VERSION ""

NS_ :

BS_:

BU_: RLPSU DPSU APSU PSB SHVU_RR vHS_B2 FCS EMCU SLB RCM CGW_CCU vDummy_HS_B ATS RLHV PFSU SGU ALBCU DSAU SWRC SHVU_FR RCS RRPSU BLTN_CAM SCM DLBCU OHCL RWPC RRHV WPC HOD ASAU

BO_ 934 PTGM_01_200ms: 8 CGW_CCU
 SG_ PTGM_Crc1Val : 0|8@1+ (1,0) [0|0] ""  Vector__XXX
 SG_ PTGM_AlvCnt1Val : 12|4@1+ (1,0) [0|0] ""  Vector__XXX
 SG_ PTGM_HazardSta : 16|2@1+ (1,0) [0|0] ""  Vector__XXX
 SG_ PTGM_ModSta : 18|2@1+ (1,0) [0|0] ""  Vector__XXX
 SG_ PTGM_MovSta : 20|2@1+ (1,0) [0|0] ""  Vector__XXX
 SG_ PTGM_OptTyp : 22|2@1+ (1,0) [0|0] ""  Vector__XXX
 SG_ PTGM_ReleaseRlySta : 24|2@1+ (1,0) [0|0] ""  APSU,PFSU
 SG_ PTGM_TrnkLkSwSta : 26|2@1+ (1,0) [0|0] ""  Vector__XXX
 SG_ PTGM_UsmSetSta : 28|2@1+ (1,0) [0|0] ""  Vector__XXX
 SG_ PTGM_HeightRValue : 32|3@1+ (1,0) [0|0] ""  Vector__XXX
 SG_ PTGM_OpnClsState : 35|4@1+ (1,0) [0|0] ""  Vector__XXX
 SG_ PTGM_CmdWarn : 40|3@1+ (1,0) [0|0] ""  Vector__XXX
 SG_ PTGM_AntiPinchSnsr : 43|2@1+ (1,0) [0|0] ""  Vector__XXX
 SG_ PTGM_FobSrch_Req : 52|2@1+ (1,0) [0|0] ""  Vector__XXX
 SG_ PTGM_TlgtAwayCloseRValue : 54|2@1+ (1,0) [0|0] ""  Vector__XXX
 SG_ PTGM_TrnkTlgtOption : 56|2@1+ (1,0) [0|0] ""  Vector__XXX
 SG_ PTGM_LatchType : 58|2@1+ (1,0) [0|0] ""  Vector__XXX
 SG_ PTGM_SpeedRValue : 8|4@1+ (1,0) [0|0] ""  Vector__XXX

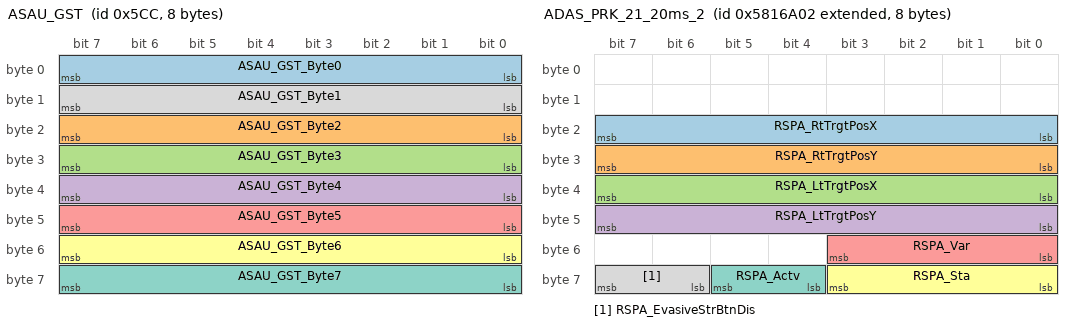
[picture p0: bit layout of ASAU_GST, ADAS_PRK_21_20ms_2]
BO_ 1484 ASAU_GST: 8 ASAU
 SG_ ASAU_GST_Byte0 : 0|8@1+ (1,0) [0|0] ""  CGW_CCU
 SG_ ASAU_GST_Byte2 : 16|8@1+ (1,0) [0|0] ""  CGW_CCU
 SG_ ASAU_GST_Byte3 : 24|8@1+ (1,0) [0|0] ""  CGW_CCU
 SG_ ASAU_GST_Byte4 : 32|8@1+ (1,0) [0|0] ""  CGW_CCU
 SG_ ASAU_GST_Byte5 : 40|8@1+ (1,0) [0|0] ""  CGW_CCU
 SG_ ASAU_GST_Byte6 : 48|8@1+ (1,0) [0|0] ""  CGW_CCU
 SG_ ASAU_GST_Byte7 : 56|8@1+ (1,0) [0|0] ""  CGW_CCU
 SG_ ASAU_GST_Byte1 : 8|8@1+ (1,0) [0|0] ""  CGW_CCU

BO_ 929 SCM_03_200ms: 8 SCM
 SG_ SCM_Opt : 0|2@1+ (1,0) [0|0] ""  DPSU,CGW_CCU
 SG_ Tilt_VirtualLimExist : 10|2@1+ (1,0) [0|0] ""  CGW_CCU
 SG_ Tele_Snsr_Err : 12|2@1+ (1,0) [0|0] ""  CGW_CCU
 SG_ Tele_VirtualLim : 14|2@1+ (1,0) [0|0] ""  CGW_CCU
 SG_ Tele_VirtualLimExist : 16|2@1+ (1,0) [0|0] ""  CGW_CCU
 SG_ TiltTele_Profile1MemoryExist : 18|2@1+ (1,0) [0|0] ""  CGW_CCU
 SG_ Tilt_MnlSwSta : 2|2@1+ (1,0) [0|0] ""  CGW_CCU
 SG_ TiltTele_Profile2MemoryExist : 20|2@1+ (1,0) [0|0] ""  CGW_CCU
 SG_ TiltTele_GuestMemoryExist : 22|2@1+ (1,0) [0|0] ""  CGW_CCU
 SG_ TiltTele_IMS1MemoryExist : 24|2@1+ (1,0) [0|0] ""  CGW_CCU
 SG_ TiltTele_IMS2MemoryExist : 26|2@1+ (1,0) [0|0] ""  CGW_CCU
 SG_ TiltTele_IMS3MemoryExist : 28|2@1+ (1,0) [0|0] ""  CGW_CCU
 SG_ TiltTele_ReturnMemoryExist : 30|2@1+ (1,0) [0|0] ""  CGW_CCU
 SG_ Tilt_OpSta : 32|2@1+ (1,0) [0|0] ""  CGW_CCU
 SG_ Tele_OpSta : 34|2@1+ (1,0) [0|0] ""  CGW_CCU
 SG_ Tele_MnlSwSta : 4|2@1+ (1,0) [0|0] ""  CGW_CCU
 SG_ Tilt_SnsrErr : 6|2@1+ (1,0) [0|0] ""  CGW_CCU
 SG_ Tilt_VirtualLim : 8|2@1+ (1,0) [0|0] ""  CGW_CCU

BO_ 2239851010 ADAS_PRK_21_20ms_2: 8 CGW_CCU
 SG_ RSPA_RtTrgtPosX : 16|8@1- (0.05,0) [0|0] "m"  Vector__XXX
 SG_ RSPA_RtTrgtPosY : 24|8@1- (0.05,0) [0|0] "m"  Vector__XXX
 SG_ RSPA_LtTrgtPosX : 32|8@1- (0.05,0) [0|0] "m"  Vector__XXX
 SG_ RSPA_LtTrgtPosY : 40|8@1- (0.05,0) [0|0] "m"  Vector__XXX
 SG_ RSPA_Var : 48|4@1+ (1,0) [0|0] ""  Vector__XXX
 SG_ RSPA_Sta : 56|4@1+ (1,0) [0|0] ""  Vector__XXX
 SG_ RSPA_Actv : 60|2@1+ (1,0) [0|0] ""  Vector__XXX
 SG_ RSPA_EvasiveStrBtnDis : 62|2@1+ (1,0) [0|0] ""  Vector__XXX

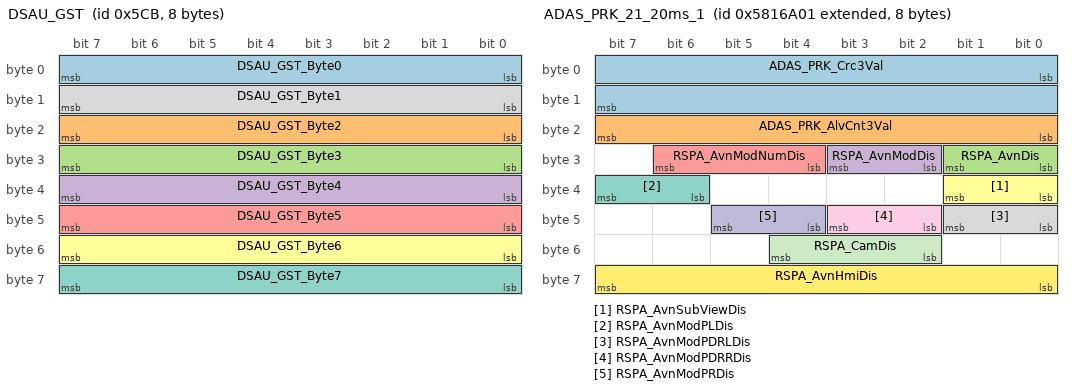
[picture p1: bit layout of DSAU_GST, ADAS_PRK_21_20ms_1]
BO_ 1483 DSAU_GST: 8 DSAU
 SG_ DSAU_GST_Byte0 : 0|8@1+ (1,0) [0|0] ""  CGW_CCU
 SG_ DSAU_GST_Byte2 : 16|8@1+ (1,0) [0|0] ""  CGW_CCU
 SG_ DSAU_GST_Byte3 : 24|8@1+ (1,0) [0|0] ""  CGW_CCU
 SG_ DSAU_GST_Byte4 : 32|8@1+ (1,0) [0|0] ""  CGW_CCU
 SG_ DSAU_GST_Byte5 : 40|8@1+ (1,0) [0|0] ""  CGW_CCU
 SG_ DSAU_GST_Byte6 : 48|8@1+ (1,0) [0|0] ""  CGW_CCU
 SG_ DSAU_GST_Byte7 : 56|8@1+ (1,0) [0|0] ""  CGW_CCU
 SG_ DSAU_GST_Byte1 : 8|8@1+ (1,0) [0|0] ""  CGW_CCU

BO_ 2239851011 ADAS_PRK_21_20ms_3: 8 CGW_CCU
 SG_ RSPA_TrgtGearSta : 0|3@1+ (1,0) [0|0] ""  Vector__XXX
 SG_ RSPA_IdOutWarnReq : 10|2@1+ (1,0) [0|0] ""  DPSU
 SG_ RSPA_IndBlnkReq : 12|3@1+ (1,0) [0|0] ""  Vector__XXX
 SG_ RSPA_SysOff : 15|1@1+ (1,0) [0|0] ""  Vector__XXX
 SG_ RSPA_DccCmd : 16|2@1+ (1,0) [0|0] ""  Vector__XXX
 SG_ RSPA_StopReq : 18|2@1+ (1,0) [0|0] ""  Vector__XXX
 SG_ RSPA_SelDevInfo : 20|2@1+ (1,0) [0|0] ""  Vector__XXX
 SG_ RSPA_SelFuncInfo : 22|2@1+ (1,0) [0|0] ""  Vector__XXX
 SG_ RSPA_TrgtVehSpdVal : 24|10@1+ (0.01,0) [0|0] "km/h"  Vector__XXX
 SG_ RSPA_EpbReq : 3|2@1+ (1,0) [0|0] ""  Vector__XXX
 SG_ RSPA_AddtnlAccelActv : 34|2@1+ (1,0) [0|0] ""  Vector__XXX
 SG_ RSPA_Opt : 36|2@1+ (1,0) [0|0] ""  Vector__XXX
 SG_ RSPA_RmtPrlExitDis : 38|2@1+ (1,0) [0|0] ""  Vector__XXX
 SG_ RSPA_TrgtTqVal : 40|12@1- (1,0) [0|0] "Nm"  Vector__XXX
 SG_ RSPA_ExtLampReq : 5|3@1+ (1,0) [0|0] ""  Vector__XXX
 SG_ RSPA_UppLtTypDis : 52|3@1+ (1,0) [0|0] ""  Vector__XXX
 SG_ RSPA_LwrLtTypDis : 55|3@1+ (1,0) [0|0] ""  Vector__XXX
 SG_ RSPA_UppRtTypDis : 58|3@1+ (1,0) [0|0] ""  Vector__XXX
 SG_ RSPA_LwrRtTypDis : 61|3@1+ (1,0) [0|0] ""  Vector__XXX
 SG_ RSPA_CrankingReq : 8|2@1+ (1,0) [0|0] ""  Vector__XXX

BO_ 2239851009 ADAS_PRK_21_20ms_1: 8 CGW_CCU
 SG_ ADAS_PRK_Crc3Val : 0|16@1+ (1,0) [0|0] ""  Vector__XXX
 SG_ ADAS_PRK_AlvCnt3Val : 16|8@1+ (1,0) [0|0] ""  Vector__XXX
 SG_ RSPA_AvnDis : 24|2@1+ (1,0) [0|0] ""  Vector__XXX
 SG_ RSPA_AvnModDis : 26|2@1+ (1,0) [0|0] ""  Vector__XXX
 SG_ RSPA_AvnModNumDis : 28|3@1+ (1,0) [0|0] ""  Vector__XXX
 SG_ RSPA_AvnSubViewDis : 32|2@1+ (1,0) [0|0] ""  Vector__XXX
 SG_ RSPA_AvnModPLDis : 38|2@1+ (1,0) [0|0] ""  Vector__XXX
 SG_ RSPA_AvnModPDRLDis : 40|2@1+ (1,0) [0|0] ""  Vector__XXX
 SG_ RSPA_AvnModPDRRDis : 42|2@1+ (1,0) [0|0] ""  Vector__XXX
 SG_ RSPA_AvnModPRDis : 44|2@1+ (1,0) [0|0] ""  Vector__XXX
 SG_ RSPA_CamDis : 50|3@1+ (1,0) [0|0] ""  Vector__XXX
 SG_ RSPA_AvnHmiDis : 56|8@1+ (1,0) [0|0] ""  Vector__XXX

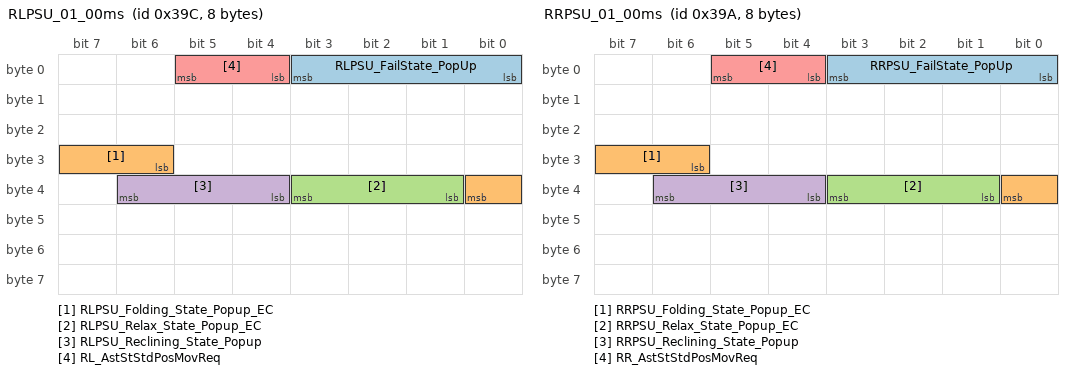
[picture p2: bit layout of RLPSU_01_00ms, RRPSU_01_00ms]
BO_ 924 RLPSU_01_00ms: 8 RLPSU
 SG_ RLPSU_FailState_PopUp : 0|4@1+ (1,0) [0|0] ""  CGW_CCU
 SG_ RLPSU_Folding_State_Popup_EC : 30|3@1+ (1,0) [0|0] ""  CGW_CCU
 SG_ RLPSU_Relax_State_Popup_EC : 33|3@1+ (1,0) [0|0] ""  CGW_CCU
 SG_ RLPSU_Reclining_State_Popup : 36|3@1+ (1,0) [0|0] ""  Vector__XXX
 SG_ RL_AstStStdPosMovReq : 4|2@1+ (1,0) [0|0] ""  APSU

BO_ 922 RRPSU_01_00ms: 8 RRPSU
 SG_ RRPSU_FailState_PopUp : 0|4@1+ (1,0) [0|0] ""  CGW_CCU
 SG_ RRPSU_Folding_State_Popup_EC : 30|3@1+ (1,0) [0|0] ""  CGW_CCU
 SG_ RRPSU_Relax_State_Popup_EC : 33|3@1+ (1,0) [0|0] ""  CGW_CCU
 SG_ RRPSU_Reclining_State_Popup : 36|3@1+ (1,1) [0|0] ""  Vector__XXX
 SG_ RR_AstStStdPosMovReq : 4|2@1+ (1,0) [0|0] ""  APSU

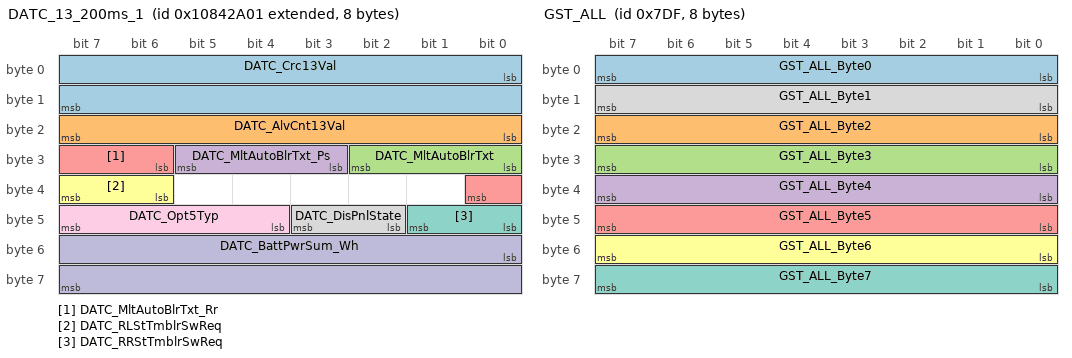
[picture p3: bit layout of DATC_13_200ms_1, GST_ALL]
BO_ 2424580609 DATC_13_200ms_1: 8 CGW_CCU
 SG_ DATC_Crc13Val : 0|16@1+ (1,0) [0|0] ""  Vector__XXX
 SG_ DATC_AlvCnt13Val : 16|8@1+ (1,0) [0|0] ""  Vector__XXX
 SG_ DATC_MltAutoBlrTxt : 24|3@1+ (1,0) [0|0] ""  ATS
 SG_ DATC_MltAutoBlrTxt_Ps : 27|3@1+ (1,0) [0|0] ""  ATS
 SG_ DATC_MltAutoBlrTxt_Rr : 30|3@1+ (1,0) [0|0] ""  ATS
 SG_ DATC_RLStTmblrSwReq : 38|2@1+ (1,0) [0|0] ""  RLHV,RRHV,SHVU_FR,SHVU_RR,RRPSU,RLPSU
 SG_ DATC_RRStTmblrSwReq : 40|2@1+ (1,0) [0|0] ""  RRHV,SHVU_FR,SHVU_RR,RRPSU,RLPSU
 SG_ DATC_DisPnlState : 42|2@1+ (1,0) [0|0] ""  Vector__XXX
 SG_ DATC_Opt5Typ : 44|4@1+ (1,0) [0|0] ""  ATS
 SG_ DATC_BattPwrSum_Wh : 48|16@1+ (1,0) [0|0] "Wh"  Vector__XXX

BO_ 915 BCM_18_200ms: 8 CGW_CCU
 SG_ BCM_Crc18Val : 0|8@1+ (1,0) [0|0] ""  Vector__XXX
 SG_ BCM_AlvCnt18Val : 12|4@1+ (1,0) [0|0] ""  Vector__XXX
 SG_ Trunk_IBU_OpnDiagSetSta : 16|2@1+ (1,0) [0|0] ""  Vector__XXX
 SG_ Trunk_TrnkTlgtReleaseRly : 18|2@1+ (1,0) [0|0] ""  Vector__XXX
 SG_ Trunk_TrnkTlgtOpenOutput_PTGM : 20|2@1+ (1,0) [0|0] ""  Vector__XXX
 SG_ Trunk_TrnkTlgtOpenOutput_ICU : 22|2@1+ (1,0) [0|0] ""  Vector__XXX
 SG_ Trunk_TrnkPassiveOpenOutput : 24|2@1+ (1,0) [0|0] ""  Vector__XXX
 SG_ TiltTele_CurProfileState : 26|3@1+ (1,0) [0|0] ""  SCM
 SG_ TiltTele_USMEsyAcsSetState : 29|2@1+ (1,0) [0|0] ""  DPSU
 SG_ TiltTele_PreEsyAcsProfile : 31|3@1+ (1,0) [0|0] ""  SCM
 SG_ Tilt_MnlInitCmd : 34|2@1+ (1,0) [0|0] ""  SCM
 SG_ Tilt_MnlOpCmd : 36|2@1+ (1,0) [0|0] ""  SCM
 SG_ Tele_MnlInitCmd : 38|2@1+ (1,0) [0|0] ""  SCM
 SG_ Tilt_AutoOpCmd : 40|4@1+ (1,0) [0|0] ""  SCM
 SG_ TiltTele_PlyBckState : 44|4@1+ (1,0) [0|0] ""  DPSU
 SG_ Tele_MnlOpCmd : 48|2@1+ (1,0) [0|0] ""  SCM
 SG_ Tele_AutoOpCmd : 52|4@1+ (1,0) [0|0] ""  SCM

BO_ 2015 GST_ALL: 8 CGW_CCU
 SG_ GST_ALL_Byte0 : 0|8@1+ (1,0) [0|0] ""  FCS,SCM,WPC,RWPC,PSB,SLB,SWRC,APSU,RLHV,RRHV,SHVU_FR,SHVU_RR,DPSU,DLBCU,PFSU,RCS,RRPSU,RLPSU,HOD,ATS,DSAU,ASAU,RCM,EMCU,SGU,ALBCU
 SG_ GST_ALL_Byte2 : 16|8@1+ (1,0) [0|0] ""  FCS,SCM,WPC,RWPC,PSB,SLB,SWRC,APSU,RLHV,RRHV,SHVU_FR,SHVU_RR,DPSU,DLBCU,PFSU,RCS,RRPSU,RLPSU,HOD,ATS,DSAU,ASAU,RCM,EMCU,SGU,ALBCU
 SG_ GST_ALL_Byte3 : 24|8@1+ (1,0) [0|0] ""  FCS,SCM,WPC,RWPC,PSB,SLB,SWRC,APSU,RLHV,RRHV,SHVU_FR,SHVU_RR,DPSU,DLBCU,PFSU,RCS,RRPSU,RLPSU,HOD,ATS,DSAU,ASAU,RCM,EMCU,SGU,ALBCU
 SG_ GST_ALL_Byte4 : 32|8@1+ (1,0) [0|0] ""  FCS,SCM,WPC,RWPC,PSB,SLB,SWRC,APSU,RLHV,RRHV,SHVU_FR,SHVU_RR,DPSU,DLBCU,PFSU,RCS,RRPSU,RLPSU,HOD,ATS,DSAU,ASAU,RCM,EMCU,SGU,ALBCU
 SG_ GST_ALL_Byte5 : 40|8@1+ (1,0) [0|0] ""  FCS,SCM,WPC,RWPC,PSB,SLB,SWRC,APSU,RLHV,RRHV,SHVU_FR,SHVU_RR,DPSU,DLBCU,PFSU,RCS,RRPSU,RLPSU,HOD,ATS,DSAU,ASAU,RCM,EMCU,SGU,ALBCU
 SG_ GST_ALL_Byte6 : 48|8@1+ (1,0) [0|0] ""  FCS,SCM,WPC,RWPC,PSB,SLB,SWRC,APSU,RLHV,RRHV,SHVU_FR,SHVU_RR,DPSU,DLBCU,PFSU,RCS,RRPSU,RLPSU,HOD,ATS,DSAU,ASAU,RCM,EMCU,SGU,ALBCU
 SG_ GST_ALL_Byte7 : 56|8@1+ (1,0) [0|0] ""  FCS,SCM,WPC,RWPC,PSB,SLB,SWRC,APSU,RLHV,RRHV,SHVU_FR,SHVU_RR,DPSU,DLBCU,PFSU,RCS,RRPSU,RLPSU,HOD,ATS,DSAU,ASAU,RCM,EMCU,SGU,ALBCU
 SG_ GST_ALL_Byte1 : 8|8@1+ (1,0) [0|0] ""  FCS,SCM,WPC,RWPC,PSB,SLB,SWRC,APSU,RLHV,RRHV,SHVU_FR,SHVU_RR,DPSU,DLBCU,PFSU,RCS,RRPSU,RLPSU,HOD,ATS,DSAU,ASAU,RCM,EMCU,SGU,ALBCU

BO_ 912 HU_BLTN_CAM_PE_00_200ms: 8 CGW_CCU
 SG_ HU_BLTN_CAM_UI_Mode : 0|4@1+ (1,0) [0|0] ""  BLTN_CAM
 SG_ HU_BLTN_CAM_Display : 4|3@1+ (1,0) [0|0] ""  BLTN_CAM

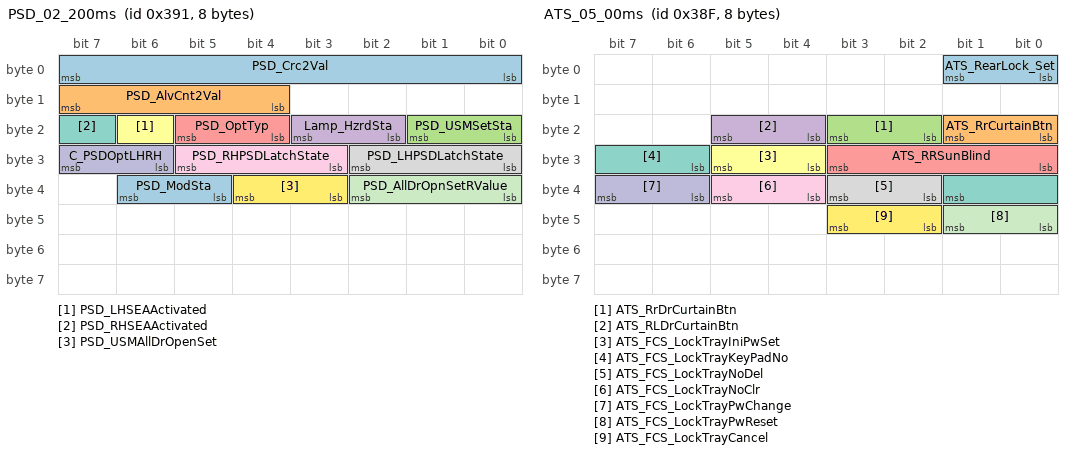
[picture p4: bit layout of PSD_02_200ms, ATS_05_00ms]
BO_ 913 PSD_02_200ms: 8 CGW_CCU
 SG_ PSD_Crc2Val : 0|8@1+ (1,0) [0|0] ""  Vector__XXX
 SG_ PSD_AlvCnt2Val : 12|4@1+ (1,0) [0|0] ""  Vector__XXX
 SG_ PSD_USMSetSta : 16|2@1+ (1,0) [0|0] ""  Vector__XXX
 SG_ Lamp_HzrdSta : 18|2@1+ (1,0) [0|0] ""  Vector__XXX
 SG_ PSD_OptTyp : 20|2@1+ (1,0) [0|0] ""  Vector__XXX
 SG_ PSD_LHSEAActivated : 22|1@1+ (1,0) [0|0] ""  Vector__XXX
 SG_ PSD_RHSEAActivated : 23|1@1+ (1,0) [0|0] ""  Vector__XXX
 SG_ PSD_LHPSDLatchState : 24|3@1+ (1,0) [0|0] ""  PFSU
 SG_ PSD_RHPSDLatchState : 27|3@1+ (1,0) [0|0] ""  PFSU
 SG_ C_PSDOptLHRH : 30|2@1+ (1,0) [0|0] ""  Vector__XXX
 SG_ PSD_AllDrOpnSetRValue : 32|3@1+ (1,0) [0|0] ""  Vector__XXX
 SG_ PSD_USMAllDrOpenSet : 35|2@1+ (1,0) [0|0] ""  Vector__XXX
 SG_ PSD_ModSta : 37|2@1+ (1,0) [0|0] ""  Vector__XXX

BO_ 911 ATS_05_00ms: 8 ATS
 SG_ ATS_RearLock_Set : 0|2@1+ (1,0) [0|0] ""  CGW_CCU
 SG_ ATS_RrCurtainBtn : 16|2@1+ (1,0) [0|0] ""  CGW_CCU
 SG_ ATS_RrDrCurtainBtn : 18|2@1+ (1,0) [0|0] ""  Vector__XXX
 SG_ ATS_RLDrCurtainBtn : 20|2@1+ (1,0) [0|0] ""  Vector__XXX
 SG_ ATS_RRSunBlind : 24|4@1+ (1,0) [0|0] ""  RCM,CGW_CCU
 SG_ ATS_FCS_LockTrayIniPwSet : 28|2@1+ (1,0) [0|0] ""  FCS
 SG_ ATS_FCS_LockTrayKeyPadNo : 30|4@1+ (1,0) [0|0] ""  FCS
 SG_ ATS_FCS_LockTrayNoDel : 34|2@1+ (1,0) [0|0] ""  FCS
 SG_ ATS_FCS_LockTrayNoClr : 36|2@1+ (1,0) [0|0] ""  FCS
 SG_ ATS_FCS_LockTrayPwChange : 38|2@1+ (1,0) [0|0] ""  FCS
 SG_ ATS_FCS_LockTrayPwReset : 40|2@1+ (1,0) [0|0] ""  FCS
 SG_ ATS_FCS_LockTrayCancel : 42|2@1+ (1,0) [0|0] ""  FCS

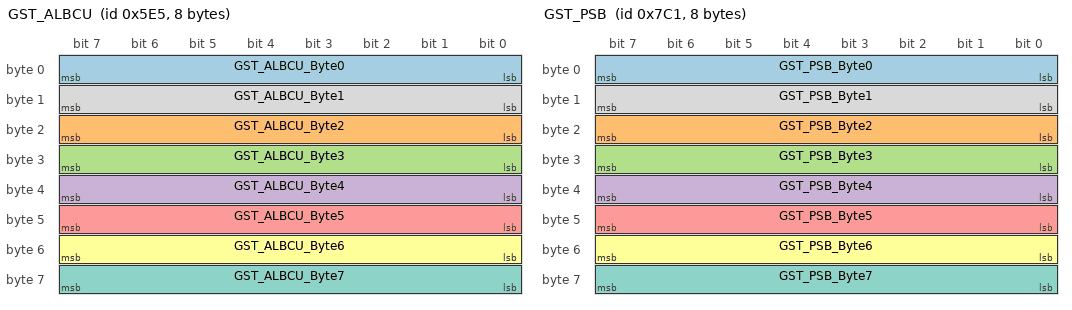
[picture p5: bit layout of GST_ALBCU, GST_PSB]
BO_ 1509 GST_ALBCU: 8 CGW_CCU
 SG_ GST_ALBCU_Byte0 : 0|8@1+ (1,0) [0|0] ""  ALBCU
 SG_ GST_ALBCU_Byte2 : 16|8@1+ (1,0) [0|0] ""  ALBCU
 SG_ GST_ALBCU_Byte3 : 24|8@1+ (1,0) [0|0] ""  ALBCU
 SG_ GST_ALBCU_Byte4 : 32|8@1+ (1,0) [0|0] ""  ALBCU
 SG_ GST_ALBCU_Byte5 : 40|8@1+ (1,0) [0|0] ""  ALBCU
 SG_ GST_ALBCU_Byte6 : 48|8@1+ (1,0) [0|0] ""  ALBCU
 SG_ GST_ALBCU_Byte7 : 56|8@1+ (1,0) [0|0] ""  ALBCU
 SG_ GST_ALBCU_Byte1 : 8|8@1+ (1,0) [0|0] ""  ALBCU

BO_ 1985 GST_PSB: 8 CGW_CCU
 SG_ GST_PSB_Byte0 : 0|8@1+ (1,0) [0|0] ""  PSB
 SG_ GST_PSB_Byte2 : 16|8@1+ (1,0) [0|0] ""  PSB
 SG_ GST_PSB_Byte3 : 24|8@1+ (1,0) [0|0] ""  PSB
 SG_ GST_PSB_Byte4 : 32|8@1+ (1,0) [0|0] ""  PSB
 SG_ GST_PSB_Byte5 : 40|8@1+ (1,0) [0|0] ""  PSB
 SG_ GST_PSB_Byte6 : 48|8@1+ (1,0) [0|0] ""  PSB
 SG_ GST_PSB_Byte7 : 56|8@1+ (1,0) [0|0] ""  PSB
 SG_ GST_PSB_Byte1 : 8|8@1+ (1,0) [0|0] ""  PSB

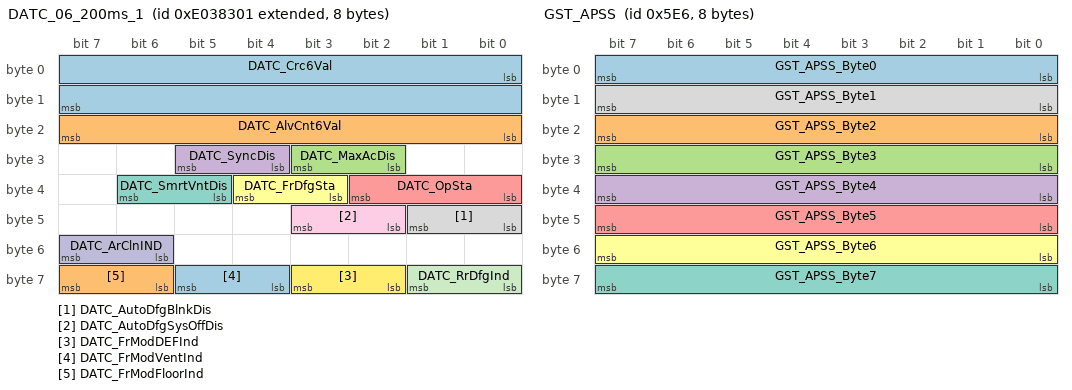
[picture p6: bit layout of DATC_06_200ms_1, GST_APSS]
BO_ 2382594817 DATC_06_200ms_1: 8 CGW_CCU
 SG_ DATC_Crc6Val : 0|16@1+ (1,0) [0|0] ""  Vector__XXX
 SG_ DATC_AlvCnt6Val : 16|8@1+ (1,0) [0|0] ""  Vector__XXX
 SG_ DATC_MaxAcDis : 26|2@1+ (1,0) [0|0] ""  Vector__XXX
 SG_ DATC_SyncDis : 28|2@1+ (1,0) [0|0] ""  ATS
 SG_ DATC_OpSta : 32|3@1+ (1,0) [0|0] ""  ATS
 SG_ DATC_FrDfgSta : 35|2@1+ (1,0) [0|0] ""  Vector__XXX
 SG_ DATC_SmrtVntDis : 37|2@1+ (1,0) [0|0] ""  Vector__XXX
 SG_ DATC_AutoDfgBlnkDis : 40|2@1+ (1,0) [0|0] ""  Vector__XXX
 SG_ DATC_AutoDfgSysOffDis : 42|2@1+ (1,0) [0|0] ""  Vector__XXX
 SG_ DATC_ArClnIND : 54|2@1+ (1,0) [0|0] ""  ATS
 SG_ DATC_RrDfgInd : 56|2@1+ (1,0) [0|0] ""  Vector__XXX
 SG_ DATC_FrModDEFInd : 58|2@1+ (1,0) [0|0] ""  Vector__XXX
 SG_ DATC_FrModVentInd : 60|2@1+ (1,0) [0|0] ""  Vector__XXX
 SG_ DATC_FrModFloorInd : 62|2@1+ (1,0) [0|0] ""  Vector__XXX

BO_ 1510 GST_APSS: 8 CGW_CCU
 SG_ GST_APSS_Byte0 : 0|8@1+ (1,0) [0|0] ""  APSU
 SG_ GST_APSS_Byte2 : 16|8@1+ (1,0) [0|0] ""  APSU
 SG_ GST_APSS_Byte3 : 24|8@1+ (1,0) [0|0] ""  APSU
 SG_ GST_APSS_Byte4 : 32|8@1+ (1,0) [0|0] ""  APSU
 SG_ GST_APSS_Byte5 : 40|8@1+ (1,0) [0|0] ""  APSU
 SG_ GST_APSS_Byte6 : 48|8@1+ (1,0) [0|0] ""  APSU
 SG_ GST_APSS_Byte7 : 56|8@1+ (1,0) [0|0] ""  APSU
 SG_ GST_APSS_Byte1 : 8|8@1+ (1,0) [0|0] ""  APSU

BO_ 905 SBCM_RR_01_200ms: 8 CGW_CCU
 SG_ SBCM_RR_Crc1Val : 0|8@1+ (1,0) [0|0] ""  Vector__XXX
 SG_ RR_CrashUnlockCmd : 10|1@1+ (1,0) [0|0] ""  BLTN_CAM
 SG_ SBCM_RR_AlvCnt1Val : 12|4@1+ (1,0) [0|0] ""  Vector__XXX
 SG_ Warn_RrRtDrSwSta_SBCM : 16|2@1+ (1,0) [0|0] ""  WPC,RWPC,APSU,RRPSU,ATS,BLTN_CAM
 SG_ DoorLock_RrRtDrUnLkSta_SBCM : 18|2@1+ (1,0) [0|0] ""  ATS
 SG_ RR_SEAActivated : 20|2@1+ (1,0) [0|0] ""  Vector__XXX
 SG_ RR_SEAWarn : 22|2@1+ (1,0) [0|0] ""  Vector__XXX
 SG_ RR_SEWWarn : 24|2@1+ (1,0) [0|0] ""  Vector__XXX
 SG_ RR_ReleaseWarn : 26|2@1+ (1,0) [0|0] ""  Vector__XXX
 SG_ RR_SWFailAlarm : 28|2@1+ (1,0) [0|0] ""  Vector__XXX
 SG_ RR_ChildLock_ActnFlSta : 30|2@1+ (1,0) [0|0] ""  Vector__XXX
 SG_ RR_MRActivationAlarm : 32|2@1+ (1,0) [0|0] ""  Vector__XXX
 SG_ RR_ChildLock_Status : 34|2@1+ (1,0) [0|0] ""  Vector__XXX
 SG_ USM_RRGhostDoorSta : 36|2@1+ (1,0) [0|0] ""  Vector__XXX
 SG_ DoorLock_PDSLkSwSta_RR : 40|2@1+ (1,0) [0|0] ""  Vector__XXX
 SG_ PDS_TypeOption_RR : 42|2@1+ (1,0) [0|0] ""  Vector__XXX
 SG_ RRDoorPushAlarm : 8|2@1+ (1,0) [0|0] ""  Vector__XXX

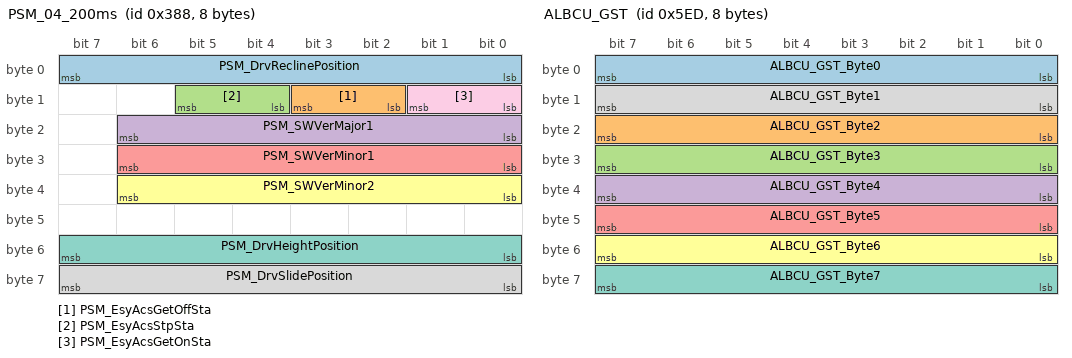
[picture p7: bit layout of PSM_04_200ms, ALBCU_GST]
BO_ 904 PSM_04_200ms: 8 DPSU
 SG_ PSM_DrvReclinePosition : 0|8@1+ (1,0) [0|0] ""  CGW_CCU
 SG_ PSM_EsyAcsGetOffSta : 10|2@1+ (1,0) [0|0] ""  DLBCU,DSAU
 SG_ PSM_EsyAcsStpSta : 12|2@1+ (1,0) [0|0] ""  DLBCU,DSAU
 SG_ PSM_SWVerMajor1 : 16|7@1+ (1,0) [0|0] ""  CGW_CCU
 SG_ PSM_SWVerMinor1 : 24|7@1+ (1,0) [0|0] ""  CGW_CCU
 SG_ PSM_SWVerMinor2 : 32|7@1+ (1,0) [0|0] ""  CGW_CCU
 SG_ PSM_DrvHeightPosition : 48|8@1+ (1,0) [0|0] ""  CGW_CCU
 SG_ PSM_DrvSlidePosition : 56|8@1+ (1,0) [0|0] ""  CGW_CCU
 SG_ PSM_EsyAcsGetOnSta : 8|2@1+ (1,0) [0|0] ""  DLBCU,DSAU

BO_ 903 PSM_03_200ms: 8 DPSU
 SG_ PSM_DrvStSldFwdDis : 0|2@1+ (1,0) [0|0] ""  CGW_CCU
 SG_ PSM_DrvStTiltDnDis : 10|2@1+ (1,0) [0|0] ""  CGW_CCU
 SG_ PSM_DrvStHghtUpDis : 12|2@1+ (1,0) [0|0] ""  CGW_CCU
 SG_ PSM_DrvStHghtDnDis : 14|2@1+ (1,0) [0|0] ""  CGW_CCU
 SG_ PSM_DrvStCushExtBckwdDis : 16|2@1+ (1,0) [0|0] ""  CGW_CCU
 SG_ PSM_DrvStCushExtFwdDis : 18|2@1+ (1,0) [0|0] ""  CGW_CCU
 SG_ PSM_DrvStSldBckwdDis : 2|2@1+ (1,0) [0|0] ""  CGW_CCU
 SG_ PSM_DrvStHdRstUpDis : 20|2@1+ (1,0) [0|0] ""  CGW_CCU
 SG_ PSM_DrvStHdRstDnDis : 22|2@1+ (1,0) [0|0] ""  CGW_CCU
 SG_ PSM_DrvStHdRstFwdDis : 24|2@1+ (1,0) [0|0] ""  CGW_CCU
 SG_ PSM_DrvStHdRstBckwdDis : 26|2@1+ (1,0) [0|0] ""  CGW_CCU
 SG_ PSM_DrvStLmbrDefDis : 32|2@1+ (1,0) [0|0] ""  CGW_CCU
 SG_ PSM_DrvStLmbrLoDis : 34|2@1+ (1,0) [0|0] ""  CGW_CCU
 SG_ PSM_DrvStLmbrMdlDis : 36|2@1+ (1,0) [0|0] ""  CGW_CCU
 SG_ PSM_DrvStLmbrUpDis : 38|2@1+ (1,0) [0|0] ""  CGW_CCU
 SG_ PSM_DrvStReclneFwdDis : 4|2@1+ (1,0) [0|0] ""  CGW_CCU
 SG_ PSM_DrvStBlstrDefDis : 40|2@1+ (1,0) [0|0] ""  CGW_CCU
 SG_ PSM_DrvStBlstrInfDis : 42|2@1+ (1,0) [0|0] ""  CGW_CCU
 SG_ PSM_DrvStReclneBckwdDis : 6|2@1+ (1,0) [0|0] ""  CGW_CCU
 SG_ PSM_DrvStTiltUpDis : 8|2@1+ (1,0) [0|0] ""  CGW_CCU

BO_ 1517 ALBCU_GST: 8 ALBCU
 SG_ ALBCU_GST_Byte0 : 0|8@1+ (1,0) [0|0] ""  CGW_CCU
 SG_ ALBCU_GST_Byte2 : 16|8@1+ (1,0) [0|0] ""  CGW_CCU
 SG_ ALBCU_GST_Byte3 : 24|8@1+ (1,0) [0|0] ""  CGW_CCU
 SG_ ALBCU_GST_Byte4 : 32|8@1+ (1,0) [0|0] ""  CGW_CCU
 SG_ ALBCU_GST_Byte5 : 40|8@1+ (1,0) [0|0] ""  CGW_CCU
 SG_ ALBCU_GST_Byte6 : 48|8@1+ (1,0) [0|0] ""  CGW_CCU
 SG_ ALBCU_GST_Byte7 : 56|8@1+ (1,0) [0|0] ""  CGW_CCU
 SG_ ALBCU_GST_Byte1 : 8|8@1+ (1,0) [0|0] ""  CGW_CCU

BO_ 902 PSM_02_200ms: 8 DPSU
 SG_ PSM_DrvStEsyAcsUSMSta : 0|3@1+ (1,0) [0|0] ""  DLBCU,DSAU,CGW_CCU
 SG_ PSM_SeatPosPlyBck_Sta : 10|3@1+ (1,0) [0|0] ""  Vector__XXX
 SG_ PSM_SeatPos_Sta : 13|3@1+ (1,0) [0|0] ""  Vector__XXX
 SG_ PSM_SeatPosSldLmt_Sta : 16|2@1+ (1,0) [0|0] ""  CGW_CCU
 SG_ PSM_SeatPosRclnLmt_Sta : 18|2@1+ (1,0) [0|0] ""  CGW_CCU
 SG_ SmrtIMS_StatureRspVal : 24|4@1+ (1,0) [0|0] ""  CGW_CCU
 SG_ SmrtIMS_SeatedHghtRspVal : 28|4@1+ (1,0) [0|0] ""  CGW_CCU
 SG_ SmrtIMS_WghtRspVal : 32|4@1+ (1,0) [0|0] ""  CGW_CCU
 SG_ SmartIMS_DisReq : 36|3@1+ (1,0) [0|0] ""  CGW_CCU
 SG_ SmrtIMS_ExitSta : 40|3@1+ (1,0) [0|0] ""  CGW_CCU
 SG_ PSM_DrvStRlxTiltUpDis : 43|2@1+ (1,0) [0|0] ""  CGW_CCU
 SG_ PSM_DrvStRlxTiltDnDis : 45|2@1+ (1,0) [0|0] ""  CGW_CCU
 SG_ PSM_DrvStLegUpDis : 47|2@1+ (1,0) [0|0] ""  CGW_CCU
 SG_ PSM_DrvStLegDnDis : 49|2@1+ (1,0) [0|0] ""  CGW_CCU
 SG_ Drv_2ndStAutoRlxEnable : 57|2@1+ (1,0) [0|0] ""  RLPSU,RRPSU
 SG_ Drv_AutoRlxSta : 59|2@1+ (1,0) [0|0] ""  RLPSU,RRPSU,CGW_CCU
 SG_ Drv_AutoReturnSta : 61|2@1+ (1,0) [0|0] ""  CGW_CCU
 SG_ PSM_IMSOptTyp : 8|2@1+ (1,0) [0|0] ""  CGW_CCU

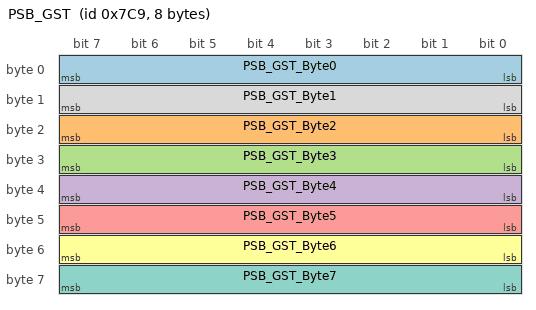
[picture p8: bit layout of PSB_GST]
BO_ 1993 PSB_GST: 8 PSB
 SG_ PSB_GST_Byte0 : 0|8@1+ (1,0) [0|0] ""  CGW_CCU
 SG_ PSB_GST_Byte2 : 16|8@1+ (1,0) [0|0] ""  CGW_CCU
 SG_ PSB_GST_Byte3 : 24|8@1+ (1,0) [0|0] ""  CGW_CCU
 SG_ PSB_GST_Byte4 : 32|8@1+ (1,0) [0|0] ""  CGW_CCU
 SG_ PSB_GST_Byte5 : 40|8@1+ (1,0) [0|0] ""  CGW_CCU
 SG_ PSB_GST_Byte6 : 48|8@1+ (1,0) [0|0] ""  CGW_CCU
 SG_ PSB_GST_Byte7 : 56|8@1+ (1,0) [0|0] ""  CGW_CCU
 SG_ PSB_GST_Byte1 : 8|8@1+ (1,0) [0|0] ""  CGW_CCU

BO_TX_BU_ 924 : RLPSU,RRPSU;
CM_ BO_ 2239851009 "[P] Periodic";
CM_ SG_ 2239851009 ADAS_PRK_Crc3Val "ADAS_PRK_CyclicRedundancyCheck3Value";
CM_ SG_ 2239851009 ADAS_PRK_AlvCnt3Val "ADAS_PRK_AliveCounter3Value";
CM_ SG_ 2239851009 RSPA_AvnDis "RSPA_AvnDisplay";
CM_ SG_ 2239851009 RSPA_AvnModDis "RSPA_AvnModeDisplay";
CM_ SG_ 2239851009 RSPA_AvnModNumDis "RSPA_AvnModeNumberDisplay";
CM_ SG_ 2239851009 RSPA_AvnSubViewDis "RSPA_AvnSubViewDisplay";
CM_ SG_ 2239851009 RSPA_AvnModPLDis "RSPA_AvnModeParallelLeftDisplay";
CM_ SG_ 2239851009 RSPA_AvnModPDRLDis "RSPA_AvnModPerpenDicularRearLeftDisplay";
CM_ SG_ 2239851009 RSPA_AvnModPDRRDis "RSPA_AvnModePerpenDicularRearRightDisplay";
CM_ SG_ 2239851009 RSPA_AvnModPRDis "RSPA_AvnModeParallelRightDisplay";
CM_ SG_ 2239851009 RSPA_CamDis "RSPA_CameraDisplay";
CM_ SG_ 2239851009 RSPA_AvnHmiDis "RSPA_AvnHmiDisplay";
CM_ BO_ 2239851010 "[P] Periodic";
CM_ SG_ 2239851010 RSPA_RtTrgtPosX "RSPA_RightTargetPosX";
CM_ SG_ 2239851010 RSPA_RtTrgtPosY "RSPA_RightTargetPosY";
CM_ SG_ 2239851010 RSPA_LtTrgtPosX "RSPA_LeftTargetPosX";
CM_ SG_ 2239851010 RSPA_LtTrgtPosY "RSPA_LeftTargetPosY";
CM_ SG_ 2239851010 RSPA_Var "RSPA_Variation";
CM_ SG_ 2239851010 RSPA_Sta "RSPA_Status";
CM_ SG_ 2239851010 RSPA_Actv "RSPA_Actvation";
CM_ SG_ 2239851010 RSPA_EvasiveStrBtnDis "RSPA_EvasiveSteeringButtonDisplay";
CM_ BO_ 2239851011 "[P] Periodic";
CM_ SG_ 2239851011 RSPA_TrgtGearSta "RSPA_TargetGearStatus";
CM_ SG_ 2239851011 RSPA_IdOutWarnReq "RSPA_IdOutWarningRequest";
CM_ SG_ 2239851011 RSPA_IndBlnkReq "RSPA_IndicatorBlinkingRequest";
CM_ SG_ 2239851011 RSPA_SysOff "RSPA System status flag";
CM_ SG_ 2239851011 RSPA_DccCmd "RSPA_DccelerationCommand";
CM_ SG_ 2239851011 RSPA_StopReq "RSPA_StopRequest";
CM_ SG_ 2239851011 RSPA_SelDevInfo "Selected Remote Device Information";
CM_ SG_ 2239851011 RSPA_SelFuncInfo "Selected RSPA Function Information";
CM_ SG_ 2239851011 RSPA_TrgtVehSpdVal "RSPA_TargetVehicleSpeedValue";
CM_ SG_ 2239851011 RSPA_EpbReq "RSPA_EPBRequest";
CM_ SG_ 2239851011 RSPA_AddtnlAccelActv "RSPA_AdditionalAccelarationActivation";
CM_ SG_ 2239851011 RSPA_Opt "RSPA_Option";
CM_ SG_ 2239851011 RSPA_RmtPrlExitDis "RSPA_RemoteParallelExitDisplay";
CM_ SG_ 2239851011 RSPA_TrgtTqVal "RSPA_TargetTorqueValue";
CM_ SG_ 2239851011 RSPA_ExtLampReq "RSPA_ExternalLampRequest";
CM_ SG_ 2239851011 RSPA_UppLtTypDis "RSPA_UpperLeftTypeDisplay";
CM_ SG_ 2239851011 RSPA_LwrLtTypDis "RSPA_LowerLeftTypeDisplay";
CM_ SG_ 2239851011 RSPA_UppRtTypDis "RSPA_UpperRightTypeDisplay";
CM_ SG_ 2239851011 RSPA_LwrRtTypDis "RSPA_LowerRightTypeDisplay";
CM_ SG_ 2239851011 RSPA_CrankingReq "RSPA_CrankingRequest";
CM_ BO_ 1517 "[TP] Transport Protocol";
CM_ BO_ 1484 "[TP] Transport Protocol";
CM_ SG_ 1484 ASAU_GST_Byte0 "Diag Response from ASAU";
CM_ SG_ 1484 ASAU_GST_Byte2 "Diag Response from ASAU";
CM_ SG_ 1484 ASAU_GST_Byte3 "Diag Response from ASAU";
CM_ SG_ 1484 ASAU_GST_Byte4 "Diag Response from ASAU";
CM_ SG_ 1484 ASAU_GST_Byte5 "Diag Response from ASAU";
CM_ SG_ 1484 ASAU_GST_Byte6 "Diag Response from ASAU";
CM_ SG_ 1484 ASAU_GST_Byte7 "Diag Response from ASAU";
CM_ SG_ 1484 ASAU_GST_Byte1 "Diag Response from ASAU";
CM_ BO_ 911 "[EC] On Event and On Change";
CM_ SG_ 911 ATS_RearLock_Set "RRC and RSE Lock Touch Button";
CM_ SG_ 911 ATS_RrCurtainBtn "Rear Curtain Touch Button";
CM_ SG_ 911 ATS_RrDrCurtainBtn "Rear Door and Curtain Touch Button";
CM_ SG_ 911 ATS_RLDrCurtainBtn "Rear Door and Curtain Touch Button";
CM_ SG_ 911 ATS_RRSunBlind "SunBlind Touch Botton";
CM_ SG_ 911 ATS_FCS_LockTrayIniPwSet "Locking Tray ºñ¹Ð¹øÈ£ ¼³Á¤ ÁøÀÔ ¹öÆ°";
CM_ SG_ 911 ATS_FCS_LockTrayKeyPadNo "Locking Tray ºñ¹Ð¹øÈ£ ¼³Á¤ key Pad ¹öÆ°";
CM_ SG_ 911 ATS_FCS_LockTrayNoDel "Locking Tray ºñ¹Ð¹øÈ£ ¼³Á¤ ¼ýÀÚ »èÁ¦ ¹öÆ°";
CM_ SG_ 911 ATS_FCS_LockTrayNoClr "Locking Tray ºñ¹Ð¹øÈ£ ¼³Á¤ ¼ýÀÚ Clear ¹öÆ°";
CM_ SG_ 911 ATS_FCS_LockTrayPwChange "Locking Tray ºñ¹Ð¹øÈ£ º¯°æ ÁøÀÔ ¹öÆ°";
CM_ SG_ 911 ATS_FCS_LockTrayPwReset "Locking Tray ºñ¹Ð¹øÈ£ ÃÊ±âÈ­ ÁøÀÔ ¹öÆ° (ºñ¹Ð¹øÈ£ ¾ø´Â »óÅÂ·Î ¿øº¹)";
CM_ SG_ 911 ATS_FCS_LockTrayCancel "Locking Tray ºñ¹Ð¹øÈ£ ÀÔ·Â È­¸é Cancel ¹öÆ°";
CM_ BO_ 915 "[PE] Periodic and On Event";
CM_ SG_ 915 BCM_Crc18Val "BCM_CyclicRedundancyCheck18Value";
CM_ SG_ 915 BCM_AlvCnt18Val "BCM_AliveCounter18Value";
CM_ SG_ 915 Trunk_IBU_OpnDiagSetSta "Trunk_OpenDiagnosticSettingStatus ##2G## -  - C_TrunkOpenDiagSet";
CM_ SG_ 915 Trunk_TrnkTlgtOpenOutput_PTGM "Trunk_TrunkTailgateOpenOutput for PTGM Trunk/Tailgate Open Command";
CM_ SG_ 915 Trunk_TrnkTlgtOpenOutput_ICU "Trunk_TrunkTailgateOpenOutput for ICU Trunk/Tailgate Open Command in PTG";
CM_ SG_ 915 Trunk_TrnkPassiveOpenOutput "Passive Trunk Open Output for ICU Passive Trunk Release Relay Command";
CM_ BO_ 2382594817 "[PE] Periodic and On Event";
CM_ SG_ 2382594817 DATC_Crc6Val "DATC_CyclicRedundancyCheck6Value";
CM_ SG_ 2382594817 DATC_AlvCnt6Val "DATC_AliveCounter6Value";
CM_ SG_ 2382594817 DATC_MaxAcDis "DATC_MaxACDisplay";
CM_ SG_ 2382594817 DATC_SyncDis "DATC_SyncDisplay";
CM_ SG_ 2382594817 DATC_OpSta "DATC_OperationStatus";
CM_ SG_ 2382594817 DATC_FrDfgSta "DATC_FrontDefogStatus";
CM_ SG_ 2382594817 DATC_SmrtVntDis "DATC_SmartVentilationDisplay";
CM_ SG_ 2382594817 DATC_AutoDfgBlnkDis "DATC_AutoDefogBlinkDisplay";
CM_ SG_ 2382594817 DATC_AutoDfgSysOffDis "DATC_AutoDefogSystemOffDisplay";
CM_ SG_ 2382594817 DATC_ArClnIND "DATC_AirCleanIndicator";
CM_ SG_ 2382594817 DATC_RrDfgInd "Rear Defog Switch indicator signal";
CM_ SG_ 2382594817 DATC_FrModDEFInd "Mode DEF button indicator status signal in case All Mode Button Type";
CM_ SG_ 2382594817 DATC_FrModVentInd "Mode VENT button indicator status signal in case ALL Mode Button Type";
CM_ SG_ 2382594817 DATC_FrModFloorInd "Mode FLOOR button indicator status signal in case ALL Mode Button Type";
CM_ BO_ 2424580609 "[PE] Periodic and On Event";
CM_ SG_ 2424580609 DATC_Crc13Val "DATC_CyclicRedundancyCheck13Value";
CM_ SG_ 2424580609 DATC_AlvCnt13Val "DATC_AliveCounter13Value";
CM_ SG_ 2424580609 DATC_MltAutoBlrTxt "This signal is to display text of Multi Auto Blower step";
CM_ SG_ 2424580609 DATC_MltAutoBlrTxt_Ps "This signal is to display text of Multi Auto Blower step";
CM_ SG_ 2424580609 DATC_MltAutoBlrTxt_Rr "This signal is to display text of Multi Auto Blower step";
CM_ SG_ 2424580609 DATC_RLStTmblrSwReq "DATC_RearLeftSeatTumblerSwitchRequest";
CM_ SG_ 2424580609 DATC_RRStTmblrSwReq "DATC_RearRightSeatTumblerSwitchRequest";
CM_ SG_ 2424580609 DATC_DisPnlState "This signal indicate whether FRONT Climate Display State or REAR Climate Display State";
CM_ SG_ 2424580609 DATC_Opt5Typ "HTR CONTROL OPTION";
CM_ SG_ 2424580609 DATC_BattPwrSum_Wh "accumulated energy consumption of battery while driving(200ms)";
CM_ BO_ 1483 "[TP] Transport Protocol";
CM_ SG_ 1483 DSAU_GST_Byte0 "Diag Response from DSAU";
CM_ SG_ 1483 DSAU_GST_Byte2 "Diag Response from DSAU";
CM_ SG_ 1483 DSAU_GST_Byte3 "Diag Response from DSAU";
CM_ SG_ 1483 DSAU_GST_Byte4 "Diag Response from DSAU";
CM_ SG_ 1483 DSAU_GST_Byte5 "Diag Response from DSAU";
CM_ SG_ 1483 DSAU_GST_Byte6 "Diag Response from DSAU";
CM_ SG_ 1483 DSAU_GST_Byte7 "Diag Response from DSAU";
CM_ SG_ 1483 DSAU_GST_Byte1 "Diag Response from DSAU";
CM_ BO_ 1509 "[TP] Transport Protocol";
CM_ BO_ 2015 "[TP] Transport Protocol";
CM_ BO_ 1510 "[TP] Transport Protocol";
CM_ BO_ 1985 "[TP] Transport Protocol";
CM_ BO_ 912 "[PE] Periodic and On Event";
CM_ SG_ 912 HU_BLTN_CAM_UI_Mode "Display control of Built-in Cam UI mode. This Signal for Ethernet Type Built-in Cam.";
CM_ SG_ 912 HU_BLTN_CAM_Display "Display control of Built-in Cam UI mode. This Signal for CAN Type Built-in Cam.(with Standard 5th Wide AVNT)";
CM_ BO_ 1993 "[TP] Transport Protocol";
CM_ BO_ 913 "[PE] Periodic and On Event";
CM_ SG_ 913 PSD_Crc2Val "PSD_CyclicRedundancyCheck2Value";
CM_ SG_ 913 PSD_AlvCnt2Val "PSD_AliveCounter2Value";
CM_ SG_ 913 Lamp_HzrdSta "Lamp_HazardStatus";
CM_ SG_ 913 PSD_OptTyp "PSD_OptionType";
CM_ SG_ 913 PSD_AllDrOpnSetRValue "All Door(PSD PTG) Open Function by FOB Unlock Long Key USM Setting Signal";
CM_ SG_ 913 PSD_USMAllDrOpenSet "All Door Open Function by FOB Unlock Long Key Setting Signal for PTG by PSD";
CM_ SG_ 913 PSD_ModSta "PSD Module Status";
CM_ BO_ 902 "[PE] Periodic and On Event";
CM_ SG_ 902 PSM_DrvStEsyAcsUSMSta "USM_MovingValue";
CM_ SG_ 902 PSM_SeatPosPlyBck_Sta "PSM_SeatPositionPlayBack_State";
CM_ SG_ 902 PSM_SeatPos_Sta "PSM_SeatPosition_State";
CM_ SG_ 902 PSM_SeatPosSldLmt_Sta "PSM_SeatPositionSlideLimitState";
CM_ SG_ 902 PSM_SeatPosRclnLmt_Sta "PSM_SeatPositionReclineLimitState";
CM_ SG_ 902 SmrtIMS_StatureRspVal "HCIMS_HeightRsponseValue";
CM_ SG_ 902 SmrtIMS_SeatedHghtRspVal "HCIMS_SitHeightRsponseValue";
CM_ SG_ 902 SmrtIMS_WghtRspVal "HCIMS_WeightRsponseValue";
CM_ SG_ 902 SmartIMS_DisReq "PSM_MoveStatusDisplay";
CM_ SG_ 902 SmrtIMS_ExitSta "Smart IMS exit condition";
CM_ SG_ 902 PSM_DrvStRlxTiltUpDis "PSM_DriverSeatRelexTiltUpDisplay";
CM_ SG_ 902 PSM_DrvStRlxTiltDnDis "PSM_DriverSeatRelexTiltDownDisplay";
CM_ SG_ 902 PSM_DrvStLegUpDis "PSM_DriverSeatLegUpDisplay";
CM_ SG_ 902 PSM_DrvStLegDnDis "PSM_DriverSeatLegDownDisplay";
CM_ SG_ 902 PSM_IMSOptTyp "Option flag for IMS system";
CM_ BO_ 903 "[PE] Periodic and On Event";
CM_ SG_ 903 PSM_DrvStSldFwdDis "PSM_DriverSlideForwardDisplay";
CM_ SG_ 903 PSM_DrvStTiltDnDis "PSM_DriverTiltDownSwitchDisplay";
CM_ SG_ 903 PSM_DrvStHghtUpDis "PSM_DriverHeightUpSwitchDisplay";
CM_ SG_ 903 PSM_DrvStHghtDnDis "PSM_DriverHeightDownSwitchDisplay";
CM_ SG_ 903 PSM_DrvStCushExtBckwdDis "PSM_DriverCushionExtendedBackwardSwitchDisplay";
CM_ SG_ 903 PSM_DrvStCushExtFwdDis "PSM_DriverCushionExtendedForwardSwitchDisplay";
CM_ SG_ 903 PSM_DrvStSldBckwdDis "PSM_DriverSlideBackwardSwitchDisplay";
CM_ SG_ 903 PSM_DrvStHdRstUpDis "PSM_DriverHeadRestUpSwitchDisplay";
CM_ SG_ 903 PSM_DrvStHdRstDnDis "PSM_DriverHeadRestDownSwitchDisplay";
CM_ SG_ 903 PSM_DrvStHdRstFwdDis "PSM_DriverHeadRestForwardSwitchDisplay";
CM_ SG_ 903 PSM_DrvStHdRstBckwdDis "PSM_DriverHeadRestBackwardSwitchDisplay";
CM_ SG_ 903 PSM_DrvStLmbrDefDis "PSM_DriverLumbarDeFlateSwitchDisplay";
CM_ SG_ 903 PSM_DrvStLmbrLoDis "PSM_DriverLumbarLowSwitchDisplay";
CM_ SG_ 903 PSM_DrvStLmbrMdlDis "PSM_DriverLumbarMiddleSwitchDisplay";
CM_ SG_ 903 PSM_DrvStLmbrUpDis "PSM_DriverLumbarUpSwitchDisplay";
CM_ SG_ 903 PSM_DrvStReclneFwdDis "PSM_DriverSeatReclineForwardSwitchDisplay";
CM_ SG_ 903 PSM_DrvStBlstrDefDis "PSM_DriverBolsterDeflateSwitchDisplay";
CM_ SG_ 903 PSM_DrvStBlstrInfDis "PSM_DriverBolsterInflateSwitchDisplay";
CM_ SG_ 903 PSM_DrvStReclneBckwdDis "PSM_DriverSeatReclineBackwardSwitchDisplay";
CM_ SG_ 903 PSM_DrvStTiltUpDis "PSM_DriverTiltUpSwitchDisplay";
CM_ BO_ 904 "[PE] Periodic and On Event";
CM_ SG_ 904 PSM_EsyAcsGetOffSta "Easy Access Get Off Information";
CM_ SG_ 904 PSM_EsyAcsStpSta "Easy Access Stop Information";
CM_ SG_ 904 PSM_SWVerMajor1 "First Word(ASCII) in PSM S/W Ver";
CM_ SG_ 904 PSM_SWVerMinor1 "Second Word(ASCII) in PSM S/W Ver";
CM_ SG_ 904 PSM_SWVerMinor2 "Third Word(ASCII) in PSM S/W Ver";
CM_ SG_ 904 PSM_EsyAcsGetOnSta "Easy Access Get On Information";
CM_ BO_ 934 "[PE] Periodic and On Event";
CM_ SG_ 934 PTGM_Crc1Val "PTGM_CyclicRedundancyCheck1Value";
CM_ SG_ 934 PTGM_AlvCnt1Val "PTGM_AliveCounter1Value";
CM_ SG_ 934 PTGM_HazardSta "PTGM_HazardStatus";
CM_ SG_ 934 PTGM_ModSta "PTGM_ModuleStatus";
CM_ SG_ 934 PTGM_MovSta "PTGM_MovingStatus";
CM_ SG_ 934 PTGM_OptTyp "PTGM_OptionType";
CM_ SG_ 934 PTGM_ReleaseRlySta "PTGM_ReleaseRelayStatus";
CM_ SG_ 934 PTGM_TrnkLkSwSta "PTGM_TrunkLockSwitchStatus";
CM_ SG_ 934 PTGM_UsmSetSta "PTGM_UsmSettingStatus";
CM_ SG_ 934 PTGM_FobSrch_Req "FOB Search Request";
CM_ SG_ 934 PTGM_TlgtAwayCloseRValue "PTGM_TailgateAwayCloseRValue";
CM_ SG_ 934 PTGM_TrnkTlgtOption "PTGM_TrnkTlgtOption";
CM_ SG_ 934 PTGM_LatchType "PTGM_LatchType";
CM_ BO_ 924 "[EC] On Event and On Change";
CM_ SG_ 924 RLPSU_FailState_PopUp "Rear LH Seat Operating Finish or Operating Disable Information for AVN Display";
CM_ SG_ 924 RLPSU_Folding_State_Popup_EC "Rear LH seat Folding State information";
CM_ SG_ 924 RLPSU_Relax_State_Popup_EC "Rear LH seat Relax State information";
CM_ SG_ 924 RLPSU_Reclining_State_Popup "(2nd Left Seat Power Seat) OSD Indicator Signal for Inoperable State";
CM_ BO_ 922 "[EC] On Event and On Change";
CM_ SG_ 922 RRPSU_FailState_PopUp "2nd RH Seat Operating Finish or Operating Disable Information for AVN Display";
CM_ SG_ 922 RRPSU_Folding_State_Popup_EC "Rear RH seat Folding State information";
CM_ SG_ 922 RRPSU_Relax_State_Popup_EC "Rear RH seat Relax State information";
CM_ SG_ 922 RRPSU_Reclining_State_Popup "(2nd Right Seat Power Seat) ODS Indicator Siganl for Inoperable State";
CM_ BO_ 905 "[PE] Periodic and On Event";
CM_ SG_ 905 SBCM_RR_Crc1Val "SBCM_RR_CyclicRedundancyCheck1Value";
CM_ SG_ 905 RR_CrashUnlockCmd "Rear Right Crash Unlock Command";
CM_ SG_ 905 SBCM_RR_AlvCnt1Val "SBCM_RR_AliveCounter1Value";
CM_ SG_ 905 Warn_RrRtDrSwSta_SBCM "Warn_RearRightDoorSwitchStatus ##2G## -  - C_RRDrSw,CF_Gway_RRDrSw,Warn_RrRtDrSwSta";
CM_ SG_ 905 DoorLock_RrRtDrUnLkSta_SBCM "DoorLock_RearRightDoorUnLockStatus ##2G## -  - C_RRUnlockState,DoorLock_RrRtDrUnLkSta";
CM_ SG_ 905 RR_SEAActivated "Rear Right SEA Activated";
CM_ SG_ 905 RR_SEAWarn "Rear Righr SEA Warning";
CM_ BO_ 929 "[PE] Periodic and On Event";
BA_DEF_ BO_ "DiagState" ENUM "No","Yes" ;
BA_DEF_ BO_ "DiagResponse" ENUM "No","Yes" ;
BA_DEF_ BO_ "DiagRequest" ENUM "No","Yes" ;
BA_DEF_ BO_ "TpMessage" ENUM "No","Yes" ;
BA_DEF_ BO_ "UsrMsgIDSforwardDeviation" INT 0 100 ;
BA_DEF_ BO_ "UsrMsgIDSbackwardDeviation" INT 50 1000 ;
BA_DEF_ BO_ "GenMsgCycleTime" INT 0 2000 ;
BA_DEF_ BO_ "GenMsgStartDelayTime" INT 0 2000 ;
BA_DEF_ BO_ "GenMsgSendType" ENUM "Cyclic","NoMsgSendType" ;
BA_DEF_ BO_ "GenMsgCycleTimeFast" INT 0 500 ;
BA_DEF_ BO_ "GenMsgDelayTime" INT 0 20 ;
BA_DEF_ BO_ "GenMsgILSupport" ENUM "No","Yes" ;
BA_DEF_ BO_ "GenMsgNrOfRepetition" INT 0 3 ;
BA_DEF_ BO_ "NmMessage" ENUM "No","Yes" ;
BA_DEF_ BO_ "NWM-Botschaft" ENUM "No","Yes" ;
BA_DEF_ BO_ "TpTxIndex" INT 0 255 ;
BA_DEF_ BO_ "VFrameFormat" ENUM "StandardCAN","ExtendedCAN","reserved","reserved","reserved","reserved","reserved","reserved","reserved","reserved","reserved","reserved","reserved","reserved","StandardCAN_FD","ExtendedCAN_FD" ;
BA_DEF_ SG_ "UserSigValidity" ENUM "B+","ACC","IG","IG1","IG2","IG3","IG1 or IG2","IG1 or IG3","Undef" ;
BA_DEF_ SG_ "TimeoutValue" STRING ;
BA_DEF_ SG_ "UsrSigPurpose" ENUM "Undef","FN","DIAG","DIAG(Req)","DIAG(Res)","DIAG(Phy)","DEV","CCP(Req)","CCP(Res)","NM","TP" ;
BA_DEF_ SG_ "GenSigStartValue" INT 0 1215752192 ;
BA_DEF_ SG_ "NetworkRequest" ENUM "Yes","No" ;
BA_DEF_ SG_ "NetworkRequestHoldingTime" INT 0 65535 ;
BA_DEF_ SG_ "Description" STRING ;
BA_DEF_ SG_ "Version" STRING ;
BA_DEF_ SG_ "GenSigEnvVarType" ENUM "Int","Float","Undef" ;
BA_DEF_ SG_ "GenSigSendType" ENUM "Cyclic","OnWrite","OnWriteWithRepetition","OnChange","OnChangeWithRepetition","IfActive","IfActiveWithRepetition","NoSigSendType","OnChangeAndIfActive","OnChangeAndIfActiveWithRepetition" ;
BA_DEF_ SG_ "GwSigLatencyTime" INT 0 65536 ;
BA_DEF_ SG_ "GwSigMissingSourceType" ENUM "Undef","OldValue","DefaultValue","InitialValue" ;
BA_DEF_ SG_ "NWM-WakeupAllowed" ENUM "<n.a.>" ;
BA_DEF_ SG_ "RoutingFactor" INT 1 1215752192 ;
BA_DEF_REL_ BU_SG_REL_ "GenSigTimeoutTime" INT 0 7000 ;
BA_DEF_DEF_ "DiagState" "No" ;
BA_DEF_DEF_ "DiagResponse" "No" ;
BA_DEF_DEF_ "DiagRequest" "No" ;
BA_DEF_DEF_ "TpMessage" "No" ;
BA_DEF_DEF_ "UsrMsgIDSforwardDeviation" 10 ;
BA_DEF_DEF_ "UsrMsgIDSbackwardDeviation" 100 ;
BA_DEF_DEF_ "GenMsgCycleTime" 200 ;
BA_DEF_DEF_ "GenMsgStartDelayTime" 0 ;
BA_DEF_DEF_ "GenMsgSendType" "NoMsgSendType" ;
BA_DEF_DEF_ "GenMsgCycleTimeFast" 40 ;
BA_DEF_DEF_ "GenMsgDelayTime" 20 ;
BA_DEF_DEF_ "GenMsgILSupport" "Yes" ;
BA_DEF_DEF_ "GenMsgNrOfRepetition" 3 ;
BA_DEF_DEF_ "NmMessage" "No" ;
BA_DEF_DEF_ "NWM-Botschaft" "No" ;
BA_DEF_DEF_ "TpTxIndex" 0 ;
BA_DEF_DEF_ "VFrameFormat" "StandardCAN" ;
BA_DEF_DEF_ "UserSigValidity" "IG" ;
BA_DEF_DEF_ "TimeoutValue" "" ;
BA_DEF_DEF_ "UsrSigPurpose" "FN" ;
BA_DEF_DEF_ "GenSigStartValue" 0 ;
BA_DEF_DEF_ "NetworkRequest" "No" ;
BA_DEF_DEF_ "NetworkRequestHoldingTime" 0 ;
BA_DEF_DEF_ "Description" "" ;
BA_DEF_DEF_ "Version" "" ;
BA_DEF_DEF_ "GenSigEnvVarType" "Undef" ;
BA_DEF_DEF_ "GenSigSendType" "NoSigSendType" ;
BA_DEF_DEF_ "GwSigLatencyTime" 40 ;
BA_DEF_DEF_ "GwSigMissingSourceType" "Undef" ;
BA_DEF_DEF_ "NWM-WakeupAllowed" "<n.a.>" ;
BA_DEF_DEF_ "RoutingFactor" 1 ;
BA_DEF_DEF_REL_ "GenSigTimeoutTime" 500 ;
BA_ "GenMsgSendType" BO_ 2239851009 0;
BA_ "GenMsgCycleTime" BO_ 2239851009 100;
BA_ "GenMsgCycleTimeFast" BO_ 2239851009 0;
BA_ "GenMsgNrOfRepetition" BO_ 2239851009 0;
BA_ "VFrameFormat" BO_ 2239851009 1;
BA_ "Description" SG_ 2239851009 ADAS_PRK_Crc3Val "The data area for CRC calculation is based on the data length (DLC) of the message DB.

The CRC shall be calculated over the entire data block (excluding the CRC bytes) including the user data, alive counter and Data ID

 

- CRC Polynomial (0x1021) , Initial Value : 0xFFFF, XOR value : 0x0000, Data ID : Message ID + 0xF800 

- The initial value is for CRC calculation and the message should be sent with the calculated result value. 

- The mathematical expression to 16 bit CRC polynomial is given here. G(x) = x16 + x12 + x5 + 1";
BA_ "GenSigStartValue" SG_ 2239851009 ADAS_PRK_Crc3Val 65535;
BA_ "UserSigValidity" SG_ 2239851009 ADAS_PRK_Crc3Val 3;
BA_ "RoutingFactor" SG_ 2239851009 ADAS_PRK_Crc3Val 5;
BA_ "Version" SG_ 2239851009 ADAS_PRK_Crc3Val "18.11.08";
BA_ "Description" SG_ 2239851009 ADAS_PRK_AlvCnt3Val "For the first transmission request for a data element the counter shall be initialized with 0 and shall be incremented by 1 for every subsequent send request. 

When the counter reaches the maximum value(0xFF), then it shall restart with 0 for the next send request";
BA_ "UserSigValidity" SG_ 2239851009 ADAS_PRK_AlvCnt3Val 3;
BA_ "RoutingFactor" SG_ 2239851009 ADAS_PRK_AlvCnt3Val 5;
BA_ "Version" SG_ 2239851009 ADAS_PRK_AlvCnt3Val "18.11.08";
BA_ "Description" SG_ 2239851009 RSPA_AvnDis "AVN È­¸é Ãâ·Â ¿äÃ» (RSPA ¿ë)

'-CGW routing ÇÊ¿ä (CCAN to MMCAN)";
BA_ "UserSigValidity" SG_ 2239851009 RSPA_AvnDis 3;
BA_ "RoutingFactor" SG_ 2239851009 RSPA_AvnDis 5;
BA_ "Version" SG_ 2239851009 RSPA_AvnDis "17.11.00";
BA_ "Description" SG_ 2239851009 RSPA_AvnModDis "AVN»óÀÇ ¸ðµå¼±ÅÃ ¸Þ´º Ç¥ÃâÀ» À§ÇÑ ÁÖÂ÷/ÃâÂ÷ ±¸ºÐ Á¤º¸

'-CGW routing ÇÊ¿ä (CCAN to MMCAN)";
BA_ "UserSigValidity" SG_ 2239851009 RSPA_AvnModDis 3;
BA_ "RoutingFactor" SG_ 2239851009 RSPA_AvnModDis 5;
BA_ "Version" SG_ 2239851009 RSPA_AvnModDis "17.11.00";
BA_ "Description" SG_ 2239851009 RSPA_AvnModNumDis "AVN¿¡¼­ Ç¥ÃâÇØ¾ßÇÒ ¸ðµå ¼±ÅÃ ¸Þ´ºÀÇ °³¼ö ¼³Á¤ Á¤º¸

'-CGW routing ÇÊ¿ä (CCAN to MMCAN)";
BA_ "UserSigValidity" SG_ 2239851009 RSPA_AvnModNumDis 3;
BA_ "RoutingFactor" SG_ 2239851009 RSPA_AvnModNumDis 5;
BA_ "Version" SG_ 2239851009 RSPA_AvnModNumDis "17.11.00";
BA_ "Description" SG_ 2239851009 RSPA_AvnSubViewDis "AVN¿¡¼­ Ç¥ÃâÇØ¾ßÇÒ Topview¿µ¿ª ´ëÃ¼ÀÌ¹ÌÁö Ãâ·Â¿äÃ»

'-CGW routing ÇÊ¿ä (CCAN to MMCAN)";
BA_ "UserSigValidity" SG_ 2239851009 RSPA_AvnSubViewDis 3;
BA_ "RoutingFactor" SG_ 2239851009 RSPA_AvnSubViewDis 5;
BA_ "Version" SG_ 2239851009 RSPA_AvnSubViewDis "17.11.00";
BA_ "Description" SG_ 2239851009 RSPA_AvnModPLDis "AVN¿¡¼­ Ç¥ÃâÇÏ´Â ÆòÇàÈÄ¹æÁÂÃø (ÁÖÂ÷/ÃâÂ÷) ¸ðµå¼±ÅÃ ¸Þ´ºÀÇ Á¦¾î°¡´É¿©ºÎ Ç¥½Ã Á¤º¸

'-CGW routing ÇÊ¿ä (CCAN to MMCAN)";
BA_ "UserSigValidity" SG_ 2239851009 RSPA_AvnModPLDis 3;
BA_ "RoutingFactor" SG_ 2239851009 RSPA_AvnModPLDis 5;
BA_ "Version" SG_ 2239851009 RSPA_AvnModPLDis "17.11.00";
BA_ "Description" SG_ 2239851009 RSPA_AvnModPDRLDis "AVN¿¡¼­ Ç¥ÃâÇÏ´Â Á÷°¢ÈÄ¹æÁÂÃø (ÁÖÂ÷/ÃâÂ÷) ¸ðµå¼±ÅÃ ¸Þ´ºÀÇ Á¦¾î°¡´É¿©ºÎ Ç¥½Ã Á¤º¸

'-CGW routing ÇÊ¿ä (CCAN to MMCAN)";
BA_ "UserSigValidity" SG_ 2239851009 RSPA_AvnModPDRLDis 3;
BA_ "RoutingFactor" SG_ 2239851009 RSPA_AvnModPDRLDis 5;
BA_ "Version" SG_ 2239851009 RSPA_AvnModPDRLDis "17.11.00";
BA_ "Description" SG_ 2239851009 RSPA_AvnModPDRRDis "AVN¿¡¼­ Ç¥ÃâÇÏ´Â Á÷°¢ÈÄ¹æ¿ìÃø (ÁÖÂ÷/ÃâÂ÷) ¸ðµå¼±ÅÃ ¸Þ´ºÀÇ Á¦¾î°¡´É¿©ºÎ Ç¥½Ã Á¤º¸

'-CGW routing ÇÊ¿ä (CCAN to MMCAN)";
BA_ "UserSigValidity" SG_ 2239851009 RSPA_AvnModPDRRDis 3;
BA_ "RoutingFactor" SG_ 2239851009 RSPA_AvnModPDRRDis 5;
BA_ "Version" SG_ 2239851009 RSPA_AvnModPDRRDis "17.11.00";
BA_ "Description" SG_ 2239851009 RSPA_AvnModPRDis "AVN¿¡¼­ Ç¥ÃâÇÏ´Â ÆòÇàÈÄ¹æ¿ìÃø (ÁÖÂ÷/ÃâÂ÷) ¸ðµå¼±ÅÃ ¸Þ´ºÀÇ Á¦¾î°¡´É¿©ºÎ Ç¥½Ã Á¤º¸

'-CGW routing ÇÊ¿ä (CCAN to MMCAN)";
BA_ "UserSigValidity" SG_ 2239851009 RSPA_AvnModPRDis 3;
BA_ "RoutingFactor" SG_ 2239851009 RSPA_AvnModPRDis 5;
BA_ "Version" SG_ 2239851009 RSPA_AvnModPRDis "17.11.00";
BA_ "Description" SG_ 2239851009 RSPA_CamDis "RSPA ÀÛµ¿ ½Ã AVM/RVM¿¡ AVN¿¡ Ãâ·ÂÇÒ ¿µ»ó ºä ¸ðµå ¿äÃ»";
BA_ "UserSigValidity" SG_ 2239851009 RSPA_CamDis 3;
BA_ "RoutingFactor" SG_ 2239851009 RSPA_CamDis 5;
BA_ "Version" SG_ 2239851009 RSPA_CamDis "17.11.00";
BA_ "Description" SG_ 2239851009 RSPA_AvnHmiDis "AVN¿¡¼­ Ç¥ÃâÇÏ´Â RSPA HMI Ç¥½Ã Á¤º¸

'-CGW routing ÇÊ¿ä (CCAN to MMCAN)";
BA_ "UserSigValidity" SG_ 2239851009 RSPA_AvnHmiDis 3;
BA_ "RoutingFactor" SG_ 2239851009 RSPA_AvnHmiDis 5;
BA_ "Version" SG_ 2239851009 RSPA_AvnHmiDis "19.11.11";
BA_ "GenMsgSendType" BO_ 2239851010 0;
BA_ "GenMsgCycleTime" BO_ 2239851010 100;
BA_ "GenMsgCycleTimeFast" BO_ 2239851010 0;
BA_ "GenMsgNrOfRepetition" BO_ 2239851010 0;
BA_ "VFrameFormat" BO_ 2239851010 1;
BA_ "Description" SG_ 2239851010 RSPA_RtTrgtPosX "AVM Ç¥½Ã ¿À¸¥ÂÊ ÁÖÂ÷°ø°£ À§Ä¡ X ÁÂÇ¥";
BA_ "UserSigValidity" SG_ 2239851010 RSPA_RtTrgtPosX 3;
BA_ "RoutingFactor" SG_ 2239851010 RSPA_RtTrgtPosX 5;
BA_ "Version" SG_ 2239851010 RSPA_RtTrgtPosX "20.08.02";
BA_ "Description" SG_ 2239851010 RSPA_RtTrgtPosY "AVM Ç¥½Ã ¿À¸¥ÂÊ ÁÖÂ÷°ø°£ À§Ä¡ Y ÁÂÇ¥";
BA_ "UserSigValidity" SG_ 2239851010 RSPA_RtTrgtPosY 3;
BA_ "RoutingFactor" SG_ 2239851010 RSPA_RtTrgtPosY 5;
BA_ "Version" SG_ 2239851010 RSPA_RtTrgtPosY "20.08.02";
BA_ "Description" SG_ 2239851010 RSPA_LtTrgtPosX "AVM Ç¥½Ã ¿ÞÂÊ ÁÖÂ÷°ø°£ À§Ä¡ X ÁÂÇ¥";
BA_ "UserSigValidity" SG_ 2239851010 RSPA_LtTrgtPosX 3;
BA_ "RoutingFactor" SG_ 2239851010 RSPA_LtTrgtPosX 5;
BA_ "Version" SG_ 2239851010 RSPA_LtTrgtPosX "20.08.02";
BA_ "Description" SG_ 2239851010 RSPA_LtTrgtPosY "AVM Ç¥½Ã ¿ÞÂÊ ÁÖÂ÷°ø°£ À§Ä¡ Y ÁÂÇ¥";
BA_ "UserSigValidity" SG_ 2239851010 RSPA_LtTrgtPosY 3;
BA_ "RoutingFactor" SG_ 2239851010 RSPA_LtTrgtPosY 5;
BA_ "Version" SG_ 2239851010 RSPA_LtTrgtPosY "20.08.02";
BA_ "Description" SG_ 2239851010 RSPA_Var "RSPA variation";
BA_ "UserSigValidity" SG_ 2239851010 RSPA_Var 3;
BA_ "RoutingFactor" SG_ 2239851010 RSPA_Var 5;
BA_ "Version" SG_ 2239851010 RSPA_Var "19.08.08";
BA_ "Description" SG_ 2239851010 RSPA_Sta "ÇöÀç RSPAÀÇ »óÅÂ";
BA_ "GenSigStartValue" SG_ 2239851010 RSPA_Sta 1;
BA_ "UserSigValidity" SG_ 2239851010 RSPA_Sta 3;
BA_ "RoutingFactor" SG_ 2239851010 RSPA_Sta 5;
BA_ "Version" SG_ 2239851010 RSPA_Sta "19.03.11";
BA_ "Description" SG_ 2239851010 RSPA_Actv "RSPA's activation information";
BA_ "UserSigValidity" SG_ 2239851010 RSPA_Actv 3;
BA_ "RoutingFactor" SG_ 2239851010 RSPA_Actv 5;
BA_ "Version" SG_ 2239851010 RSPA_Actv "17.11.00";
BA_ "Description" SG_ 2239851010 RSPA_EvasiveStrBtnDis "Display evasive steering on/off button (RSPA II)";
BA_ "UserSigValidity" SG_ 2239851010 RSPA_EvasiveStrBtnDis 3;
BA_ "RoutingFactor" SG_ 2239851010 RSPA_EvasiveStrBtnDis 5;
BA_ "Version" SG_ 2239851010 RSPA_EvasiveStrBtnDis "19.08.08";
BA_ "GenMsgSendType" BO_ 2239851011 0;
BA_ "GenMsgCycleTime" BO_ 2239851011 100;
BA_ "GenMsgCycleTimeFast" BO_ 2239851011 0;
BA_ "GenMsgNrOfRepetition" BO_ 2239851011 0;
BA_ "VFrameFormat" BO_ 2239851011 1;
BA_ "Description" SG_ 2239851011 RSPA_TrgtGearSta "¸ñÇ¥ º¯¼Ó´Ü 

(¸ñÇ¥ º¯¼Ó´Ü 100ms À¯ÁöÈÄ Idle °ª ¼ÛÃâ, ¸ñÇ¥°ª rising ÀÌÈÄ 500ms ´ë±â)";
BA_ "UserSigValidity" SG_ 2239851011 RSPA_TrgtGearSta 3;
BA_ "RoutingFactor" SG_ 2239851011 RSPA_TrgtGearSta 5;
BA_ "Version" SG_ 2239851011 RSPA_TrgtGearSta "17.11.00";
BA_ "Description" SG_ 2239851011 RSPA_IdOutWarnReq "ID out ÆÐÅÏ º¯°æ ¿äÃ» (RSPA ¿ë)";
BA_ "UserSigValidity" SG_ 2239851011 RSPA_IdOutWarnReq 3;
BA_REL_ "GenSigTimeoutTime" BU_SG_REL_ DPSU SG_ 2239851011 RSPA_IdOutWarnReq 1500;
BA_ "RoutingFactor" SG_ 2239851011 RSPA_IdOutWarnReq 5;
BA_ "Version" SG_ 2239851011 RSPA_IdOutWarnReq "17.11.00";
BA_ "Description" SG_ 2239851011 RSPA_IndBlnkReq "FOB blinking request during RSPA mode";
BA_ "UserSigValidity" SG_ 2239851011 RSPA_IndBlnkReq 3;
BA_ "RoutingFactor" SG_ 2239851011 RSPA_IndBlnkReq 5;
BA_ "Version" SG_ 2239851011 RSPA_IndBlnkReq "17.11.00";
BA_ "Description" SG_ 2239851011 RSPA_SysOff "System off status for Smartphone display before RSPA control";
BA_ "UserSigValidity" SG_ 2239851011 RSPA_SysOff 3;
BA_ "RoutingFactor" SG_ 2239851011 RSPA_SysOff 5;
BA_ "Version" SG_ 2239851011 RSPA_SysOff "18.12.07";
BA_ "Description" SG_ 2239851011 RSPA_DccCmd "¸ñÇ¥ °¨¼Óµµ, Â÷·® Á¤Â÷ ½Ã¿¡¸¸(when RSPA_VS=0) °¨¼Óµµ Á¦¾î¸ñÀû";
BA_ "UserSigValidity" SG_ 2239851011 RSPA_DccCmd 3;
BA_ "RoutingFactor" SG_ 2239851011 RSPA_DccCmd 5;
BA_ "Version" SG_ 2239851011 RSPA_DccCmd "17.11.00";
BA_ "Description" SG_ 2239851011 RSPA_StopReq "A control request flag for vehicle stop. RSPA expects vehicle to be controlled to a complete stop and hold its state.";
BA_ "UserSigValidity" SG_ 2239851011 RSPA_StopReq 3;
BA_ "RoutingFactor" SG_ 2239851011 RSPA_StopReq 5;
BA_ "Version" SG_ 2239851011 RSPA_StopReq "17.11.00";
BA_ "Description" SG_ 2239851011 RSPA_SelDevInfo "Device information for Remote Control in operation of RSPA";
BA_ "UserSigValidity" SG_ 2239851011 RSPA_SelDevInfo 3;
BA_ "RoutingFactor" SG_ 2239851011 RSPA_SelDevInfo 5;
BA_ "Version" SG_ 2239851011 RSPA_SelDevInfo "18.12.07";
BA_ "Description" SG_ 2239851011 RSPA_SelFuncInfo "Function information in operation of RSPA for SmartPhone control";
BA_ "UserSigValidity" SG_ 2239851011 RSPA_SelFuncInfo 3;
BA_ "RoutingFactor" SG_ 2239851011 RSPA_SelFuncInfo 5;
BA_ "Version" SG_ 2239851011 RSPA_SelFuncInfo "18.12.07";
BA_ "Description" SG_ 2239851011 RSPA_TrgtVehSpdVal "Â÷¼Ó ¿äÃ»°ª, Â÷¼Ó ÇÁ·ÎÆÄÀÏ Àü¼Û (0 ¡¦ 10.23)";
BA_ "UserSigValidity" SG_ 2239851011 RSPA_TrgtVehSpdVal 3;
BA_ "RoutingFactor" SG_ 2239851011 RSPA_TrgtVehSpdVal 5;
BA_ "Version" SG_ 2239851011 RSPA_TrgtVehSpdVal "18.07.01";
BA_ "Description" SG_ 2239851011 RSPA_EpbReq "EPB Ã¼°á/ÇØÁ¦ ¿äÃ» (AHB ¿ìÈ¸)";
BA_ "UserSigValidity" SG_ 2239851011 RSPA_EpbReq 3;
BA_ "RoutingFactor" SG_ 2239851011 RSPA_EpbReq 5;
BA_ "Version" SG_ 2239851011 RSPA_EpbReq "19.03.11";
BA_ "Description" SG_ 2239851011 RSPA_AddtnlAccelActv "RSPA additional acceleration control ON";
BA_ "UserSigValidity" SG_ 2239851011 RSPA_AddtnlAccelActv 3;
BA_ "RoutingFactor" SG_ 2239851011 RSPA_AddtnlAccelActv 5;
BA_ "Version" SG_ 2239851011 RSPA_AddtnlAccelActv "17.11.00";
BA_ "Description" SG_ 2239851011 RSPA_Opt "RSPA Option applied information";
BA_ "UserSigValidity" SG_ 2239851011 RSPA_Opt 3;
BA_ "RoutingFactor" SG_ 2239851011 RSPA_Opt 5;
BA_ "Version" SG_ 2239851011 RSPA_Opt "17.12.03";
BA_ "Description" SG_ 2239851011 RSPA_RmtPrlExitDis "Display remote parallel exit (RSPA II)";
BA_ "UserSigValidity" SG_ 2239851011 RSPA_RmtPrlExitDis 3;
BA_ "RoutingFactor" SG_ 2239851011 RSPA_RmtPrlExitDis 5;
BA_ "Version" SG_ 2239851011 RSPA_RmtPrlExitDis "19.08.08";
BA_ "Description" SG_ 2239851011 RSPA_TrgtTqVal "RSPA request EMS/HCU/VCU/FCU torque value (Nm)

Init value : 00h

If MSB is 1, this signal is - value.

else, this signal is +value.

0~10bit is used for absolute value.";
BA_ "UserSigValidity" SG_ 2239851011 RSPA_TrgtTqVal 3;
BA_ "RoutingFactor" SG_ 2239851011 RSPA_TrgtTqVal 5;
BA_ "Version" SG_ 2239851011 RSPA_TrgtTqVal "19.06.00";
BA_ "Description" SG_ 2239851011 RSPA_ExtLampReq "ÀüÁ¶µî, ¹æÇâÁö½Ãµî µ¿ÀÛ ¿äÃ» (RSPA ¿ë)

Type1:ºñ»óµî 1È¸ Normal Blinking

Type2:ºñ»óµî 2È¸ Normal Blinking

Type3:ºñ»óµî 3È¸ Normal Blinking

Type4:ºñ»óµî Áö¼ÓÀûÀ¸·Î Normal Blinking";
BA_ "UserSigValidity" SG_ 2239851011 RSPA_ExtLampReq 3;
BA_ "RoutingFactor" SG_ 2239851011 RSPA_ExtLampReq 5;
BA_ "Version" SG_ 2239851011 RSPA_ExtLampReq "17.11.00";
BA_ "Description" SG_ 2239851011 RSPA_UppLtTypDis "Parking type displayed on upper-left of AVN (RSPA II)";
BA_ "UserSigValidity" SG_ 2239851011 RSPA_UppLtTypDis 3;
BA_ "RoutingFactor" SG_ 2239851011 RSPA_UppLtTypDis 5;
BA_ "Version" SG_ 2239851011 RSPA_UppLtTypDis "20.03.04";
BA_ "Description" SG_ 2239851011 RSPA_LwrLtTypDis "Parking type displayed on lower-left of AVN (RSPA II)";
BA_ "UserSigValidity" SG_ 2239851011 RSPA_LwrLtTypDis 3;
BA_ "RoutingFactor" SG_ 2239851011 RSPA_LwrLtTypDis 5;
BA_ "Version" SG_ 2239851011 RSPA_LwrLtTypDis "20.03.04";
BA_ "Description" SG_ 2239851011 RSPA_UppRtTypDis "Parking type displayed on upper-right of AVN (RSPA II)";
BA_ "UserSigValidity" SG_ 2239851011 RSPA_UppRtTypDis 3;
BA_ "RoutingFactor" SG_ 2239851011 RSPA_UppRtTypDis 5;
BA_ "Version" SG_ 2239851011 RSPA_UppRtTypDis "19.08.08";
BA_ "Description" SG_ 2239851011 RSPA_LwrRtTypDis "Parking type displayed on lower-right of AVN (RSPA II)";
BA_ "UserSigValidity" SG_ 2239851011 RSPA_LwrRtTypDis 3;
BA_ "RoutingFactor" SG_ 2239851011 RSPA_LwrRtTypDis 5;
BA_ "Version" SG_ 2239851011 RSPA_LwrRtTypDis "19.08.08";
BA_ "Description" SG_ 2239851011 RSPA_CrankingReq "½Ãµ¿¸ðµå ÃµÀÌ ¿äÃ» (RSPA ¿ë)";
BA_ "UserSigValidity" SG_ 2239851011 RSPA_CrankingReq 3;
BA_ "RoutingFactor" SG_ 2239851011 RSPA_CrankingReq 5;
BA_ "Version" SG_ 2239851011 RSPA_CrankingReq "17.11.00";
BA_ "GenMsgCycleTime" BO_ 1517 0;
BA_ "GenMsgCycleTimeFast" BO_ 1517 0;
BA_ "GenMsgNrOfRepetition" BO_ 1517 0;
BA_ "DiagResponse" BO_ 1517 1;
BA_ "GenMsgILSupport" BO_ 1517 0;
BA_ "TpMessage" BO_ 1517 1;
BA_ "TpTxIndex" BO_ 1517 107;
BA_ "Description" SG_ 1517 ALBCU_GST_Byte0 "TP Index : 107";
BA_ "UsrSigPurpose" SG_ 1517 ALBCU_GST_Byte0 4;
BA_ "UserSigValidity" SG_ 1517 ALBCU_GST_Byte0 0;
BA_REL_ "GenSigTimeoutTime" BU_SG_REL_ CGW_CCU SG_ 1517 ALBCU_GST_Byte0 0;
BA_ "NetworkRequest" SG_ 1517 ALBCU_GST_Byte0 0;
BA_ "NetworkRequestHoldingTime" SG_ 1517 ALBCU_GST_Byte0 5000;
BA_ "Version" SG_ 1517 ALBCU_GST_Byte0 "21.11.06";
BA_ "Description" SG_ 1517 ALBCU_GST_Byte2 "TP Index : 107";
BA_ "UsrSigPurpose" SG_ 1517 ALBCU_GST_Byte2 4;
BA_ "UserSigValidity" SG_ 1517 ALBCU_GST_Byte2 0;
BA_REL_ "GenSigTimeoutTime" BU_SG_REL_ CGW_CCU SG_ 1517 ALBCU_GST_Byte2 0;
BA_ "NetworkRequest" SG_ 1517 ALBCU_GST_Byte2 0;
BA_ "NetworkRequestHoldingTime" SG_ 1517 ALBCU_GST_Byte2 5000;
BA_ "Version" SG_ 1517 ALBCU_GST_Byte2 "21.11.06";
BA_ "Description" SG_ 1517 ALBCU_GST_Byte3 "TP Index : 107";
BA_ "UsrSigPurpose" SG_ 1517 ALBCU_GST_Byte3 4;
BA_ "UserSigValidity" SG_ 1517 ALBCU_GST_Byte3 0;
BA_REL_ "GenSigTimeoutTime" BU_SG_REL_ CGW_CCU SG_ 1517 ALBCU_GST_Byte3 0;
BA_ "NetworkRequest" SG_ 1517 ALBCU_GST_Byte3 0;
BA_ "NetworkRequestHoldingTime" SG_ 1517 ALBCU_GST_Byte3 5000;
BA_ "Version" SG_ 1517 ALBCU_GST_Byte3 "21.11.06";
BA_ "Description" SG_ 1517 ALBCU_GST_Byte4 "TP Index : 107";
BA_ "UsrSigPurpose" SG_ 1517 ALBCU_GST_Byte4 4;
BA_ "UserSigValidity" SG_ 1517 ALBCU_GST_Byte4 0;
BA_REL_ "GenSigTimeoutTime" BU_SG_REL_ CGW_CCU SG_ 1517 ALBCU_GST_Byte4 0;
BA_ "NetworkRequest" SG_ 1517 ALBCU_GST_Byte4 0;
BA_ "NetworkRequestHoldingTime" SG_ 1517 ALBCU_GST_Byte4 5000;
BA_ "Version" SG_ 1517 ALBCU_GST_Byte4 "21.11.06";
BA_ "Description" SG_ 1517 ALBCU_GST_Byte5 "TP Index : 107";
BA_ "UsrSigPurpose" SG_ 1517 ALBCU_GST_Byte5 4;
BA_ "UserSigValidity" SG_ 1517 ALBCU_GST_Byte5 0;
BA_REL_ "GenSigTimeoutTime" BU_SG_REL_ CGW_CCU SG_ 1517 ALBCU_GST_Byte5 0;
BA_ "NetworkRequest" SG_ 1517 ALBCU_GST_Byte5 0;
BA_ "NetworkRequestHoldingTime" SG_ 1517 ALBCU_GST_Byte5 5000;
BA_ "Version" SG_ 1517 ALBCU_GST_Byte5 "21.11.06";
BA_ "Description" SG_ 1517 ALBCU_GST_Byte6 "TP Index : 107";
BA_ "UsrSigPurpose" SG_ 1517 ALBCU_GST_Byte6 4;
BA_ "UserSigValidity" SG_ 1517 ALBCU_GST_Byte6 0;
BA_REL_ "GenSigTimeoutTime" BU_SG_REL_ CGW_CCU SG_ 1517 ALBCU_GST_Byte6 0;
BA_ "NetworkRequest" SG_ 1517 ALBCU_GST_Byte6 0;
BA_ "NetworkRequestHoldingTime" SG_ 1517 ALBCU_GST_Byte6 5000;
BA_ "Version" SG_ 1517 ALBCU_GST_Byte6 "21.11.06";
BA_ "Description" SG_ 1517 ALBCU_GST_Byte7 "TP Index : 107";
BA_ "UsrSigPurpose" SG_ 1517 ALBCU_GST_Byte7 4;
BA_ "UserSigValidity" SG_ 1517 ALBCU_GST_Byte7 0;
BA_REL_ "GenSigTimeoutTime" BU_SG_REL_ CGW_CCU SG_ 1517 ALBCU_GST_Byte7 0;
BA_ "NetworkRequest" SG_ 1517 ALBCU_GST_Byte7 0;
BA_ "NetworkRequestHoldingTime" SG_ 1517 ALBCU_GST_Byte7 5000;
BA_ "Version" SG_ 1517 ALBCU_GST_Byte7 "21.11.06";
BA_ "Description" SG_ 1517 ALBCU_GST_Byte1 "TP Index : 107";
BA_ "UsrSigPurpose" SG_ 1517 ALBCU_GST_Byte1 4;
BA_ "UserSigValidity" SG_ 1517 ALBCU_GST_Byte1 0;
BA_REL_ "GenSigTimeoutTime" BU_SG_REL_ CGW_CCU SG_ 1517 ALBCU_GST_Byte1 0;
BA_ "NetworkRequest" SG_ 1517 ALBCU_GST_Byte1 0;
BA_ "NetworkRequestHoldingTime" SG_ 1517 ALBCU_GST_Byte1 5000;
BA_ "Version" SG_ 1517 ALBCU_GST_Byte1 "21.11.06";
BA_ "GenMsgCycleTime" BO_ 1484 0;
BA_ "GenMsgCycleTimeFast" BO_ 1484 0;
BA_ "GenMsgNrOfRepetition" BO_ 1484 0;
BA_ "DiagResponse" BO_ 1484 1;
BA_ "GenMsgILSupport" BO_ 1484 0;
BA_ "TpMessage" BO_ 1484 1;
BA_ "TpTxIndex" BO_ 1484 216;
BA_ "Description" SG_ 1484 ASAU_GST_Byte0 "TP Index : 216";
BA_ "UsrSigPurpose" SG_ 1484 ASAU_GST_Byte0 4;
BA_ "UserSigValidity" SG_ 1484 ASAU_GST_Byte0 0;
BA_REL_ "GenSigTimeoutTime" BU_SG_REL_ CGW_CCU SG_ 1484 ASAU_GST_Byte0 0;
BA_ "NetworkRequest" SG_ 1484 ASAU_GST_Byte0 0;
BA_ "NetworkRequestHoldingTime" SG_ 1484 ASAU_GST_Byte0 5000;
BA_ "Version" SG_ 1484 ASAU_GST_Byte0 "21.02.04";
BA_ "Description" SG_ 1484 ASAU_GST_Byte2 "TP Index : 216";
BA_ "UsrSigPurpose" SG_ 1484 ASAU_GST_Byte2 4;
BA_ "UserSigValidity" SG_ 1484 ASAU_GST_Byte2 0;
BA_REL_ "GenSigTimeoutTime" BU_SG_REL_ CGW_CCU SG_ 1484 ASAU_GST_Byte2 0;
BA_ "NetworkRequest" SG_ 1484 ASAU_GST_Byte2 0;
BA_ "NetworkRequestHoldingTime" SG_ 1484 ASAU_GST_Byte2 5000;
BA_ "Version" SG_ 1484 ASAU_GST_Byte2 "21.02.04";
BA_ "Description" SG_ 1484 ASAU_GST_Byte3 "TP Index : 216";
BA_ "UsrSigPurpose" SG_ 1484 ASAU_GST_Byte3 4;
BA_ "UserSigValidity" SG_ 1484 ASAU_GST_Byte3 0;
BA_REL_ "GenSigTimeoutTime" BU_SG_REL_ CGW_CCU SG_ 1484 ASAU_GST_Byte3 0;
BA_ "NetworkRequest" SG_ 1484 ASAU_GST_Byte3 0;
BA_ "NetworkRequestHoldingTime" SG_ 1484 ASAU_GST_Byte3 5000;
BA_ "Version" SG_ 1484 ASAU_GST_Byte3 "21.02.04";
BA_ "Description" SG_ 1484 ASAU_GST_Byte4 "TP Index : 216";
BA_ "UsrSigPurpose" SG_ 1484 ASAU_GST_Byte4 4;
BA_ "UserSigValidity" SG_ 1484 ASAU_GST_Byte4 0;
BA_REL_ "GenSigTimeoutTime" BU_SG_REL_ CGW_CCU SG_ 1484 ASAU_GST_Byte4 0;
BA_ "NetworkRequest" SG_ 1484 ASAU_GST_Byte4 0;
BA_ "NetworkRequestHoldingTime" SG_ 1484 ASAU_GST_Byte4 5000;
BA_ "Version" SG_ 1484 ASAU_GST_Byte4 "21.02.04";
BA_ "Description" SG_ 1484 ASAU_GST_Byte5 "TP Index : 216";
BA_ "UsrSigPurpose" SG_ 1484 ASAU_GST_Byte5 4;
BA_ "UserSigValidity" SG_ 1484 ASAU_GST_Byte5 0;
BA_REL_ "GenSigTimeoutTime" BU_SG_REL_ CGW_CCU SG_ 1484 ASAU_GST_Byte5 0;
BA_ "NetworkRequest" SG_ 1484 ASAU_GST_Byte5 0;
BA_ "NetworkRequestHoldingTime" SG_ 1484 ASAU_GST_Byte5 5000;
BA_ "Version" SG_ 1484 ASAU_GST_Byte5 "21.02.04";
BA_ "Description" SG_ 1484 ASAU_GST_Byte6 "TP Index : 216";
BA_ "UsrSigPurpose" SG_ 1484 ASAU_GST_Byte6 4;
BA_ "UserSigValidity" SG_ 1484 ASAU_GST_Byte6 0;
BA_REL_ "GenSigTimeoutTime" BU_SG_REL_ CGW_CCU SG_ 1484 ASAU_GST_Byte6 0;
BA_ "NetworkRequest" SG_ 1484 ASAU_GST_Byte6 0;
BA_ "NetworkRequestHoldingTime" SG_ 1484 ASAU_GST_Byte6 5000;
BA_ "Version" SG_ 1484 ASAU_GST_Byte6 "21.02.04";
BA_ "Description" SG_ 1484 ASAU_GST_Byte7 "TP Index : 216";
BA_ "UsrSigPurpose" SG_ 1484 ASAU_GST_Byte7 4;
BA_ "UserSigValidity" SG_ 1484 ASAU_GST_Byte7 0;
BA_REL_ "GenSigTimeoutTime" BU_SG_REL_ CGW_CCU SG_ 1484 ASAU_GST_Byte7 0;
BA_ "NetworkRequest" SG_ 1484 ASAU_GST_Byte7 0;
BA_ "NetworkRequestHoldingTime" SG_ 1484 ASAU_GST_Byte7 5000;
BA_ "Version" SG_ 1484 ASAU_GST_Byte7 "21.02.04";
BA_ "Description" SG_ 1484 ASAU_GST_Byte1 "TP Index : 216";
BA_ "UsrSigPurpose" SG_ 1484 ASAU_GST_Byte1 4;
BA_ "UserSigValidity" SG_ 1484 ASAU_GST_Byte1 0;
BA_REL_ "GenSigTimeoutTime" BU_SG_REL_ CGW_CCU SG_ 1484 ASAU_GST_Byte1 0;
BA_ "NetworkRequest" SG_ 1484 ASAU_GST_Byte1 0;
BA_ "NetworkRequestHoldingTime" SG_ 1484 ASAU_GST_Byte1 5000;
BA_ "Version" SG_ 1484 ASAU_GST_Byte1 "21.02.04";
BA_ "GenMsgCycleTime" BO_ 911 0;
BA_ "Description" SG_ 911 ATS_RearLock_Set "RRC and RSE Lock Touch Button";
BA_ "GenSigSendType" SG_ 911 ATS_RearLock_Set 4;
BA_ "GenSigStartValue" SG_ 911 ATS_RearLock_Set 3;
BA_ "UserSigValidity" SG_ 911 ATS_RearLock_Set 3;
BA_REL_ "GenSigTimeoutTime" BU_SG_REL_ CGW_CCU SG_ 911 ATS_RearLock_Set 0;
BA_ "NetworkRequest" SG_ 911 ATS_RearLock_Set 0;
BA_ "NetworkRequestHoldingTime" SG_ 911 ATS_RearLock_Set 5000;
BA_ "Version" SG_ 911 ATS_RearLock_Set "20.07.08";
BA_ "Description" SG_ 911 ATS_RrCurtainBtn "Rear Curtain Touch Button";
BA_ "GenSigSendType" SG_ 911 ATS_RrCurtainBtn 4;
BA_ "UserSigValidity" SG_ 911 ATS_RrCurtainBtn 3;
BA_REL_ "GenSigTimeoutTime" BU_SG_REL_ CGW_CCU SG_ 911 ATS_RrCurtainBtn 0;
BA_ "NetworkRequest" SG_ 911 ATS_RrCurtainBtn 0;
BA_ "NetworkRequestHoldingTime" SG_ 911 ATS_RrCurtainBtn 5000;
BA_ "Version" SG_ 911 ATS_RrCurtainBtn "20.07.05";
BA_ "Description" SG_ 911 ATS_RrDrCurtainBtn "Rear Door and Curtain Touch Button";
BA_ "GenSigSendType" SG_ 911 ATS_RrDrCurtainBtn 4;
BA_ "UserSigValidity" SG_ 911 ATS_RrDrCurtainBtn 3;
BA_ "NetworkRequest" SG_ 911 ATS_RrDrCurtainBtn 0;
BA_ "NetworkRequestHoldingTime" SG_ 911 ATS_RrDrCurtainBtn 5000;
BA_ "Version" SG_ 911 ATS_RrDrCurtainBtn "20.07.05";
BA_ "Description" SG_ 911 ATS_RLDrCurtainBtn "Rear Door and Curtain Touch Button";
BA_ "GenSigSendType" SG_ 911 ATS_RLDrCurtainBtn 4;
BA_ "UserSigValidity" SG_ 911 ATS_RLDrCurtainBtn 3;
BA_ "NetworkRequest" SG_ 911 ATS_RLDrCurtainBtn 0;
BA_ "NetworkRequestHoldingTime" SG_ 911 ATS_RLDrCurtainBtn 5000;
BA_ "Version" SG_ 911 ATS_RLDrCurtainBtn "20.07.05";
BA_ "Description" SG_ 911 ATS_RRSunBlind "SunBlind Touch Botton";
BA_ "GenSigSendType" SG_ 911 ATS_RRSunBlind 4;
BA_ "UserSigValidity" SG_ 911 ATS_RRSunBlind 3;
BA_REL_ "GenSigTimeoutTime" BU_SG_REL_ RCM SG_ 911 ATS_RRSunBlind 0;
BA_REL_ "GenSigTimeoutTime" BU_SG_REL_ CGW_CCU SG_ 911 ATS_RRSunBlind 0;
BA_ "NetworkRequest" SG_ 911 ATS_RRSunBlind 0;
BA_ "NetworkRequestHoldingTime" SG_ 911 ATS_RRSunBlind 5000;
BA_ "Version" SG_ 911 ATS_RRSunBlind "20.07.05";
BA_ "Description" SG_ 911 ATS_FCS_LockTrayIniPwSet "Locking Tray ºñ¹Ð¹øÈ£ ¼³Á¤ ÁøÀÔ ¹öÆ°";
BA_ "GenSigSendType" SG_ 911 ATS_FCS_LockTrayIniPwSet 4;
BA_ "UserSigValidity" SG_ 911 ATS_FCS_LockTrayIniPwSet 3;
BA_REL_ "GenSigTimeoutTime" BU_SG_REL_ FCS SG_ 911 ATS_FCS_LockTrayIniPwSet 0;
BA_ "NetworkRequest" SG_ 911 ATS_FCS_LockTrayIniPwSet 0;
BA_ "NetworkRequestHoldingTime" SG_ 911 ATS_FCS_LockTrayIniPwSet 5000;
BA_ "Version" SG_ 911 ATS_FCS_LockTrayIniPwSet "21.01.02";
BA_ "Description" SG_ 911 ATS_FCS_LockTrayKeyPadNo "Locking Tray ºñ¹Ð¹øÈ£ ¼³Á¤ key Pad ¹öÆ°";
BA_ "GenSigSendType" SG_ 911 ATS_FCS_LockTrayKeyPadNo 4;
BA_ "UserSigValidity" SG_ 911 ATS_FCS_LockTrayKeyPadNo 3;
BA_REL_ "GenSigTimeoutTime" BU_SG_REL_ FCS SG_ 911 ATS_FCS_LockTrayKeyPadNo 0;
BA_ "NetworkRequest" SG_ 911 ATS_FCS_LockTrayKeyPadNo 0;
BA_ "NetworkRequestHoldingTime" SG_ 911 ATS_FCS_LockTrayKeyPadNo 5000;
BA_ "Version" SG_ 911 ATS_FCS_LockTrayKeyPadNo "21.01.02";
BA_ "Description" SG_ 911 ATS_FCS_LockTrayNoDel "Locking Tray ºñ¹Ð¹øÈ£ ¼³Á¤ ¼ýÀÚ »èÁ¦ ¹öÆ°";
BA_ "GenSigSendType" SG_ 911 ATS_FCS_LockTrayNoDel 4;
BA_ "UserSigValidity" SG_ 911 ATS_FCS_LockTrayNoDel 3;
BA_REL_ "GenSigTimeoutTime" BU_SG_REL_ FCS SG_ 911 ATS_FCS_LockTrayNoDel 0;
BA_ "NetworkRequest" SG_ 911 ATS_FCS_LockTrayNoDel 0;
BA_ "NetworkRequestHoldingTime" SG_ 911 ATS_FCS_LockTrayNoDel 5000;
BA_ "Version" SG_ 911 ATS_FCS_LockTrayNoDel "21.01.02";
BA_ "Description" SG_ 911 ATS_FCS_LockTrayNoClr "Locking Tray ºñ¹Ð¹øÈ£ ¼³Á¤ ¼ýÀÚ Clear ¹öÆ°";
BA_ "GenSigSendType" SG_ 911 ATS_FCS_LockTrayNoClr 4;
BA_ "UserSigValidity" SG_ 911 ATS_FCS_LockTrayNoClr 3;
BA_REL_ "GenSigTimeoutTime" BU_SG_REL_ FCS SG_ 911 ATS_FCS_LockTrayNoClr 0;
BA_ "NetworkRequest" SG_ 911 ATS_FCS_LockTrayNoClr 0;
BA_ "NetworkRequestHoldingTime" SG_ 911 ATS_FCS_LockTrayNoClr 5000;
BA_ "Version" SG_ 911 ATS_FCS_LockTrayNoClr "21.01.02";
BA_ "Description" SG_ 911 ATS_FCS_LockTrayPwChange "Locking Tray ºñ¹Ð¹øÈ£ º¯°æ ÁøÀÔ ¹öÆ°";
BA_ "GenSigSendType" SG_ 911 ATS_FCS_LockTrayPwChange 4;
BA_ "UserSigValidity" SG_ 911 ATS_FCS_LockTrayPwChange 3;
BA_REL_ "GenSigTimeoutTime" BU_SG_REL_ FCS SG_ 911 ATS_FCS_LockTrayPwChange 0;
BA_ "NetworkRequest" SG_ 911 ATS_FCS_LockTrayPwChange 0;
BA_ "NetworkRequestHoldingTime" SG_ 911 ATS_FCS_LockTrayPwChange 5000;
BA_ "Version" SG_ 911 ATS_FCS_LockTrayPwChange "21.01.02";
BA_ "Description" SG_ 911 ATS_FCS_LockTrayPwReset "Locking Tray ºñ¹Ð¹øÈ£ ÃÊ±âÈ­ ÁøÀÔ ¹öÆ° (ºñ¹Ð¹øÈ£ ¾ø´Â »óÅÂ·Î ¿øº¹)";
BA_ "GenSigSendType" SG_ 911 ATS_FCS_LockTrayPwReset 4;
BA_ "UserSigValidity" SG_ 911 ATS_FCS_LockTrayPwReset 3;
BA_REL_ "GenSigTimeoutTime" BU_SG_REL_ FCS SG_ 911 ATS_FCS_LockTrayPwReset 0;
BA_ "NetworkRequest" SG_ 911 ATS_FCS_LockTrayPwReset 0;
BA_ "NetworkRequestHoldingTime" SG_ 911 ATS_FCS_LockTrayPwReset 5000;
BA_ "Version" SG_ 911 ATS_FCS_LockTrayPwReset "21.01.02";
BA_ "Description" SG_ 911 ATS_FCS_LockTrayCancel "Locking Tray ºñ¹Ð¹øÈ£ ÀÔ·Â È­¸é Cancel ¹öÆ°";
BA_ "GenSigSendType" SG_ 911 ATS_FCS_LockTrayCancel 4;
BA_ "UserSigValidity" SG_ 911 ATS_FCS_LockTrayCancel 3;
BA_REL_ "GenSigTimeoutTime" BU_SG_REL_ FCS SG_ 911 ATS_FCS_LockTrayCancel 0;
BA_ "NetworkRequest" SG_ 911 ATS_FCS_LockTrayCancel 0;
BA_ "NetworkRequestHoldingTime" SG_ 911 ATS_FCS_LockTrayCancel 5000;
BA_ "Version" SG_ 911 ATS_FCS_LockTrayCancel "21.01.02";
BA_ "GenMsgSendType" BO_ 915 0;
BA_ "Description" SG_ 915 BCM_Crc18Val "The data area for CRC calculation is based on the data length (DLC) of the message DB.

The CRC shall be calculated over the entire data block (excluding the CRC bytes) including the user data, alive counter and Data ID 

 

- CRC Polynomial (0x1D) , Initial Value : 0x00, XOR value : 0xFF, Data ID Mode : Both, Data ID : Message ID + 0xF800 

- The initial value is for CRC calculation and the message should be sent with the calculated result value. 

The mathematical expression to 8 bit CRC polynomial is given here. G(x) = x8 + x4 + x3 + x2 + 1";
BA_ "GenSigSendType" SG_ 915 BCM_Crc18Val 4;
BA_ "GenSigStartValue" SG_ 915 BCM_Crc18Val 255;
BA_ "UserSigValidity" SG_ 915 BCM_Crc18Val 0;
BA_ "Version" SG_ 915 BCM_Crc18Val "19.07.02";
BA_ "Description" SG_ 915 BCM_AlvCnt18Val "For the first transmission request for a data element the counter shall be initialized with 0 and shall be incremented by 1

for every subsequent send request. When the counter reaches the maximum value(0xE), then it shall restart with 0 for the next send request";
BA_ "GenSigSendType" SG_ 915 BCM_AlvCnt18Val 4;
BA_ "UserSigValidity" SG_ 915 BCM_AlvCnt18Val 0;
BA_ "Version" SG_ 915 BCM_AlvCnt18Val "19.07.02";
BA_ "Description" SG_ 915 Trunk_IBU_OpnDiagSetSta "Trunk/TailGate open function diagnostic setting



 - Off : Normal mode

 - On : Restrict mode";
BA_ "GenSigSendType" SG_ 915 Trunk_IBU_OpnDiagSetSta 4;
BA_ "UserSigValidity" SG_ 915 Trunk_IBU_OpnDiagSetSta 0;
BA_ "NetworkRequest" SG_ 915 Trunk_IBU_OpnDiagSetSta 0;
BA_ "NetworkRequestHoldingTime" SG_ 915 Trunk_IBU_OpnDiagSetSta 5000;
BA_ "Version" SG_ 915 Trunk_IBU_OpnDiagSetSta "19.07.02";
BA_ "Description" SG_ 915 Trunk_TrnkTlgtReleaseRly "Trunk_TrunkTailgateOpenOutput for ICU

Trunk/Tailgate Release Relay Command

0x0:Off

0x1:On";
BA_ "GenSigSendType" SG_ 915 Trunk_TrnkTlgtReleaseRly 4;
BA_ "UserSigValidity" SG_ 915 Trunk_TrnkTlgtReleaseRly 0;
BA_ "NetworkRequest" SG_ 915 Trunk_TrnkTlgtReleaseRly 0;
BA_ "NetworkRequestHoldingTime" SG_ 915 Trunk_TrnkTlgtReleaseRly 5000;
BA_ "Version" SG_ 915 Trunk_TrnkTlgtReleaseRly "19.07.02";
BA_ "Description" SG_ 915 Trunk_TrnkTlgtOpenOutput_PTGM "Trunk_TrunkTailgateOpenOutput for PTGM

Trunk/Tailgate Open Command

0x0:Off

0x1:On";
BA_ "GenSigSendType" SG_ 915 Trunk_TrnkTlgtOpenOutput_PTGM 4;
BA_ "UserSigValidity" SG_ 915 Trunk_TrnkTlgtOpenOutput_PTGM 0;
BA_ "NetworkRequest" SG_ 915 Trunk_TrnkTlgtOpenOutput_PTGM 0;
BA_ "NetworkRequestHoldingTime" SG_ 915 Trunk_TrnkTlgtOpenOutput_PTGM 5000;
BA_ "Version" SG_ 915 Trunk_TrnkTlgtOpenOutput_PTGM "19.07.02";
BA_ "Description" SG_ 915 Trunk_TrnkTlgtOpenOutput_ICU "Trunk_TrunkTailgateOpenOutput for ICU

Trunk/Tailgate Open Command in PTG

0x0:Off

0x1:On";
BA_ "GenSigSendType" SG_ 915 Trunk_TrnkTlgtOpenOutput_ICU 4;
BA_ "UserSigValidity" SG_ 915 Trunk_TrnkTlgtOpenOutput_ICU 0;
BA_ "NetworkRequest" SG_ 915 Trunk_TrnkTlgtOpenOutput_ICU 0;
BA_ "NetworkRequestHoldingTime" SG_ 915 Trunk_TrnkTlgtOpenOutput_ICU 5000;
BA_ "Version" SG_ 915 Trunk_TrnkTlgtOpenOutput_ICU "19.07.02";
BA_ "Description" SG_ 915 Trunk_TrnkPassiveOpenOutput "Passive Trunk Open Output for ICU

Passive Trunk Release Relay Command

 - Off 

 - On";
BA_ "GenSigSendType" SG_ 915 Trunk_TrnkPassiveOpenOutput 4;
BA_ "UserSigValidity" SG_ 915 Trunk_TrnkPassiveOpenOutput 0;
BA_ "NetworkRequest" SG_ 915 Trunk_TrnkPassiveOpenOutput 0;
BA_ "NetworkRequestHoldingTime" SG_ 915 Trunk_TrnkPassiveOpenOutput 5000;
BA_ "Version" SG_ 915 Trunk_TrnkPassiveOpenOutput "19.07.02";
BA_ "Description" SG_ 915 TiltTele_CurProfileState "Current Profile ID State";
BA_ "GenSigSendType" SG_ 915 TiltTele_CurProfileState 4;
BA_ "UserSigValidity" SG_ 915 TiltTele_CurProfileState 0;
BA_REL_ "GenSigTimeoutTime" BU_SG_REL_ SCM SG_ 915 TiltTele_CurProfileState 1500;
BA_ "NetworkRequest" SG_ 915 TiltTele_CurProfileState 0;
BA_ "NetworkRequestHoldingTime" SG_ 915 TiltTele_CurProfileState 500;
BA_ "Version" SG_ 915 TiltTele_CurProfileState "20.08.02";
BA_ "Description" SG_ 915 TiltTele_USMEsyAcsSetState "Easy Access Option USM Set Response";
BA_ "GenSigSendType" SG_ 915 TiltTele_USMEsyAcsSetState 4;
BA_ "UserSigValidity" SG_ 915 TiltTele_USMEsyAcsSetState 0;
BA_REL_ "GenSigTimeoutTime" BU_SG_REL_ DPSU SG_ 915 TiltTele_USMEsyAcsSetState 1500;
BA_ "NetworkRequest" SG_ 915 TiltTele_USMEsyAcsSetState 0;
BA_ "NetworkRequestHoldingTime" SG_ 915 TiltTele_USMEsyAcsSetState 5000;
BA_ "Version" SG_ 915 TiltTele_USMEsyAcsSetState "20.08.02";
BA_ "Description" SG_ 915 TiltTele_PreEsyAcsProfile "Profile state for PreEasyAccess";
BA_ "GenSigSendType" SG_ 915 TiltTele_PreEsyAcsProfile 4;
BA_ "UserSigValidity" SG_ 915 TiltTele_PreEsyAcsProfile 0;
BA_REL_ "GenSigTimeoutTime" BU_SG_REL_ SCM SG_ 915 TiltTele_PreEsyAcsProfile 1500;
BA_ "NetworkRequest" SG_ 915 TiltTele_PreEsyAcsProfile 0;
BA_ "NetworkRequestHoldingTime" SG_ 915 TiltTele_PreEsyAcsProfile 5000;
BA_ "Version" SG_ 915 TiltTele_PreEsyAcsProfile "20.08.02";
BA_ "Description" SG_ 915 Tilt_MnlInitCmd "Command for Initialization by Tilt Manual Switch";
BA_ "GenSigSendType" SG_ 915 Tilt_MnlInitCmd 4;
BA_ "UserSigValidity" SG_ 915 Tilt_MnlInitCmd 0;
BA_REL_ "GenSigTimeoutTime" BU_SG_REL_ SCM SG_ 915 Tilt_MnlInitCmd 1500;
BA_ "NetworkRequest" SG_ 915 Tilt_MnlInitCmd 0;
BA_ "NetworkRequestHoldingTime" SG_ 915 Tilt_MnlInitCmd 5000;
BA_ "Version" SG_ 915 Tilt_MnlInitCmd "20.08.07";
BA_ "Description" SG_ 915 Tilt_MnlOpCmd "Command for Tilt Manual Operating";
BA_ "GenSigSendType" SG_ 915 Tilt_MnlOpCmd 4;
BA_ "UserSigValidity" SG_ 915 Tilt_MnlOpCmd 0;
BA_REL_ "GenSigTimeoutTime" BU_SG_REL_ SCM SG_ 915 Tilt_MnlOpCmd 1500;
BA_ "NetworkRequest" SG_ 915 Tilt_MnlOpCmd 0;
BA_ "NetworkRequestHoldingTime" SG_ 915 Tilt_MnlOpCmd 5000;
BA_ "Version" SG_ 915 Tilt_MnlOpCmd "20.08.07";
BA_ "Description" SG_ 915 Tele_MnlInitCmd "Command for Initialization by Tele Manual Switch";
BA_ "GenSigSendType" SG_ 915 Tele_MnlInitCmd 4;
BA_ "UserSigValidity" SG_ 915 Tele_MnlInitCmd 0;
BA_REL_ "GenSigTimeoutTime" BU_SG_REL_ SCM SG_ 915 Tele_MnlInitCmd 1500;
BA_ "NetworkRequest" SG_ 915 Tele_MnlInitCmd 0;
BA_ "NetworkRequestHoldingTime" SG_ 915 Tele_MnlInitCmd 5000;
BA_ "Version" SG_ 915 Tele_MnlInitCmd "20.08.07";
BA_ "Description" SG_ 915 Tilt_AutoOpCmd "Command for Tilt Auto Operating";
BA_ "GenSigSendType" SG_ 915 Tilt_AutoOpCmd 4;
BA_ "UserSigValidity" SG_ 915 Tilt_AutoOpCmd 0;
BA_REL_ "GenSigTimeoutTime" BU_SG_REL_ SCM SG_ 915 Tilt_AutoOpCmd 1500;
BA_ "NetworkRequest" SG_ 915 Tilt_AutoOpCmd 0;
BA_ "NetworkRequestHoldingTime" SG_ 915 Tilt_AutoOpCmd 5000;
BA_ "Version" SG_ 915 Tilt_AutoOpCmd "20.08.07";
BA_ "Description" SG_ 915 TiltTele_PlyBckState "Steering Column Playback Status for IMS";
BA_ "GenSigSendType" SG_ 915 TiltTele_PlyBckState 4;
BA_ "UserSigValidity" SG_ 915 TiltTele_PlyBckState 0;
BA_REL_ "GenSigTimeoutTime" BU_SG_REL_ DPSU SG_ 915 TiltTele_PlyBckState 1500;
BA_ "NetworkRequest" SG_ 915 TiltTele_PlyBckState 0;
BA_ "NetworkRequestHoldingTime" SG_ 915 TiltTele_PlyBckState 5000;
BA_ "Version" SG_ 915 TiltTele_PlyBckState "20.08.02";
BA_ "Description" SG_ 915 Tele_MnlOpCmd "Command for Tele Manual Operating";
BA_ "GenSigSendType" SG_ 915 Tele_MnlOpCmd 4;
BA_ "UserSigValidity" SG_ 915 Tele_MnlOpCmd 0;
BA_REL_ "GenSigTimeoutTime" BU_SG_REL_ SCM SG_ 915 Tele_MnlOpCmd 1500;
BA_ "NetworkRequest" SG_ 915 Tele_MnlOpCmd 0;
BA_ "NetworkRequestHoldingTime" SG_ 915 Tele_MnlOpCmd 5000;
BA_ "Version" SG_ 915 Tele_MnlOpCmd "20.08.07";
BA_ "Description" SG_ 915 Tele_AutoOpCmd "Command for Tele Auto Operating";
BA_ "GenSigSendType" SG_ 915 Tele_AutoOpCmd 4;
BA_ "UserSigValidity" SG_ 915 Tele_AutoOpCmd 0;
BA_REL_ "GenSigTimeoutTime" BU_SG_REL_ SCM SG_ 915 Tele_AutoOpCmd 1500;
BA_ "NetworkRequest" SG_ 915 Tele_AutoOpCmd 0;
BA_ "NetworkRequestHoldingTime" SG_ 915 Tele_AutoOpCmd 5000;
BA_ "Version" SG_ 915 Tele_AutoOpCmd "20.08.07";
BA_ "GenMsgSendType" BO_ 2382594817 0;
BA_ "VFrameFormat" BO_ 2382594817 1;
BA_ "Description" SG_ 2382594817 DATC_Crc6Val "The data area for CRC calculation is based on the data length (DLC) of the message DB.

The CRC shall be calculated over the entire data block (excluding the CRC bytes) including the user data, alive counter and Data ID

 

- CRC Polynomial (0x1021) , Initial Value : 0xFFFF, XOR value : 0x0000, Data ID : Message ID + 0xF800 

- The initial value is for CRC calculation and the message should be sent with the calculated result value. 

- The mathematical expression to 16 bit CRC polynomial is given here. G(x) = x16 + x12 + x5 + 1";
BA_ "GenSigSendType" SG_ 2382594817 DATC_Crc6Val 4;
BA_ "GenSigStartValue" SG_ 2382594817 DATC_Crc6Val 65535;
BA_ "UserSigValidity" SG_ 2382594817 DATC_Crc6Val 3;
BA_ "Version" SG_ 2382594817 DATC_Crc6Val "18.11.08";
BA_ "Description" SG_ 2382594817 DATC_AlvCnt6Val "For the first transmission request for a data element the counter shall be initialized with 0 and shall be incremented by 1 for every subsequent send request. 

When the counter reaches the maximum value(0xFF), then it shall restart with 0 for the next send request";
BA_ "GenSigSendType" SG_ 2382594817 DATC_AlvCnt6Val 4;
BA_ "UserSigValidity" SG_ 2382594817 DATC_AlvCnt6Val 3;
BA_ "Version" SG_ 2382594817 DATC_AlvCnt6Val "18.11.08";
BA_ "Description" SG_ 2382594817 DATC_MaxAcDis "This signal indicates Max A/C Graphic On & Off.

This signal occurs when Max A/C switch(button) is selected manually.";
BA_ "GenSigSendType" SG_ 2382594817 DATC_MaxAcDis 4;
BA_ "UserSigValidity" SG_ 2382594817 DATC_MaxAcDis 3;
BA_ "Version" SG_ 2382594817 DATC_MaxAcDis "17.11.00";
BA_ "Description" SG_ 2382594817 DATC_SyncDis "This signal indicates DUAL Graphic On & Off.

This signal occurs when DUAL switch(button) is selected either manually or automatically.";
BA_ "GenSigSendType" SG_ 2382594817 DATC_SyncDis 4;
BA_ "UserSigValidity" SG_ 2382594817 DATC_SyncDis 6;
BA_REL_ "GenSigTimeoutTime" BU_SG_REL_ ATS SG_ 2382594817 DATC_SyncDis 1500;
BA_ "Version" SG_ 2382594817 DATC_SyncDis "17.11.00";
BA_ "Description" SG_ 2382594817 DATC_OpSta "This signal indicates Operating status of DATC.";
BA_ "GenSigSendType" SG_ 2382594817 DATC_OpSta 4;
BA_ "UserSigValidity" SG_ 2382594817 DATC_OpSta 6;
BA_REL_ "GenSigTimeoutTime" BU_SG_REL_ ATS SG_ 2382594817 DATC_OpSta 1500;
BA_ "Version" SG_ 2382594817 DATC_OpSta "17.11.00";
BA_ "Description" SG_ 2382594817 DATC_FrDfgSta "This signal indicates DEF LED On & Off.

This signal occurs when DEF switch(button) is selected manually.";
BA_ "GenSigSendType" SG_ 2382594817 DATC_FrDfgSta 4;
BA_ "UserSigValidity" SG_ 2382594817 DATC_FrDfgSta 6;
BA_ "Version" SG_ 2382594817 DATC_FrDfgSta "17.11.00";
BA_ "Description" SG_ 2382594817 DATC_SmrtVntDis "Display Smart  Ventilation / Smart CO2  Ventilation";
BA_ "GenSigSendType" SG_ 2382594817 DATC_SmrtVntDis 4;
BA_ "UserSigValidity" SG_ 2382594817 DATC_SmrtVntDis 3;
BA_ "Version" SG_ 2382594817 DATC_SmrtVntDis "17.11.00";
BA_ "Description" SG_ 2382594817 DATC_AutoDfgBlnkDis "This signal indicates that Auto Defog LED blinks On & Off.

This signal occurs when Auto Defog system operates automatically.";
BA_ "GenSigSendType" SG_ 2382594817 DATC_AutoDfgBlnkDis 4;
BA_ "UserSigValidity" SG_ 2382594817 DATC_AutoDfgBlnkDis 6;
BA_ "Version" SG_ 2382594817 DATC_AutoDfgBlnkDis "17.11.00";
BA_ "Description" SG_ 2382594817 DATC_AutoDfgSysOffDis "Display Auto Defog System Off (When the user does not  use Auto Defog System on purpose)";
BA_ "GenSigSendType" SG_ 2382594817 DATC_AutoDfgSysOffDis 4;
BA_ "GenSigStartValue" SG_ 2382594817 DATC_AutoDfgSysOffDis 2;
BA_ "UserSigValidity" SG_ 2382594817 DATC_AutoDfgSysOffDis 3;
BA_ "Version" SG_ 2382594817 DATC_AutoDfgSysOffDis "17.11.00";
BA_ "Description" SG_ 2382594817 DATC_ArClnIND "This signal indicates Status of AirClean Button Indicator for MultiKeyboard.";
BA_ "GenSigSendType" SG_ 2382594817 DATC_ArClnIND 4;
BA_ "UserSigValidity" SG_ 2382594817 DATC_ArClnIND 7;
BA_REL_ "GenSigTimeoutTime" BU_SG_REL_ ATS SG_ 2382594817 DATC_ArClnIND 1500;
BA_ "Version" SG_ 2382594817 DATC_ArClnIND "19.08.03";
BA_ "Description" SG_ 2382594817 DATC_RrDfgInd "Rear Defog Switch indicator signal";
BA_ "GenSigSendType" SG_ 2382594817 DATC_RrDfgInd 4;
BA_ "UserSigValidity" SG_ 2382594817 DATC_RrDfgInd 7;
BA_ "Version" SG_ 2382594817 DATC_RrDfgInd "18.12.08";
BA_ "Description" SG_ 2382594817 DATC_FrModDEFInd "DATC_FrontModeDefIndicator

Mode DEF button indicator status signal in case All Mode Button Type";
BA_ "GenSigSendType" SG_ 2382594817 DATC_FrModDEFInd 4;
BA_ "UserSigValidity" SG_ 2382594817 DATC_FrModDEFInd 7;
BA_ "Version" SG_ 2382594817 DATC_FrModDEFInd "18.12.08";
BA_ "Description" SG_ 2382594817 DATC_FrModVentInd "DATC_FrontModeVentIndicator

Mode VENT button indicator status signal in case ALL Mode Button Type";
BA_ "GenSigSendType" SG_ 2382594817 DATC_FrModVentInd 4;
BA_ "UserSigValidity" SG_ 2382594817 DATC_FrModVentInd 7;
BA_ "Version" SG_ 2382594817 DATC_FrModVentInd "18.12.08";
BA_ "Description" SG_ 2382594817 DATC_FrModFloorInd "DATC_FrontModeFloorIndicator

Mode FLOOR button indicator status signal in case ALL Mode Button Type";
BA_ "GenSigSendType" SG_ 2382594817 DATC_FrModFloorInd 4;
BA_ "UserSigValidity" SG_ 2382594817 DATC_FrModFloorInd 7;
BA_ "Version" SG_ 2382594817 DATC_FrModFloorInd "18.12.08";
BA_ "GenMsgSendType" BO_ 2424580609 0;
BA_ "VFrameFormat" BO_ 2424580609 1;
BA_ "Description" SG_ 2424580609 DATC_Crc13Val "The data area for CRC calculation is based on the data length (DLC) of the message DB.

The CRC shall be calculated over the entire data block (excluding the CRC bytes) including the user data, alive counter and Data ID

 

- CRC Polynomial (0x1021) , Initial Value : 0xFFFF, XOR value : 0x0000, Data ID : Message ID + 0xF800 

- The initial value is for CRC calculation and the message should be sent with the calculated result value. 

- The mathematical expression to 16 bit CRC polynomial is given here. G(x) = x16 + x12 + x5 + 1";
BA_ "GenSigSendType" SG_ 2424580609 DATC_Crc13Val 4;
BA_ "GenSigStartValue" SG_ 2424580609 DATC_Crc13Val 65535;
BA_ "UserSigValidity" SG_ 2424580609 DATC_Crc13Val 3;
BA_ "Version" SG_ 2424580609 DATC_Crc13Val "18.11.08";
BA_ "Description" SG_ 2424580609 DATC_AlvCnt13Val "For the first transmission request for a data element the counter shall be initialized with 0 and shall be incremented by 1 for every subsequent send request. 

When the counter reaches the maximum value(0xFF), then it shall restart with 0 for the next send request";
BA_ "GenSigSendType" SG_ 2424580609 DATC_AlvCnt13Val 4;
BA_ "UserSigValidity" SG_ 2424580609 DATC_AlvCnt13Val 3;
BA_ "Version" SG_ 2424580609 DATC_AlvCnt13Val "18.11.08";
BA_ "GenSigSendType" SG_ 2424580609 DATC_MltAutoBlrTxt 4;
BA_ "UserSigValidity" SG_ 2424580609 DATC_MltAutoBlrTxt 7;
BA_REL_ "GenSigTimeoutTime" BU_SG_REL_ ATS SG_ 2424580609 DATC_MltAutoBlrTxt 1500;
BA_ "Version" SG_ 2424580609 DATC_MltAutoBlrTxt "20.02.04";
BA_ "GenSigSendType" SG_ 2424580609 DATC_MltAutoBlrTxt_Ps 4;
BA_ "UserSigValidity" SG_ 2424580609 DATC_MltAutoBlrTxt_Ps 7;
BA_REL_ "GenSigTimeoutTime" BU_SG_REL_ ATS SG_ 2424580609 DATC_MltAutoBlrTxt_Ps 1500;
BA_ "Version" SG_ 2424580609 DATC_MltAutoBlrTxt_Ps "20.02.04";
BA_ "GenSigSendType" SG_ 2424580609 DATC_MltAutoBlrTxt_Rr 4;
BA_ "UserSigValidity" SG_ 2424580609 DATC_MltAutoBlrTxt_Rr 7;
BA_REL_ "GenSigTimeoutTime" BU_SG_REL_ ATS SG_ 2424580609 DATC_MltAutoBlrTxt_Rr 1500;
BA_ "Version" SG_ 2424580609 DATC_MltAutoBlrTxt_Rr "20.02.04";
BA_ "Description" SG_ 2424580609 DATC_RLStTmblrSwReq "Rear Left Seat heater & cooler tumbler S/W";
BA_ "GenSigSendType" SG_ 2424580609 DATC_RLStTmblrSwReq 4;
BA_ "UserSigValidity" SG_ 2424580609 DATC_RLStTmblrSwReq 7;
BA_REL_ "GenSigTimeoutTime" BU_SG_REL_ RLHV SG_ 2424580609 DATC_RLStTmblrSwReq 1500;
BA_REL_ "GenSigTimeoutTime" BU_SG_REL_ RRHV SG_ 2424580609 DATC_RLStTmblrSwReq 1500;
BA_REL_ "GenSigTimeoutTime" BU_SG_REL_ SHVU_FR SG_ 2424580609 DATC_RLStTmblrSwReq 1500;
BA_REL_ "GenSigTimeoutTime" BU_SG_REL_ SHVU_RR SG_ 2424580609 DATC_RLStTmblrSwReq 1500;
BA_REL_ "GenSigTimeoutTime" BU_SG_REL_ RRPSU SG_ 2424580609 DATC_RLStTmblrSwReq 1500;
BA_REL_ "GenSigTimeoutTime" BU_SG_REL_ RLPSU SG_ 2424580609 DATC_RLStTmblrSwReq 1500;
BA_ "Version" SG_ 2424580609 DATC_RLStTmblrSwReq "20.07.10";
BA_ "Description" SG_ 2424580609 DATC_RRStTmblrSwReq "Rear Right Seat heater & cooler tumbler S/W";
BA_ "GenSigSendType" SG_ 2424580609 DATC_RRStTmblrSwReq 4;
BA_ "UserSigValidity" SG_ 2424580609 DATC_RRStTmblrSwReq 7;
BA_REL_ "GenSigTimeoutTime" BU_SG_REL_ RRHV SG_ 2424580609 DATC_RRStTmblrSwReq 1500;
BA_REL_ "GenSigTimeoutTime" BU_SG_REL_ SHVU_FR SG_ 2424580609 DATC_RRStTmblrSwReq 1500;
BA_REL_ "GenSigTimeoutTime" BU_SG_REL_ SHVU_RR SG_ 2424580609 DATC_RRStTmblrSwReq 1500;
BA_REL_ "GenSigTimeoutTime" BU_SG_REL_ RRPSU SG_ 2424580609 DATC_RRStTmblrSwReq 1500;
BA_REL_ "GenSigTimeoutTime" BU_SG_REL_ RLPSU SG_ 2424580609 DATC_RRStTmblrSwReq 1500;
BA_ "Version" SG_ 2424580609 DATC_RRStTmblrSwReq "20.07.10";
BA_ "Description" SG_ 2424580609 DATC_DisPnlState "This signal is used to change the front(rear) climate control panel status to the rear(front) climate control panel state when the REAR button is pressed.";
BA_ "GenSigSendType" SG_ 2424580609 DATC_DisPnlState 4;
BA_ "UserSigValidity" SG_ 2424580609 DATC_DisPnlState 7;
BA_ "Version" SG_ 2424580609 DATC_DisPnlState "20.02.01";
BA_ "Description" SG_ 2424580609 DATC_Opt5Typ "This signal indicates Option of HTR Control.



Bit0 : (After Blow) : 0 - After Blow Not Applied / 1 - After Blow Applied

Bit1 : (Fragrance) : 0 ? Fragrance System Not Applied / 1 ? Fragrance System Applied

Bit2~3 : Reserved";
BA_ "GenSigSendType" SG_ 2424580609 DATC_Opt5Typ 4;
BA_ "UserSigValidity" SG_ 2424580609 DATC_Opt5Typ 7;
BA_REL_ "GenSigTimeoutTime" BU_SG_REL_ ATS SG_ 2424580609 DATC_Opt5Typ 1500;
BA_ "Version" SG_ 2424580609 DATC_Opt5Typ "20.03.06";
BA_ "Description" SG_ 2424580609 DATC_BattPwrSum_Wh "accumulated energy consumption of battery while driving(200ms)";
BA_ "GenSigSendType" SG_ 2424580609 DATC_BattPwrSum_Wh 4;
BA_ "UserSigValidity" SG_ 2424580609 DATC_BattPwrSum_Wh 4;
BA_ "Version" SG_ 2424580609 DATC_BattPwrSum_Wh "18.09.00";
BA_ "GenMsgCycleTime" BO_ 1483 0;
BA_ "GenMsgCycleTimeFast" BO_ 1483 0;
BA_ "GenMsgNrOfRepetition" BO_ 1483 0;
BA_ "DiagResponse" BO_ 1483 1;
BA_ "GenMsgILSupport" BO_ 1483 0;
BA_ "TpMessage" BO_ 1483 1;
BA_ "TpTxIndex" BO_ 1483 215;
BA_ "Description" SG_ 1483 DSAU_GST_Byte0 "TP Index : 215";
BA_ "UsrSigPurpose" SG_ 1483 DSAU_GST_Byte0 4;
BA_ "UserSigValidity" SG_ 1483 DSAU_GST_Byte0 0;
BA_REL_ "GenSigTimeoutTime" BU_SG_REL_ CGW_CCU SG_ 1483 DSAU_GST_Byte0 0;
BA_ "NetworkRequest" SG_ 1483 DSAU_GST_Byte0 0;
BA_ "NetworkRequestHoldingTime" SG_ 1483 DSAU_GST_Byte0 5000;
BA_ "Version" SG_ 1483 DSAU_GST_Byte0 "21.02.04";
BA_ "Description" SG_ 1483 DSAU_GST_Byte2 "TP Index : 215";
BA_ "UsrSigPurpose" SG_ 1483 DSAU_GST_Byte2 4;
BA_ "UserSigValidity" SG_ 1483 DSAU_GST_Byte2 0;
BA_REL_ "GenSigTimeoutTime" BU_SG_REL_ CGW_CCU SG_ 1483 DSAU_GST_Byte2 0;
BA_ "NetworkRequest" SG_ 1483 DSAU_GST_Byte2 0;
BA_ "NetworkRequestHoldingTime" SG_ 1483 DSAU_GST_Byte2 5000;
BA_ "Version" SG_ 1483 DSAU_GST_Byte2 "21.02.04";
BA_ "Description" SG_ 1483 DSAU_GST_Byte3 "TP Index : 215";
BA_ "UsrSigPurpose" SG_ 1483 DSAU_GST_Byte3 4;
BA_ "UserSigValidity" SG_ 1483 DSAU_GST_Byte3 0;
BA_REL_ "GenSigTimeoutTime" BU_SG_REL_ CGW_CCU SG_ 1483 DSAU_GST_Byte3 0;
BA_ "NetworkRequest" SG_ 1483 DSAU_GST_Byte3 0;
BA_ "NetworkRequestHoldingTime" SG_ 1483 DSAU_GST_Byte3 5000;
BA_ "Version" SG_ 1483 DSAU_GST_Byte3 "21.02.04";
BA_ "Description" SG_ 1483 DSAU_GST_Byte4 "TP Index : 215";
BA_ "UsrSigPurpose" SG_ 1483 DSAU_GST_Byte4 4;
BA_ "UserSigValidity" SG_ 1483 DSAU_GST_Byte4 0;
BA_REL_ "GenSigTimeoutTime" BU_SG_REL_ CGW_CCU SG_ 1483 DSAU_GST_Byte4 0;
BA_ "NetworkRequest" SG_ 1483 DSAU_GST_Byte4 0;
BA_ "NetworkRequestHoldingTime" SG_ 1483 DSAU_GST_Byte4 5000;
BA_ "Version" SG_ 1483 DSAU_GST_Byte4 "21.02.04";
BA_ "Description" SG_ 1483 DSAU_GST_Byte5 "TP Index : 215";
BA_ "UsrSigPurpose" SG_ 1483 DSAU_GST_Byte5 4;
BA_ "UserSigValidity" SG_ 1483 DSAU_GST_Byte5 0;
BA_REL_ "GenSigTimeoutTime" BU_SG_REL_ CGW_CCU SG_ 1483 DSAU_GST_Byte5 0;
BA_ "NetworkRequest" SG_ 1483 DSAU_GST_Byte5 0;
BA_ "NetworkRequestHoldingTime" SG_ 1483 DSAU_GST_Byte5 5000;
BA_ "Version" SG_ 1483 DSAU_GST_Byte5 "21.02.04";
BA_ "Description" SG_ 1483 DSAU_GST_Byte6 "TP Index : 215";
BA_ "UsrSigPurpose" SG_ 1483 DSAU_GST_Byte6 4;
BA_ "UserSigValidity" SG_ 1483 DSAU_GST_Byte6 0;
BA_REL_ "GenSigTimeoutTime" BU_SG_REL_ CGW_CCU SG_ 1483 DSAU_GST_Byte6 0;
BA_ "NetworkRequest" SG_ 1483 DSAU_GST_Byte6 0;
BA_ "NetworkRequestHoldingTime" SG_ 1483 DSAU_GST_Byte6 5000;
BA_ "Version" SG_ 1483 DSAU_GST_Byte6 "21.02.04";
BA_ "Description" SG_ 1483 DSAU_GST_Byte7 "TP Index : 215";
BA_ "UsrSigPurpose" SG_ 1483 DSAU_GST_Byte7 4;
BA_ "UserSigValidity" SG_ 1483 DSAU_GST_Byte7 0;
BA_REL_ "GenSigTimeoutTime" BU_SG_REL_ CGW_CCU SG_ 1483 DSAU_GST_Byte7 0;
BA_ "NetworkRequest" SG_ 1483 DSAU_GST_Byte7 0;
BA_ "NetworkRequestHoldingTime" SG_ 1483 DSAU_GST_Byte7 5000;
BA_ "Version" SG_ 1483 DSAU_GST_Byte7 "21.02.04";
BA_ "Description" SG_ 1483 DSAU_GST_Byte1 "TP Index : 215";
BA_ "UsrSigPurpose" SG_ 1483 DSAU_GST_Byte1 4;
BA_ "UserSigValidity" SG_ 1483 DSAU_GST_Byte1 0;
BA_REL_ "GenSigTimeoutTime" BU_SG_REL_ CGW_CCU SG_ 1483 DSAU_GST_Byte1 0;
BA_ "NetworkRequest" SG_ 1483 DSAU_GST_Byte1 0;
BA_ "NetworkRequestHoldingTime" SG_ 1483 DSAU_GST_Byte1 5000;
BA_ "Version" SG_ 1483 DSAU_GST_Byte1 "21.02.04";
BA_ "GenMsgCycleTime" BO_ 1509 0;
BA_ "GenMsgCycleTimeFast" BO_ 1509 0;
BA_ "GenMsgNrOfRepetition" BO_ 1509 0;
BA_ "DiagRequest" BO_ 1509 1;
BA_ "GenMsgILSupport" BO_ 1509 0;
BA_ "TpMessage" BO_ 1509 1;
BA_ "TpTxIndex" BO_ 1509 107;
BA_ "Description" SG_ 1509 GST_ALBCU_Byte0 "TP Index : 107";
BA_ "UsrSigPurpose" SG_ 1509 GST_ALBCU_Byte0 3;
BA_ "UserSigValidity" SG_ 1509 GST_ALBCU_Byte0 0;
BA_REL_ "GenSigTimeoutTime" BU_SG_REL_ ALBCU SG_ 1509 GST_ALBCU_Byte0 0;
BA_ "NetworkRequest" SG_ 1509 GST_ALBCU_Byte0 0;
BA_ "NetworkRequestHoldingTime" SG_ 1509 GST_ALBCU_Byte0 5000;
BA_ "Version" SG_ 1509 GST_ALBCU_Byte0 "21.11.06";
BA_ "Description" SG_ 1509 GST_ALBCU_Byte2 "TP Index : 107";
BA_ "UsrSigPurpose" SG_ 1509 GST_ALBCU_Byte2 3;
BA_ "UserSigValidity" SG_ 1509 GST_ALBCU_Byte2 0;
BA_REL_ "GenSigTimeoutTime" BU_SG_REL_ ALBCU SG_ 1509 GST_ALBCU_Byte2 0;
BA_ "NetworkRequest" SG_ 1509 GST_ALBCU_Byte2 0;
BA_ "NetworkRequestHoldingTime" SG_ 1509 GST_ALBCU_Byte2 5000;
BA_ "Version" SG_ 1509 GST_ALBCU_Byte2 "21.11.06";
BA_ "Description" SG_ 1509 GST_ALBCU_Byte3 "TP Index : 107";
BA_ "UsrSigPurpose" SG_ 1509 GST_ALBCU_Byte3 3;
BA_ "UserSigValidity" SG_ 1509 GST_ALBCU_Byte3 0;
BA_REL_ "GenSigTimeoutTime" BU_SG_REL_ ALBCU SG_ 1509 GST_ALBCU_Byte3 0;
BA_ "NetworkRequest" SG_ 1509 GST_ALBCU_Byte3 0;
BA_ "NetworkRequestHoldingTime" SG_ 1509 GST_ALBCU_Byte3 5000;
BA_ "Version" SG_ 1509 GST_ALBCU_Byte3 "21.11.06";
BA_ "Description" SG_ 1509 GST_ALBCU_Byte4 "TP Index : 107";
BA_ "UsrSigPurpose" SG_ 1509 GST_ALBCU_Byte4 3;
BA_ "UserSigValidity" SG_ 1509 GST_ALBCU_Byte4 0;
BA_REL_ "GenSigTimeoutTime" BU_SG_REL_ ALBCU SG_ 1509 GST_ALBCU_Byte4 0;
BA_ "NetworkRequest" SG_ 1509 GST_ALBCU_Byte4 0;
BA_ "NetworkRequestHoldingTime" SG_ 1509 GST_ALBCU_Byte4 5000;
BA_ "Version" SG_ 1509 GST_ALBCU_Byte4 "21.11.06";
BA_ "Description" SG_ 1509 GST_ALBCU_Byte5 "TP Index : 107";
BA_ "UsrSigPurpose" SG_ 1509 GST_ALBCU_Byte5 3;
BA_ "UserSigValidity" SG_ 1509 GST_ALBCU_Byte5 0;
BA_REL_ "GenSigTimeoutTime" BU_SG_REL_ ALBCU SG_ 1509 GST_ALBCU_Byte5 0;
BA_ "NetworkRequest" SG_ 1509 GST_ALBCU_Byte5 0;
BA_ "NetworkRequestHoldingTime" SG_ 1509 GST_ALBCU_Byte5 5000;
BA_ "Version" SG_ 1509 GST_ALBCU_Byte5 "21.11.06";
BA_ "Description" SG_ 1509 GST_ALBCU_Byte6 "TP Index : 107";
BA_ "UsrSigPurpose" SG_ 1509 GST_ALBCU_Byte6 3;
BA_ "UserSigValidity" SG_ 1509 GST_ALBCU_Byte6 0;
BA_REL_ "GenSigTimeoutTime" BU_SG_REL_ ALBCU SG_ 1509 GST_ALBCU_Byte6 0;
BA_ "NetworkRequest" SG_ 1509 GST_ALBCU_Byte6 0;
BA_ "NetworkRequestHoldingTime" SG_ 1509 GST_ALBCU_Byte6 5000;
BA_ "Version" SG_ 1509 GST_ALBCU_Byte6 "21.11.06";
BA_ "Description" SG_ 1509 GST_ALBCU_Byte7 "TP Index : 107";
BA_ "UsrSigPurpose" SG_ 1509 GST_ALBCU_Byte7 3;
BA_ "UserSigValidity" SG_ 1509 GST_ALBCU_Byte7 0;
BA_REL_ "GenSigTimeoutTime" BU_SG_REL_ ALBCU SG_ 1509 GST_ALBCU_Byte7 0;
BA_ "NetworkRequest" SG_ 1509 GST_ALBCU_Byte7 0;
BA_ "NetworkRequestHoldingTime" SG_ 1509 GST_ALBCU_Byte7 5000;
BA_ "Version" SG_ 1509 GST_ALBCU_Byte7 "21.11.06";
BA_ "Description" SG_ 1509 GST_ALBCU_Byte1 "TP Index : 107";
BA_ "UsrSigPurpose" SG_ 1509 GST_ALBCU_Byte1 3;
BA_ "UserSigValidity" SG_ 1509 GST_ALBCU_Byte1 0;
BA_REL_ "GenSigTimeoutTime" BU_SG_REL_ ALBCU SG_ 1509 GST_ALBCU_Byte1 0;
BA_ "NetworkRequest" SG_ 1509 GST_ALBCU_Byte1 0;
BA_ "NetworkRequestHoldingTime" SG_ 1509 GST_ALBCU_Byte1 5000;
BA_ "Version" SG_ 1509 GST_ALBCU_Byte1 "21.11.06";
BA_ "GenMsgCycleTime" BO_ 2015 0;
BA_ "GenMsgCycleTimeFast" BO_ 2015 0;
BA_ "GenMsgNrOfRepetition" BO_ 2015 0;
BA_ "DiagState" BO_ 2015 1;
BA_ "GenMsgILSupport" BO_ 2015 0;
BA_ "TpMessage" BO_ 2015 1;
BA_ "Description" SG_ 2015 GST_ALL_Byte0 "TP Index : 0";
BA_ "UsrSigPurpose" SG_ 2015 GST_ALL_Byte0 0;
BA_ "UserSigValidity" SG_ 2015 GST_ALL_Byte0 0;
BA_REL_ "GenSigTimeoutTime" BU_SG_REL_ FCS SG_ 2015 GST_ALL_Byte0 0;
BA_REL_ "GenSigTimeoutTime" BU_SG_REL_ SCM SG_ 2015 GST_ALL_Byte0 0;
BA_REL_ "GenSigTimeoutTime" BU_SG_REL_ WPC SG_ 2015 GST_ALL_Byte0 0;
BA_REL_ "GenSigTimeoutTime" BU_SG_REL_ RWPC SG_ 2015 GST_ALL_Byte0 0;
BA_REL_ "GenSigTimeoutTime" BU_SG_REL_ PSB SG_ 2015 GST_ALL_Byte0 0;
BA_REL_ "GenSigTimeoutTime" BU_SG_REL_ SLB SG_ 2015 GST_ALL_Byte0 0;
BA_REL_ "GenSigTimeoutTime" BU_SG_REL_ SWRC SG_ 2015 GST_ALL_Byte0 0;
BA_REL_ "GenSigTimeoutTime" BU_SG_REL_ APSU SG_ 2015 GST_ALL_Byte0 0;
BA_REL_ "GenSigTimeoutTime" BU_SG_REL_ RLHV SG_ 2015 GST_ALL_Byte0 0;
BA_REL_ "GenSigTimeoutTime" BU_SG_REL_ RRHV SG_ 2015 GST_ALL_Byte0 0;
BA_REL_ "GenSigTimeoutTime" BU_SG_REL_ SHVU_FR SG_ 2015 GST_ALL_Byte0 0;
BA_REL_ "GenSigTimeoutTime" BU_SG_REL_ SHVU_RR SG_ 2015 GST_ALL_Byte0 0;
BA_REL_ "GenSigTimeoutTime" BU_SG_REL_ DPSU SG_ 2015 GST_ALL_Byte0 0;
BA_REL_ "GenSigTimeoutTime" BU_SG_REL_ DLBCU SG_ 2015 GST_ALL_Byte0 0;
BA_REL_ "GenSigTimeoutTime" BU_SG_REL_ PFSU SG_ 2015 GST_ALL_Byte0 0;
BA_REL_ "GenSigTimeoutTime" BU_SG_REL_ RCS SG_ 2015 GST_ALL_Byte0 0;
BA_REL_ "GenSigTimeoutTime" BU_SG_REL_ RRPSU SG_ 2015 GST_ALL_Byte0 0;
BA_REL_ "GenSigTimeoutTime" BU_SG_REL_ RLPSU SG_ 2015 GST_ALL_Byte0 0;
BA_REL_ "GenSigTimeoutTime" BU_SG_REL_ HOD SG_ 2015 GST_ALL_Byte0 0;
BA_REL_ "GenSigTimeoutTime" BU_SG_REL_ ATS SG_ 2015 GST_ALL_Byte0 0;
BA_REL_ "GenSigTimeoutTime" BU_SG_REL_ DSAU SG_ 2015 GST_ALL_Byte0 0;
BA_REL_ "GenSigTimeoutTime" BU_SG_REL_ ASAU SG_ 2015 GST_ALL_Byte0 0;
BA_REL_ "GenSigTimeoutTime" BU_SG_REL_ RCM SG_ 2015 GST_ALL_Byte0 0;
BA_REL_ "GenSigTimeoutTime" BU_SG_REL_ EMCU SG_ 2015 GST_ALL_Byte0 0;
BA_REL_ "GenSigTimeoutTime" BU_SG_REL_ SGU SG_ 2015 GST_ALL_Byte0 0;
BA_REL_ "GenSigTimeoutTime" BU_SG_REL_ ALBCU SG_ 2015 GST_ALL_Byte0 0;
BA_ "NetworkRequest" SG_ 2015 GST_ALL_Byte0 0;
BA_ "NetworkRequestHoldingTime" SG_ 2015 GST_ALL_Byte0 5000;
BA_ "Version" SG_ 2015 GST_ALL_Byte0 "21.02.04";
BA_ "Description" SG_ 2015 GST_ALL_Byte2 "TP Index : 0";
BA_ "UsrSigPurpose" SG_ 2015 GST_ALL_Byte2 0;
BA_ "UserSigValidity" SG_ 2015 GST_ALL_Byte2 0;
BA_REL_ "GenSigTimeoutTime" BU_SG_REL_ FCS SG_ 2015 GST_ALL_Byte2 0;
BA_REL_ "GenSigTimeoutTime" BU_SG_REL_ SCM SG_ 2015 GST_ALL_Byte2 0;
BA_REL_ "GenSigTimeoutTime" BU_SG_REL_ WPC SG_ 2015 GST_ALL_Byte2 0;
BA_REL_ "GenSigTimeoutTime" BU_SG_REL_ RWPC SG_ 2015 GST_ALL_Byte2 0;
BA_REL_ "GenSigTimeoutTime" BU_SG_REL_ PSB SG_ 2015 GST_ALL_Byte2 0;
BA_REL_ "GenSigTimeoutTime" BU_SG_REL_ SLB SG_ 2015 GST_ALL_Byte2 0;
BA_REL_ "GenSigTimeoutTime" BU_SG_REL_ SWRC SG_ 2015 GST_ALL_Byte2 0;
BA_REL_ "GenSigTimeoutTime" BU_SG_REL_ APSU SG_ 2015 GST_ALL_Byte2 0;
BA_REL_ "GenSigTimeoutTime" BU_SG_REL_ RLHV SG_ 2015 GST_ALL_Byte2 0;
BA_REL_ "GenSigTimeoutTime" BU_SG_REL_ RRHV SG_ 2015 GST_ALL_Byte2 0;
BA_REL_ "GenSigTimeoutTime" BU_SG_REL_ SHVU_FR SG_ 2015 GST_ALL_Byte2 0;
BA_REL_ "GenSigTimeoutTime" BU_SG_REL_ SHVU_RR SG_ 2015 GST_ALL_Byte2 0;
BA_REL_ "GenSigTimeoutTime" BU_SG_REL_ DPSU SG_ 2015 GST_ALL_Byte2 0;
BA_REL_ "GenSigTimeoutTime" BU_SG_REL_ DLBCU SG_ 2015 GST_ALL_Byte2 0;
BA_REL_ "GenSigTimeoutTime" BU_SG_REL_ PFSU SG_ 2015 GST_ALL_Byte2 0;
BA_REL_ "GenSigTimeoutTime" BU_SG_REL_ RCS SG_ 2015 GST_ALL_Byte2 0;
BA_REL_ "GenSigTimeoutTime" BU_SG_REL_ RRPSU SG_ 2015 GST_ALL_Byte2 0;
BA_REL_ "GenSigTimeoutTime" BU_SG_REL_ RLPSU SG_ 2015 GST_ALL_Byte2 0;
BA_REL_ "GenSigTimeoutTime" BU_SG_REL_ HOD SG_ 2015 GST_ALL_Byte2 0;
BA_REL_ "GenSigTimeoutTime" BU_SG_REL_ ATS SG_ 2015 GST_ALL_Byte2 0;
BA_REL_ "GenSigTimeoutTime" BU_SG_REL_ DSAU SG_ 2015 GST_ALL_Byte2 0;
BA_REL_ "GenSigTimeoutTime" BU_SG_REL_ ASAU SG_ 2015 GST_ALL_Byte2 0;
BA_REL_ "GenSigTimeoutTime" BU_SG_REL_ RCM SG_ 2015 GST_ALL_Byte2 0;
BA_REL_ "GenSigTimeoutTime" BU_SG_REL_ EMCU SG_ 2015 GST_ALL_Byte2 0;
BA_REL_ "GenSigTimeoutTime" BU_SG_REL_ SGU SG_ 2015 GST_ALL_Byte2 0;
BA_REL_ "GenSigTimeoutTime" BU_SG_REL_ ALBCU SG_ 2015 GST_ALL_Byte2 0;
BA_ "NetworkRequest" SG_ 2015 GST_ALL_Byte2 0;
BA_ "NetworkRequestHoldingTime" SG_ 2015 GST_ALL_Byte2 5000;
BA_ "Version" SG_ 2015 GST_ALL_Byte2 "21.02.04";
BA_ "Description" SG_ 2015 GST_ALL_Byte3 "TP Index : 0";
BA_ "UsrSigPurpose" SG_ 2015 GST_ALL_Byte3 0;
BA_ "UserSigValidity" SG_ 2015 GST_ALL_Byte3 0;
BA_REL_ "GenSigTimeoutTime" BU_SG_REL_ FCS SG_ 2015 GST_ALL_Byte3 0;
BA_REL_ "GenSigTimeoutTime" BU_SG_REL_ SCM SG_ 2015 GST_ALL_Byte3 0;
BA_REL_ "GenSigTimeoutTime" BU_SG_REL_ WPC SG_ 2015 GST_ALL_Byte3 0;
BA_REL_ "GenSigTimeoutTime" BU_SG_REL_ RWPC SG_ 2015 GST_ALL_Byte3 0;
BA_REL_ "GenSigTimeoutTime" BU_SG_REL_ PSB SG_ 2015 GST_ALL_Byte3 0;
BA_REL_ "GenSigTimeoutTime" BU_SG_REL_ SLB SG_ 2015 GST_ALL_Byte3 0;
BA_REL_ "GenSigTimeoutTime" BU_SG_REL_ SWRC SG_ 2015 GST_ALL_Byte3 0;
BA_REL_ "GenSigTimeoutTime" BU_SG_REL_ APSU SG_ 2015 GST_ALL_Byte3 0;
BA_REL_ "GenSigTimeoutTime" BU_SG_REL_ RLHV SG_ 2015 GST_ALL_Byte3 0;
BA_REL_ "GenSigTimeoutTime" BU_SG_REL_ RRHV SG_ 2015 GST_ALL_Byte3 0;
BA_REL_ "GenSigTimeoutTime" BU_SG_REL_ SHVU_FR SG_ 2015 GST_ALL_Byte3 0;
BA_REL_ "GenSigTimeoutTime" BU_SG_REL_ SHVU_RR SG_ 2015 GST_ALL_Byte3 0;
BA_REL_ "GenSigTimeoutTime" BU_SG_REL_ DPSU SG_ 2015 GST_ALL_Byte3 0;
BA_REL_ "GenSigTimeoutTime" BU_SG_REL_ DLBCU SG_ 2015 GST_ALL_Byte3 0;
BA_REL_ "GenSigTimeoutTime" BU_SG_REL_ PFSU SG_ 2015 GST_ALL_Byte3 0;
BA_REL_ "GenSigTimeoutTime" BU_SG_REL_ RCS SG_ 2015 GST_ALL_Byte3 0;
BA_REL_ "GenSigTimeoutTime" BU_SG_REL_ RRPSU SG_ 2015 GST_ALL_Byte3 0;
BA_REL_ "GenSigTimeoutTime" BU_SG_REL_ RLPSU SG_ 2015 GST_ALL_Byte3 0;
BA_REL_ "GenSigTimeoutTime" BU_SG_REL_ HOD SG_ 2015 GST_ALL_Byte3 0;
BA_REL_ "GenSigTimeoutTime" BU_SG_REL_ ATS SG_ 2015 GST_ALL_Byte3 0;
BA_REL_ "GenSigTimeoutTime" BU_SG_REL_ DSAU SG_ 2015 GST_ALL_Byte3 0;
BA_REL_ "GenSigTimeoutTime" BU_SG_REL_ ASAU SG_ 2015 GST_ALL_Byte3 0;
BA_REL_ "GenSigTimeoutTime" BU_SG_REL_ RCM SG_ 2015 GST_ALL_Byte3 0;
BA_REL_ "GenSigTimeoutTime" BU_SG_REL_ EMCU SG_ 2015 GST_ALL_Byte3 0;
BA_REL_ "GenSigTimeoutTime" BU_SG_REL_ SGU SG_ 2015 GST_ALL_Byte3 0;
BA_REL_ "GenSigTimeoutTime" BU_SG_REL_ ALBCU SG_ 2015 GST_ALL_Byte3 0;
BA_ "NetworkRequest" SG_ 2015 GST_ALL_Byte3 0;
BA_ "NetworkRequestHoldingTime" SG_ 2015 GST_ALL_Byte3 5000;
BA_ "Version" SG_ 2015 GST_ALL_Byte3 "21.02.04";
BA_ "Description" SG_ 2015 GST_ALL_Byte4 "TP Index : 0";
BA_ "UsrSigPurpose" SG_ 2015 GST_ALL_Byte4 0;
BA_ "UserSigValidity" SG_ 2015 GST_ALL_Byte4 0;
BA_REL_ "GenSigTimeoutTime" BU_SG_REL_ FCS SG_ 2015 GST_ALL_Byte4 0;
BA_REL_ "GenSigTimeoutTime" BU_SG_REL_ SCM SG_ 2015 GST_ALL_Byte4 0;
BA_REL_ "GenSigTimeoutTime" BU_SG_REL_ WPC SG_ 2015 GST_ALL_Byte4 0;
BA_REL_ "GenSigTimeoutTime" BU_SG_REL_ RWPC SG_ 2015 GST_ALL_Byte4 0;
BA_REL_ "GenSigTimeoutTime" BU_SG_REL_ PSB SG_ 2015 GST_ALL_Byte4 0;
BA_REL_ "GenSigTimeoutTime" BU_SG_REL_ SLB SG_ 2015 GST_ALL_Byte4 0;
BA_REL_ "GenSigTimeoutTime" BU_SG_REL_ SWRC SG_ 2015 GST_ALL_Byte4 0;
BA_REL_ "GenSigTimeoutTime" BU_SG_REL_ APSU SG_ 2015 GST_ALL_Byte4 0;
BA_REL_ "GenSigTimeoutTime" BU_SG_REL_ RLHV SG_ 2015 GST_ALL_Byte4 0;
BA_REL_ "GenSigTimeoutTime" BU_SG_REL_ RRHV SG_ 2015 GST_ALL_Byte4 0;
BA_REL_ "GenSigTimeoutTime" BU_SG_REL_ SHVU_FR SG_ 2015 GST_ALL_Byte4 0;
BA_REL_ "GenSigTimeoutTime" BU_SG_REL_ SHVU_RR SG_ 2015 GST_ALL_Byte4 0;
BA_REL_ "GenSigTimeoutTime" BU_SG_REL_ DPSU SG_ 2015 GST_ALL_Byte4 0;
BA_REL_ "GenSigTimeoutTime" BU_SG_REL_ DLBCU SG_ 2015 GST_ALL_Byte4 0;
BA_REL_ "GenSigTimeoutTime" BU_SG_REL_ PFSU SG_ 2015 GST_ALL_Byte4 0;
BA_REL_ "GenSigTimeoutTime" BU_SG_REL_ RCS SG_ 2015 GST_ALL_Byte4 0;
BA_REL_ "GenSigTimeoutTime" BU_SG_REL_ RRPSU SG_ 2015 GST_ALL_Byte4 0;
BA_REL_ "GenSigTimeoutTime" BU_SG_REL_ RLPSU SG_ 2015 GST_ALL_Byte4 0;
BA_REL_ "GenSigTimeoutTime" BU_SG_REL_ HOD SG_ 2015 GST_ALL_Byte4 0;
BA_REL_ "GenSigTimeoutTime" BU_SG_REL_ ATS SG_ 2015 GST_ALL_Byte4 0;
BA_REL_ "GenSigTimeoutTime" BU_SG_REL_ DSAU SG_ 2015 GST_ALL_Byte4 0;
BA_REL_ "GenSigTimeoutTime" BU_SG_REL_ ASAU SG_ 2015 GST_ALL_Byte4 0;
BA_REL_ "GenSigTimeoutTime" BU_SG_REL_ RCM SG_ 2015 GST_ALL_Byte4 0;
BA_REL_ "GenSigTimeoutTime" BU_SG_REL_ EMCU SG_ 2015 GST_ALL_Byte4 0;
BA_REL_ "GenSigTimeoutTime" BU_SG_REL_ SGU SG_ 2015 GST_ALL_Byte4 0;
BA_REL_ "GenSigTimeoutTime" BU_SG_REL_ ALBCU SG_ 2015 GST_ALL_Byte4 0;
BA_ "NetworkRequest" SG_ 2015 GST_ALL_Byte4 0;
BA_ "NetworkRequestHoldingTime" SG_ 2015 GST_ALL_Byte4 5000;
BA_ "Version" SG_ 2015 GST_ALL_Byte4 "21.02.04";
BA_ "Description" SG_ 2015 GST_ALL_Byte5 "TP Index : 0";
BA_ "UsrSigPurpose" SG_ 2015 GST_ALL_Byte5 0;
BA_ "UserSigValidity" SG_ 2015 GST_ALL_Byte5 0;
BA_REL_ "GenSigTimeoutTime" BU_SG_REL_ FCS SG_ 2015 GST_ALL_Byte5 0;
BA_REL_ "GenSigTimeoutTime" BU_SG_REL_ SCM SG_ 2015 GST_ALL_Byte5 0;
BA_REL_ "GenSigTimeoutTime" BU_SG_REL_ WPC SG_ 2015 GST_ALL_Byte5 0;
BA_REL_ "GenSigTimeoutTime" BU_SG_REL_ RWPC SG_ 2015 GST_ALL_Byte5 0;
BA_REL_ "GenSigTimeoutTime" BU_SG_REL_ PSB SG_ 2015 GST_ALL_Byte5 0;
BA_REL_ "GenSigTimeoutTime" BU_SG_REL_ SLB SG_ 2015 GST_ALL_Byte5 0;
BA_REL_ "GenSigTimeoutTime" BU_SG_REL_ SWRC SG_ 2015 GST_ALL_Byte5 0;
BA_REL_ "GenSigTimeoutTime" BU_SG_REL_ APSU SG_ 2015 GST_ALL_Byte5 0;
BA_REL_ "GenSigTimeoutTime" BU_SG_REL_ RLHV SG_ 2015 GST_ALL_Byte5 0;
BA_REL_ "GenSigTimeoutTime" BU_SG_REL_ RRHV SG_ 2015 GST_ALL_Byte5 0;
BA_REL_ "GenSigTimeoutTime" BU_SG_REL_ SHVU_FR SG_ 2015 GST_ALL_Byte5 0;
BA_REL_ "GenSigTimeoutTime" BU_SG_REL_ SHVU_RR SG_ 2015 GST_ALL_Byte5 0;
BA_REL_ "GenSigTimeoutTime" BU_SG_REL_ DPSU SG_ 2015 GST_ALL_Byte5 0;
BA_REL_ "GenSigTimeoutTime" BU_SG_REL_ DLBCU SG_ 2015 GST_ALL_Byte5 0;
BA_REL_ "GenSigTimeoutTime" BU_SG_REL_ PFSU SG_ 2015 GST_ALL_Byte5 0;
BA_REL_ "GenSigTimeoutTime" BU_SG_REL_ RCS SG_ 2015 GST_ALL_Byte5 0;
BA_REL_ "GenSigTimeoutTime" BU_SG_REL_ RRPSU SG_ 2015 GST_ALL_Byte5 0;
BA_REL_ "GenSigTimeoutTime" BU_SG_REL_ RLPSU SG_ 2015 GST_ALL_Byte5 0;
BA_REL_ "GenSigTimeoutTime" BU_SG_REL_ HOD SG_ 2015 GST_ALL_Byte5 0;
BA_REL_ "GenSigTimeoutTime" BU_SG_REL_ ATS SG_ 2015 GST_ALL_Byte5 0;
BA_REL_ "GenSigTimeoutTime" BU_SG_REL_ DSAU SG_ 2015 GST_ALL_Byte5 0;
BA_REL_ "GenSigTimeoutTime" BU_SG_REL_ ASAU SG_ 2015 GST_ALL_Byte5 0;
BA_REL_ "GenSigTimeoutTime" BU_SG_REL_ RCM SG_ 2015 GST_ALL_Byte5 0;
BA_REL_ "GenSigTimeoutTime" BU_SG_REL_ EMCU SG_ 2015 GST_ALL_Byte5 0;
BA_REL_ "GenSigTimeoutTime" BU_SG_REL_ SGU SG_ 2015 GST_ALL_Byte5 0;
BA_REL_ "GenSigTimeoutTime" BU_SG_REL_ ALBCU SG_ 2015 GST_ALL_Byte5 0;
BA_ "NetworkRequest" SG_ 2015 GST_ALL_Byte5 0;
BA_ "NetworkRequestHoldingTime" SG_ 2015 GST_ALL_Byte5 5000;
BA_ "Version" SG_ 2015 GST_ALL_Byte5 "21.02.04";
BA_ "Description" SG_ 2015 GST_ALL_Byte6 "TP Index : 0";
BA_ "UsrSigPurpose" SG_ 2015 GST_ALL_Byte6 0;
BA_ "UserSigValidity" SG_ 2015 GST_ALL_Byte6 0;
BA_REL_ "GenSigTimeoutTime" BU_SG_REL_ FCS SG_ 2015 GST_ALL_Byte6 0;
BA_REL_ "GenSigTimeoutTime" BU_SG_REL_ SCM SG_ 2015 GST_ALL_Byte6 0;
BA_REL_ "GenSigTimeoutTime" BU_SG_REL_ WPC SG_ 2015 GST_ALL_Byte6 0;
BA_REL_ "GenSigTimeoutTime" BU_SG_REL_ RWPC SG_ 2015 GST_ALL_Byte6 0;
BA_REL_ "GenSigTimeoutTime" BU_SG_REL_ PSB SG_ 2015 GST_ALL_Byte6 0;
BA_REL_ "GenSigTimeoutTime" BU_SG_REL_ SLB SG_ 2015 GST_ALL_Byte6 0;
BA_REL_ "GenSigTimeoutTime" BU_SG_REL_ SWRC SG_ 2015 GST_ALL_Byte6 0;
BA_REL_ "GenSigTimeoutTime" BU_SG_REL_ APSU SG_ 2015 GST_ALL_Byte6 0;
BA_REL_ "GenSigTimeoutTime" BU_SG_REL_ RLHV SG_ 2015 GST_ALL_Byte6 0;
BA_REL_ "GenSigTimeoutTime" BU_SG_REL_ RRHV SG_ 2015 GST_ALL_Byte6 0;
BA_REL_ "GenSigTimeoutTime" BU_SG_REL_ SHVU_FR SG_ 2015 GST_ALL_Byte6 0;
BA_REL_ "GenSigTimeoutTime" BU_SG_REL_ SHVU_RR SG_ 2015 GST_ALL_Byte6 0;
BA_REL_ "GenSigTimeoutTime" BU_SG_REL_ DPSU SG_ 2015 GST_ALL_Byte6 0;
BA_REL_ "GenSigTimeoutTime" BU_SG_REL_ DLBCU SG_ 2015 GST_ALL_Byte6 0;
BA_REL_ "GenSigTimeoutTime" BU_SG_REL_ PFSU SG_ 2015 GST_ALL_Byte6 0;
BA_REL_ "GenSigTimeoutTime" BU_SG_REL_ RCS SG_ 2015 GST_ALL_Byte6 0;
BA_REL_ "GenSigTimeoutTime" BU_SG_REL_ RRPSU SG_ 2015 GST_ALL_Byte6 0;
BA_REL_ "GenSigTimeoutTime" BU_SG_REL_ RLPSU SG_ 2015 GST_ALL_Byte6 0;
BA_REL_ "GenSigTimeoutTime" BU_SG_REL_ HOD SG_ 2015 GST_ALL_Byte6 0;
BA_REL_ "GenSigTimeoutTime" BU_SG_REL_ ATS SG_ 2015 GST_ALL_Byte6 0;
BA_REL_ "GenSigTimeoutTime" BU_SG_REL_ DSAU SG_ 2015 GST_ALL_Byte6 0;
BA_REL_ "GenSigTimeoutTime" BU_SG_REL_ ASAU SG_ 2015 GST_ALL_Byte6 0;
BA_REL_ "GenSigTimeoutTime" BU_SG_REL_ RCM SG_ 2015 GST_ALL_Byte6 0;
BA_REL_ "GenSigTimeoutTime" BU_SG_REL_ EMCU SG_ 2015 GST_ALL_Byte6 0;
BA_REL_ "GenSigTimeoutTime" BU_SG_REL_ SGU SG_ 2015 GST_ALL_Byte6 0;
BA_REL_ "GenSigTimeoutTime" BU_SG_REL_ ALBCU SG_ 2015 GST_ALL_Byte6 0;
BA_ "NetworkRequest" SG_ 2015 GST_ALL_Byte6 0;
BA_ "NetworkRequestHoldingTime" SG_ 2015 GST_ALL_Byte6 5000;
BA_ "Version" SG_ 2015 GST_ALL_Byte6 "21.02.04";
BA_ "Description" SG_ 2015 GST_ALL_Byte7 "TP Index : 0";
BA_ "UsrSigPurpose" SG_ 2015 GST_ALL_Byte7 0;
BA_ "UserSigValidity" SG_ 2015 GST_ALL_Byte7 0;
BA_REL_ "GenSigTimeoutTime" BU_SG_REL_ FCS SG_ 2015 GST_ALL_Byte7 0;
BA_REL_ "GenSigTimeoutTime" BU_SG_REL_ SCM SG_ 2015 GST_ALL_Byte7 0;
BA_REL_ "GenSigTimeoutTime" BU_SG_REL_ WPC SG_ 2015 GST_ALL_Byte7 0;
BA_REL_ "GenSigTimeoutTime" BU_SG_REL_ RWPC SG_ 2015 GST_ALL_Byte7 0;
BA_REL_ "GenSigTimeoutTime" BU_SG_REL_ PSB SG_ 2015 GST_ALL_Byte7 0;
BA_REL_ "GenSigTimeoutTime" BU_SG_REL_ SLB SG_ 2015 GST_ALL_Byte7 0;
BA_REL_ "GenSigTimeoutTime" BU_SG_REL_ SWRC SG_ 2015 GST_ALL_Byte7 0;
BA_REL_ "GenSigTimeoutTime" BU_SG_REL_ APSU SG_ 2015 GST_ALL_Byte7 0;
BA_REL_ "GenSigTimeoutTime" BU_SG_REL_ RLHV SG_ 2015 GST_ALL_Byte7 0;
BA_REL_ "GenSigTimeoutTime" BU_SG_REL_ RRHV SG_ 2015 GST_ALL_Byte7 0;
BA_REL_ "GenSigTimeoutTime" BU_SG_REL_ SHVU_FR SG_ 2015 GST_ALL_Byte7 0;
BA_REL_ "GenSigTimeoutTime" BU_SG_REL_ SHVU_RR SG_ 2015 GST_ALL_Byte7 0;
BA_REL_ "GenSigTimeoutTime" BU_SG_REL_ DPSU SG_ 2015 GST_ALL_Byte7 0;
BA_REL_ "GenSigTimeoutTime" BU_SG_REL_ DLBCU SG_ 2015 GST_ALL_Byte7 0;
BA_REL_ "GenSigTimeoutTime" BU_SG_REL_ PFSU SG_ 2015 GST_ALL_Byte7 0;
BA_REL_ "GenSigTimeoutTime" BU_SG_REL_ RCS SG_ 2015 GST_ALL_Byte7 0;
BA_REL_ "GenSigTimeoutTime" BU_SG_REL_ RRPSU SG_ 2015 GST_ALL_Byte7 0;
BA_REL_ "GenSigTimeoutTime" BU_SG_REL_ RLPSU SG_ 2015 GST_ALL_Byte7 0;
BA_REL_ "GenSigTimeoutTime" BU_SG_REL_ HOD SG_ 2015 GST_ALL_Byte7 0;
BA_REL_ "GenSigTimeoutTime" BU_SG_REL_ ATS SG_ 2015 GST_ALL_Byte7 0;
BA_REL_ "GenSigTimeoutTime" BU_SG_REL_ DSAU SG_ 2015 GST_ALL_Byte7 0;
BA_REL_ "GenSigTimeoutTime" BU_SG_REL_ ASAU SG_ 2015 GST_ALL_Byte7 0;
BA_REL_ "GenSigTimeoutTime" BU_SG_REL_ RCM SG_ 2015 GST_ALL_Byte7 0;
BA_REL_ "GenSigTimeoutTime" BU_SG_REL_ EMCU SG_ 2015 GST_ALL_Byte7 0;
BA_REL_ "GenSigTimeoutTime" BU_SG_REL_ SGU SG_ 2015 GST_ALL_Byte7 0;
BA_REL_ "GenSigTimeoutTime" BU_SG_REL_ ALBCU SG_ 2015 GST_ALL_Byte7 0;
BA_ "NetworkRequest" SG_ 2015 GST_ALL_Byte7 0;
BA_ "NetworkRequestHoldingTime" SG_ 2015 GST_ALL_Byte7 5000;
BA_ "Version" SG_ 2015 GST_ALL_Byte7 "21.02.04";
BA_ "Description" SG_ 2015 GST_ALL_Byte1 "TP Index : 0";
BA_ "UsrSigPurpose" SG_ 2015 GST_ALL_Byte1 0;
BA_ "UserSigValidity" SG_ 2015 GST_ALL_Byte1 0;
BA_REL_ "GenSigTimeoutTime" BU_SG_REL_ FCS SG_ 2015 GST_ALL_Byte1 0;
BA_REL_ "GenSigTimeoutTime" BU_SG_REL_ SCM SG_ 2015 GST_ALL_Byte1 0;
BA_REL_ "GenSigTimeoutTime" BU_SG_REL_ WPC SG_ 2015 GST_ALL_Byte1 0;
BA_REL_ "GenSigTimeoutTime" BU_SG_REL_ RWPC SG_ 2015 GST_ALL_Byte1 0;
BA_REL_ "GenSigTimeoutTime" BU_SG_REL_ PSB SG_ 2015 GST_ALL_Byte1 0;
BA_REL_ "GenSigTimeoutTime" BU_SG_REL_ SLB SG_ 2015 GST_ALL_Byte1 0;
BA_REL_ "GenSigTimeoutTime" BU_SG_REL_ SWRC SG_ 2015 GST_ALL_Byte1 0;
BA_REL_ "GenSigTimeoutTime" BU_SG_REL_ APSU SG_ 2015 GST_ALL_Byte1 0;
BA_REL_ "GenSigTimeoutTime" BU_SG_REL_ RLHV SG_ 2015 GST_ALL_Byte1 0;
BA_REL_ "GenSigTimeoutTime" BU_SG_REL_ RRHV SG_ 2015 GST_ALL_Byte1 0;
BA_REL_ "GenSigTimeoutTime" BU_SG_REL_ SHVU_FR SG_ 2015 GST_ALL_Byte1 0;
BA_REL_ "GenSigTimeoutTime" BU_SG_REL_ SHVU_RR SG_ 2015 GST_ALL_Byte1 0;
BA_REL_ "GenSigTimeoutTime" BU_SG_REL_ DPSU SG_ 2015 GST_ALL_Byte1 0;
BA_REL_ "GenSigTimeoutTime" BU_SG_REL_ DLBCU SG_ 2015 GST_ALL_Byte1 0;
BA_REL_ "GenSigTimeoutTime" BU_SG_REL_ PFSU SG_ 2015 GST_ALL_Byte1 0;
BA_REL_ "GenSigTimeoutTime" BU_SG_REL_ RCS SG_ 2015 GST_ALL_Byte1 0;
BA_REL_ "GenSigTimeoutTime" BU_SG_REL_ RRPSU SG_ 2015 GST_ALL_Byte1 0;
BA_REL_ "GenSigTimeoutTime" BU_SG_REL_ RLPSU SG_ 2015 GST_ALL_Byte1 0;
BA_REL_ "GenSigTimeoutTime" BU_SG_REL_ HOD SG_ 2015 GST_ALL_Byte1 0;
BA_REL_ "GenSigTimeoutTime" BU_SG_REL_ ATS SG_ 2015 GST_ALL_Byte1 0;
BA_REL_ "GenSigTimeoutTime" BU_SG_REL_ DSAU SG_ 2015 GST_ALL_Byte1 0;
BA_REL_ "GenSigTimeoutTime" BU_SG_REL_ ASAU SG_ 2015 GST_ALL_Byte1 0;
BA_REL_ "GenSigTimeoutTime" BU_SG_REL_ RCM SG_ 2015 GST_ALL_Byte1 0;
BA_REL_ "GenSigTimeoutTime" BU_SG_REL_ EMCU SG_ 2015 GST_ALL_Byte1 0;
BA_REL_ "GenSigTimeoutTime" BU_SG_REL_ SGU SG_ 2015 GST_ALL_Byte1 0;
BA_REL_ "GenSigTimeoutTime" BU_SG_REL_ ALBCU SG_ 2015 GST_ALL_Byte1 0;
BA_ "NetworkRequest" SG_ 2015 GST_ALL_Byte1 0;
BA_ "NetworkRequestHoldingTime" SG_ 2015 GST_ALL_Byte1 5000;
BA_ "Version" SG_ 2015 GST_ALL_Byte1 "21.02.04";
BA_ "GenMsgCycleTime" BO_ 1510 0;
BA_ "GenMsgCycleTimeFast" BO_ 1510 0;
BA_ "GenMsgNrOfRepetition" BO_ 1510 0;
BA_ "DiagRequest" BO_ 1510 1;
BA_ "GenMsgILSupport" BO_ 1510 0;
BA_ "TpMessage" BO_ 1510 1;
BA_ "TpTxIndex" BO_ 1510 108;
BA_ "Description" SG_ 1510 GST_APSS_Byte0 "TP Index : 108";
BA_ "UsrSigPurpose" SG_ 1510 GST_APSS_Byte0 3;
BA_ "UserSigValidity" SG_ 1510 GST_APSS_Byte0 0;
BA_REL_ "GenSigTimeoutTime" BU_SG_REL_ APSU SG_ 1510 GST_APSS_Byte0 0;
BA_ "NetworkRequest" SG_ 1510 GST_APSS_Byte0 0;
BA_ "NetworkRequestHoldingTime" SG_ 1510 GST_APSS_Byte0 5000;
BA_ "Version" SG_ 1510 GST_APSS_Byte0 "21.02.04";
BA_ "Description" SG_ 1510 GST_APSS_Byte2 "TP Index : 108";
BA_ "UsrSigPurpose" SG_ 1510 GST_APSS_Byte2 3;
BA_ "UserSigValidity" SG_ 1510 GST_APSS_Byte2 0;
BA_REL_ "GenSigTimeoutTime" BU_SG_REL_ APSU SG_ 1510 GST_APSS_Byte2 0;
BA_ "NetworkRequest" SG_ 1510 GST_APSS_Byte2 0;
BA_ "NetworkRequestHoldingTime" SG_ 1510 GST_APSS_Byte2 5000;
BA_ "Version" SG_ 1510 GST_APSS_Byte2 "21.02.04";
BA_ "Description" SG_ 1510 GST_APSS_Byte3 "TP Index : 108";
BA_ "UsrSigPurpose" SG_ 1510 GST_APSS_Byte3 3;
BA_ "UserSigValidity" SG_ 1510 GST_APSS_Byte3 0;
BA_REL_ "GenSigTimeoutTime" BU_SG_REL_ APSU SG_ 1510 GST_APSS_Byte3 0;
BA_ "NetworkRequest" SG_ 1510 GST_APSS_Byte3 0;
BA_ "NetworkRequestHoldingTime" SG_ 1510 GST_APSS_Byte3 5000;
BA_ "Version" SG_ 1510 GST_APSS_Byte3 "21.02.04";
BA_ "Description" SG_ 1510 GST_APSS_Byte4 "TP Index : 108";
BA_ "UsrSigPurpose" SG_ 1510 GST_APSS_Byte4 3;
BA_ "UserSigValidity" SG_ 1510 GST_APSS_Byte4 0;
BA_REL_ "GenSigTimeoutTime" BU_SG_REL_ APSU SG_ 1510 GST_APSS_Byte4 0;
BA_ "NetworkRequest" SG_ 1510 GST_APSS_Byte4 0;
BA_ "NetworkRequestHoldingTime" SG_ 1510 GST_APSS_Byte4 5000;
BA_ "Version" SG_ 1510 GST_APSS_Byte4 "21.02.04";
BA_ "Description" SG_ 1510 GST_APSS_Byte5 "TP Index : 108";
BA_ "UsrSigPurpose" SG_ 1510 GST_APSS_Byte5 3;
BA_ "UserSigValidity" SG_ 1510 GST_APSS_Byte5 0;
BA_REL_ "GenSigTimeoutTime" BU_SG_REL_ APSU SG_ 1510 GST_APSS_Byte5 0;
BA_ "NetworkRequest" SG_ 1510 GST_APSS_Byte5 0;
BA_ "NetworkRequestHoldingTime" SG_ 1510 GST_APSS_Byte5 5000;
BA_ "Version" SG_ 1510 GST_APSS_Byte5 "21.02.04";
BA_ "Description" SG_ 1510 GST_APSS_Byte6 "TP Index : 108";
BA_ "UsrSigPurpose" SG_ 1510 GST_APSS_Byte6 3;
BA_ "UserSigValidity" SG_ 1510 GST_APSS_Byte6 0;
BA_REL_ "GenSigTimeoutTime" BU_SG_REL_ APSU SG_ 1510 GST_APSS_Byte6 0;
BA_ "NetworkRequest" SG_ 1510 GST_APSS_Byte6 0;
BA_ "NetworkRequestHoldingTime" SG_ 1510 GST_APSS_Byte6 5000;
BA_ "Version" SG_ 1510 GST_APSS_Byte6 "21.02.04";
BA_ "Description" SG_ 1510 GST_APSS_Byte7 "TP Index : 108";
BA_ "UsrSigPurpose" SG_ 1510 GST_APSS_Byte7 3;
BA_ "UserSigValidity" SG_ 1510 GST_APSS_Byte7 0;
BA_REL_ "GenSigTimeoutTime" BU_SG_REL_ APSU SG_ 1510 GST_APSS_Byte7 0;
BA_ "NetworkRequest" SG_ 1510 GST_APSS_Byte7 0;
BA_ "NetworkRequestHoldingTime" SG_ 1510 GST_APSS_Byte7 5000;
BA_ "Version" SG_ 1510 GST_APSS_Byte7 "21.02.04";
BA_ "Description" SG_ 1510 GST_APSS_Byte1 "TP Index : 108";
BA_ "UsrSigPurpose" SG_ 1510 GST_APSS_Byte1 3;
BA_ "UserSigValidity" SG_ 1510 GST_APSS_Byte1 0;
BA_REL_ "GenSigTimeoutTime" BU_SG_REL_ APSU SG_ 1510 GST_APSS_Byte1 0;
BA_ "NetworkRequest" SG_ 1510 GST_APSS_Byte1 0;
BA_ "NetworkRequestHoldingTime" SG_ 1510 GST_APSS_Byte1 5000;
BA_ "Version" SG_ 1510 GST_APSS_Byte1 "21.02.04";
BA_ "GenMsgCycleTime" BO_ 1985 0;
BA_ "GenMsgCycleTimeFast" BO_ 1985 0;
BA_ "GenMsgNrOfRepetition" BO_ 1985 0;
BA_ "DiagRequest" BO_ 1985 1;
BA_ "GenMsgILSupport" BO_ 1985 0;
BA_ "TpMessage" BO_ 1985 1;
BA_ "TpTxIndex" BO_ 1985 154;
BA_ "Description" SG_ 1985 GST_PSB_Byte0 "TP Index : 154";
BA_ "UsrSigPurpose" SG_ 1985 GST_PSB_Byte0 3;
BA_ "UserSigValidity" SG_ 1985 GST_PSB_Byte0 0;
BA_REL_ "GenSigTimeoutTime" BU_SG_REL_ PSB SG_ 1985 GST_PSB_Byte0 0;
BA_ "NetworkRequest" SG_ 1985 GST_PSB_Byte0 0;
BA_ "NetworkRequestHoldingTime" SG_ 1985 GST_PSB_Byte0 5000;
BA_ "Version" SG_ 1985 GST_PSB_Byte0 "21.02.04";
BA_ "Description" SG_ 1985 GST_PSB_Byte2 "TP Index : 154";
BA_ "UsrSigPurpose" SG_ 1985 GST_PSB_Byte2 3;
BA_ "UserSigValidity" SG_ 1985 GST_PSB_Byte2 0;
BA_REL_ "GenSigTimeoutTime" BU_SG_REL_ PSB SG_ 1985 GST_PSB_Byte2 0;
BA_ "NetworkRequest" SG_ 1985 GST_PSB_Byte2 0;
BA_ "NetworkRequestHoldingTime" SG_ 1985 GST_PSB_Byte2 5000;
BA_ "Version" SG_ 1985 GST_PSB_Byte2 "21.02.04";
BA_ "Description" SG_ 1985 GST_PSB_Byte3 "TP Index : 154";
BA_ "UsrSigPurpose" SG_ 1985 GST_PSB_Byte3 3;
BA_ "UserSigValidity" SG_ 1985 GST_PSB_Byte3 0;
BA_REL_ "GenSigTimeoutTime" BU_SG_REL_ PSB SG_ 1985 GST_PSB_Byte3 0;
BA_ "NetworkRequest" SG_ 1985 GST_PSB_Byte3 0;
BA_ "NetworkRequestHoldingTime" SG_ 1985 GST_PSB_Byte3 5000;
BA_ "Version" SG_ 1985 GST_PSB_Byte3 "21.02.04";
BA_ "Description" SG_ 1985 GST_PSB_Byte4 "TP Index : 154";
BA_ "UsrSigPurpose" SG_ 1985 GST_PSB_Byte4 3;
BA_ "UserSigValidity" SG_ 1985 GST_PSB_Byte4 0;
BA_REL_ "GenSigTimeoutTime" BU_SG_REL_ PSB SG_ 1985 GST_PSB_Byte4 0;
BA_ "NetworkRequest" SG_ 1985 GST_PSB_Byte4 0;
BA_ "NetworkRequestHoldingTime" SG_ 1985 GST_PSB_Byte4 5000;
BA_ "Version" SG_ 1985 GST_PSB_Byte4 "21.02.04";
BA_ "Description" SG_ 1985 GST_PSB_Byte5 "TP Index : 154";
BA_ "UsrSigPurpose" SG_ 1985 GST_PSB_Byte5 3;
BA_ "UserSigValidity" SG_ 1985 GST_PSB_Byte5 0;
BA_REL_ "GenSigTimeoutTime" BU_SG_REL_ PSB SG_ 1985 GST_PSB_Byte5 0;
BA_ "NetworkRequest" SG_ 1985 GST_PSB_Byte5 0;
BA_ "NetworkRequestHoldingTime" SG_ 1985 GST_PSB_Byte5 5000;
BA_ "Version" SG_ 1985 GST_PSB_Byte5 "21.02.04";
BA_ "Description" SG_ 1985 GST_PSB_Byte6 "TP Index : 154";
BA_ "UsrSigPurpose" SG_ 1985 GST_PSB_Byte6 3;
BA_ "UserSigValidity" SG_ 1985 GST_PSB_Byte6 0;
BA_REL_ "GenSigTimeoutTime" BU_SG_REL_ PSB SG_ 1985 GST_PSB_Byte6 0;
BA_ "NetworkRequest" SG_ 1985 GST_PSB_Byte6 0;
BA_ "NetworkRequestHoldingTime" SG_ 1985 GST_PSB_Byte6 5000;
BA_ "Version" SG_ 1985 GST_PSB_Byte6 "21.02.04";
BA_ "Description" SG_ 1985 GST_PSB_Byte7 "TP Index : 154";
BA_ "UsrSigPurpose" SG_ 1985 GST_PSB_Byte7 3;
BA_ "UserSigValidity" SG_ 1985 GST_PSB_Byte7 0;
BA_REL_ "GenSigTimeoutTime" BU_SG_REL_ PSB SG_ 1985 GST_PSB_Byte7 0;
BA_ "NetworkRequest" SG_ 1985 GST_PSB_Byte7 0;
BA_ "NetworkRequestHoldingTime" SG_ 1985 GST_PSB_Byte7 5000;
BA_ "Version" SG_ 1985 GST_PSB_Byte7 "21.02.04";
BA_ "Description" SG_ 1985 GST_PSB_Byte1 "TP Index : 154";
BA_ "UsrSigPurpose" SG_ 1985 GST_PSB_Byte1 3;
BA_ "UserSigValidity" SG_ 1985 GST_PSB_Byte1 0;
BA_REL_ "GenSigTimeoutTime" BU_SG_REL_ PSB SG_ 1985 GST_PSB_Byte1 0;
BA_ "NetworkRequest" SG_ 1985 GST_PSB_Byte1 0;
BA_ "NetworkRequestHoldingTime" SG_ 1985 GST_PSB_Byte1 5000;
BA_ "Version" SG_ 1985 GST_PSB_Byte1 "21.02.04";
BA_ "GenMsgSendType" BO_ 912 0;
BA_ "Description" SG_ 912 HU_BLTN_CAM_UI_Mode "Display control of Built-in Cam UI mode. This Signal for Ethernet Type Built-in Cam.";
BA_ "GenSigSendType" SG_ 912 HU_BLTN_CAM_UI_Mode 4;
BA_ "UserSigValidity" SG_ 912 HU_BLTN_CAM_UI_Mode 1;
BA_REL_ "GenSigTimeoutTime" BU_SG_REL_ BLTN_CAM SG_ 912 HU_BLTN_CAM_UI_Mode 1500;
BA_ "RoutingFactor" SG_ 912 HU_BLTN_CAM_UI_Mode 0;
BA_ "Version" SG_ 912 HU_BLTN_CAM_UI_Mode "21.05.02";
BA_ "Description" SG_ 912 HU_BLTN_CAM_Display "Display control of Built-in Cam UI mode. This Signal for CAN Type Built-in Cam.(with Standard 5th Wide AVNT)";
BA_ "GenSigSendType" SG_ 912 HU_BLTN_CAM_Display 4;
BA_ "UserSigValidity" SG_ 912 HU_BLTN_CAM_Display 1;
BA_REL_ "GenSigTimeoutTime" BU_SG_REL_ BLTN_CAM SG_ 912 HU_BLTN_CAM_Display 1500;
BA_ "RoutingFactor" SG_ 912 HU_BLTN_CAM_Display 0;
BA_ "Version" SG_ 912 HU_BLTN_CAM_Display "21.05.02";
BA_ "GenMsgCycleTime" BO_ 1993 0;
BA_ "GenMsgCycleTimeFast" BO_ 1993 0;
BA_ "GenMsgNrOfRepetition" BO_ 1993 0;
BA_ "DiagResponse" BO_ 1993 1;
BA_ "GenMsgILSupport" BO_ 1993 0;
BA_ "TpMessage" BO_ 1993 1;
BA_ "TpTxIndex" BO_ 1993 154;
BA_ "Description" SG_ 1993 PSB_GST_Byte0 "TP Index : 154";
BA_ "UsrSigPurpose" SG_ 1993 PSB_GST_Byte0 4;
BA_ "UserSigValidity" SG_ 1993 PSB_GST_Byte0 0;
BA_REL_ "GenSigTimeoutTime" BU_SG_REL_ CGW_CCU SG_ 1993 PSB_GST_Byte0 0;
BA_ "NetworkRequest" SG_ 1993 PSB_GST_Byte0 0;
BA_ "NetworkRequestHoldingTime" SG_ 1993 PSB_GST_Byte0 5000;
BA_ "Version" SG_ 1993 PSB_GST_Byte0 "21.02.04";
BA_ "Description" SG_ 1993 PSB_GST_Byte2 "TP Index : 154";
BA_ "UsrSigPurpose" SG_ 1993 PSB_GST_Byte2 4;
BA_ "UserSigValidity" SG_ 1993 PSB_GST_Byte2 0;
BA_REL_ "GenSigTimeoutTime" BU_SG_REL_ CGW_CCU SG_ 1993 PSB_GST_Byte2 0;
BA_ "NetworkRequest" SG_ 1993 PSB_GST_Byte2 0;
BA_ "NetworkRequestHoldingTime" SG_ 1993 PSB_GST_Byte2 5000;
BA_ "Version" SG_ 1993 PSB_GST_Byte2 "21.02.04";
BA_ "Description" SG_ 1993 PSB_GST_Byte3 "TP Index : 154";
BA_ "UsrSigPurpose" SG_ 1993 PSB_GST_Byte3 4;
BA_ "UserSigValidity" SG_ 1993 PSB_GST_Byte3 0;
BA_REL_ "GenSigTimeoutTime" BU_SG_REL_ CGW_CCU SG_ 1993 PSB_GST_Byte3 0;
BA_ "NetworkRequest" SG_ 1993 PSB_GST_Byte3 0;
BA_ "NetworkRequestHoldingTime" SG_ 1993 PSB_GST_Byte3 5000;
BA_ "Version" SG_ 1993 PSB_GST_Byte3 "21.02.04";
BA_ "Description" SG_ 1993 PSB_GST_Byte4 "TP Index : 154";
BA_ "UsrSigPurpose" SG_ 1993 PSB_GST_Byte4 4;
BA_ "UserSigValidity" SG_ 1993 PSB_GST_Byte4 0;
BA_REL_ "GenSigTimeoutTime" BU_SG_REL_ CGW_CCU SG_ 1993 PSB_GST_Byte4 0;
BA_ "NetworkRequest" SG_ 1993 PSB_GST_Byte4 0;
BA_ "NetworkRequestHoldingTime" SG_ 1993 PSB_GST_Byte4 5000;
BA_ "Version" SG_ 1993 PSB_GST_Byte4 "21.02.04";
BA_ "Description" SG_ 1993 PSB_GST_Byte5 "TP Index : 154";
BA_ "UsrSigPurpose" SG_ 1993 PSB_GST_Byte5 4;
BA_ "UserSigValidity" SG_ 1993 PSB_GST_Byte5 0;
BA_REL_ "GenSigTimeoutTime" BU_SG_REL_ CGW_CCU SG_ 1993 PSB_GST_Byte5 0;
BA_ "NetworkRequest" SG_ 1993 PSB_GST_Byte5 0;
BA_ "NetworkRequestHoldingTime" SG_ 1993 PSB_GST_Byte5 5000;
BA_ "Version" SG_ 1993 PSB_GST_Byte5 "21.02.04";
BA_ "Description" SG_ 1993 PSB_GST_Byte6 "TP Index : 154";
BA_ "UsrSigPurpose" SG_ 1993 PSB_GST_Byte6 4;
BA_ "UserSigValidity" SG_ 1993 PSB_GST_Byte6 0;
BA_REL_ "GenSigTimeoutTime" BU_SG_REL_ CGW_CCU SG_ 1993 PSB_GST_Byte6 0;
BA_ "NetworkRequest" SG_ 1993 PSB_GST_Byte6 0;
BA_ "NetworkRequestHoldingTime" SG_ 1993 PSB_GST_Byte6 5000;
BA_ "Version" SG_ 1993 PSB_GST_Byte6 "21.02.04";
BA_ "Description" SG_ 1993 PSB_GST_Byte7 "TP Index : 154";
BA_ "UsrSigPurpose" SG_ 1993 PSB_GST_Byte7 4;
BA_ "UserSigValidity" SG_ 1993 PSB_GST_Byte7 0;
BA_REL_ "GenSigTimeoutTime" BU_SG_REL_ CGW_CCU SG_ 1993 PSB_GST_Byte7 0;
BA_ "NetworkRequest" SG_ 1993 PSB_GST_Byte7 0;
BA_ "NetworkRequestHoldingTime" SG_ 1993 PSB_GST_Byte7 5000;
BA_ "Version" SG_ 1993 PSB_GST_Byte7 "21.02.04";
BA_ "Description" SG_ 1993 PSB_GST_Byte1 "TP Index : 154";
BA_ "UsrSigPurpose" SG_ 1993 PSB_GST_Byte1 4;
BA_ "UserSigValidity" SG_ 1993 PSB_GST_Byte1 0;
BA_REL_ "GenSigTimeoutTime" BU_SG_REL_ CGW_CCU SG_ 1993 PSB_GST_Byte1 0;
BA_ "NetworkRequest" SG_ 1993 PSB_GST_Byte1 0;
BA_ "NetworkRequestHoldingTime" SG_ 1993 PSB_GST_Byte1 5000;
BA_ "Version" SG_ 1993 PSB_GST_Byte1 "21.02.04";
BA_ "GenMsgSendType" BO_ 913 0;
BA_ "Description" SG_ 913 PSD_Crc2Val "The data area for CRC calculation is based on the data length (DLC) of the message DB.

The CRC shall be calculated over the entire data block (excluding the CRC bytes) including the user data, alive counter and Data ID 

 

- CRC Polynomial (0x1D) , Initial Value : 0x00, XOR value : 0xFF, Data ID Mode : Both, Data ID : Message ID + 0xF800 

- The initial value is for CRC calculation and the message should be sent with the calculated result value. 

The mathematical expression to 8 bit CRC polynomial is given here. G(x) = x8 + x4 + x3 + x2 + 1";
BA_ "GenSigSendType" SG_ 913 PSD_Crc2Val 4;
BA_ "GenSigStartValue" SG_ 913 PSD_Crc2Val 255;
BA_ "UserSigValidity" SG_ 913 PSD_Crc2Val 0;
BA_ "NetworkRequest" SG_ 913 PSD_Crc2Val 0;
BA_ "NetworkRequestHoldingTime" SG_ 913 PSD_Crc2Val 5000;
BA_ "Version" SG_ 913 PSD_Crc2Val "19.01.09";
BA_ "Description" SG_ 913 PSD_AlvCnt2Val "For the first transmission request for a data element the counter shall be initialized with 0 and shall be incremented by 1

for every subsequent send request. When the counter reaches the maximum value(0xE), then it shall restart with 0 for the next send request";
BA_ "GenSigSendType" SG_ 913 PSD_AlvCnt2Val 4;
BA_ "UserSigValidity" SG_ 913 PSD_AlvCnt2Val 0;
BA_ "NetworkRequest" SG_ 913 PSD_AlvCnt2Val 0;
BA_ "NetworkRequestHoldingTime" SG_ 913 PSD_AlvCnt2Val 5000;
BA_ "Version" SG_ 913 PSD_AlvCnt2Val "19.01.09";
BA_ "Description" SG_ 913 PSD_USMSetSta "PSD USM Setting Signal";
BA_ "GenSigSendType" SG_ 913 PSD_USMSetSta 4;
BA_ "UserSigValidity" SG_ 913 PSD_USMSetSta 3;
BA_ "NetworkRequest" SG_ 913 PSD_USMSetSta 0;
BA_ "NetworkRequestHoldingTime" SG_ 913 PSD_USMSetSta 5000;
BA_ "Version" SG_ 913 PSD_USMSetSta "18.12.07";
BA_ "Description" SG_ 913 Lamp_HzrdSta "- Hazard Flashing when PSD is opening

- Initial Value: 2";
BA_ "GenSigSendType" SG_ 913 Lamp_HzrdSta 4;
BA_ "GenSigStartValue" SG_ 913 Lamp_HzrdSta 2;
BA_ "UserSigValidity" SG_ 913 Lamp_HzrdSta 0;
BA_ "NetworkRequest" SG_ 913 Lamp_HzrdSta 0;
BA_ "NetworkRequestHoldingTime" SG_ 913 Lamp_HzrdSta 5000;
BA_ "Version" SG_ 913 Lamp_HzrdSta "21.07.05";
BA_ "GenSigSendType" SG_ 913 PSD_OptTyp 4;
BA_ "UserSigValidity" SG_ 913 PSD_OptTyp 0;
BA_ "NetworkRequest" SG_ 913 PSD_OptTyp 0;
BA_ "NetworkRequestHoldingTime" SG_ 913 PSD_OptTyp 5000;
BA_ "Version" SG_ 913 PSD_OptTyp "21.07.05";
BA_ "Description" SG_ 913 PSD_LHSEAActivated "LH SEA Activation State";
BA_ "GenSigSendType" SG_ 913 PSD_LHSEAActivated 4;
BA_ "UserSigValidity" SG_ 913 PSD_LHSEAActivated 0;
BA_ "NetworkRequest" SG_ 913 PSD_LHSEAActivated 0;
BA_ "NetworkRequestHoldingTime" SG_ 913 PSD_LHSEAActivated 5000;
BA_ "Version" SG_ 913 PSD_LHSEAActivated "19.01.08";
BA_ "Description" SG_ 913 PSD_RHSEAActivated "RH SEA Activation State";
BA_ "GenSigSendType" SG_ 913 PSD_RHSEAActivated 4;
BA_ "UserSigValidity" SG_ 913 PSD_RHSEAActivated 0;
BA_ "NetworkRequest" SG_ 913 PSD_RHSEAActivated 0;
BA_ "NetworkRequestHoldingTime" SG_ 913 PSD_RHSEAActivated 5000;
BA_ "Version" SG_ 913 PSD_RHSEAActivated "19.01.08";
BA_ "Description" SG_ 913 PSD_LHPSDLatchState "LH PSD LatchState

- 0x0 : Close status

- 0x1~0x4 : Open status

- 0x5 : Unknown status

- 0x6 : Error status";
BA_ "GenSigSendType" SG_ 913 PSD_LHPSDLatchState 4;
BA_ "GenSigStartValue" SG_ 913 PSD_LHPSDLatchState 5;
BA_ "UserSigValidity" SG_ 913 PSD_LHPSDLatchState 0;
BA_REL_ "GenSigTimeoutTime" BU_SG_REL_ PFSU SG_ 913 PSD_LHPSDLatchState 1500;
BA_ "NetworkRequest" SG_ 913 PSD_LHPSDLatchState 0;
BA_ "NetworkRequestHoldingTime" SG_ 913 PSD_LHPSDLatchState 5000;
BA_ "Version" SG_ 913 PSD_LHPSDLatchState "21.07.05";
BA_ "Description" SG_ 913 PSD_RHPSDLatchState "RH PSD Latch state

- 0x0 : Close status

- 0x1~0x4 : Open status

- 0x5 : Unknown status

- 0x6 : Error status";
BA_ "GenSigSendType" SG_ 913 PSD_RHPSDLatchState 4;
BA_ "GenSigStartValue" SG_ 913 PSD_RHPSDLatchState 5;
BA_ "UserSigValidity" SG_ 913 PSD_RHPSDLatchState 0;
BA_REL_ "GenSigTimeoutTime" BU_SG_REL_ PFSU SG_ 913 PSD_RHPSDLatchState 1500;
BA_ "NetworkRequest" SG_ 913 PSD_RHPSDLatchState 0;
BA_ "NetworkRequestHoldingTime" SG_ 913 PSD_RHPSDLatchState 5000;
BA_ "Version" SG_ 913 PSD_RHPSDLatchState "21.07.05";
BA_ "Description" SG_ 913 C_PSDOptLHRH "PSD LH/RH Option";
BA_ "GenSigSendType" SG_ 913 C_PSDOptLHRH 4;
BA_ "UserSigValidity" SG_ 913 C_PSDOptLHRH 0;
BA_ "Version" SG_ 913 C_PSDOptLHRH "21.07.05";
BA_ "Description" SG_ 913 PSD_AllDrOpnSetRValue "All Door(PSD PTG) Open Function by FOB Unlock Long Key USM Setting Signal

0x0 : Not Display in USM

0x1 : All Door Open Function Off

0x2 : Only PSD Open by FOB Unlock Long Key

0x3 : PSD and PTG Open by FOB Unlock Long Key

0x4~0x6 : Reserved

0x7 : Gray in USM";
BA_ "GenSigSendType" SG_ 913 PSD_AllDrOpnSetRValue 4;
BA_ "UserSigValidity" SG_ 913 PSD_AllDrOpnSetRValue 0;
BA_ "NetworkRequest" SG_ 913 PSD_AllDrOpnSetRValue 0;
BA_ "NetworkRequestHoldingTime" SG_ 913 PSD_AllDrOpnSetRValue 5000;
BA_ "Version" SG_ 913 PSD_AllDrOpnSetRValue "21.07.05";
BA_ "Description" SG_ 913 PSD_USMAllDrOpenSet "All Door Open Function by FOB Unlock Long Key Setting Signal for PTG by PSD";
BA_ "GenSigSendType" SG_ 913 PSD_USMAllDrOpenSet 4;
BA_ "UserSigValidity" SG_ 913 PSD_USMAllDrOpenSet 0;
BA_ "NetworkRequest" SG_ 913 PSD_USMAllDrOpenSet 0;
BA_ "NetworkRequestHoldingTime" SG_ 913 PSD_USMAllDrOpenSet 5000;
BA_ "Version" SG_ 913 PSD_USMAllDrOpenSet "19.11.05";
BA_ "Description" SG_ 913 PSD_ModSta "PSD Moudule Status";
BA_ "GenSigSendType" SG_ 913 PSD_ModSta 4;
BA_ "UserSigValidity" SG_ 913 PSD_ModSta 0;
BA_ "NetworkRequest" SG_ 913 PSD_ModSta 0;
BA_ "NetworkRequestHoldingTime" SG_ 913 PSD_ModSta 5000;
BA_ "Version" SG_ 913 PSD_ModSta "21.07.05";
BA_ "GenMsgSendType" BO_ 902 0;
BA_ "GenSigSendType" SG_ 902 PSM_DrvStEsyAcsUSMSta 4;
BA_ "UserSigValidity" SG_ 902 PSM_DrvStEsyAcsUSMSta 0;
BA_REL_ "GenSigTimeoutTime" BU_SG_REL_ DLBCU SG_ 902 PSM_DrvStEsyAcsUSMSta 1500;
BA_REL_ "GenSigTimeoutTime" BU_SG_REL_ DSAU SG_ 902 PSM_DrvStEsyAcsUSMSta 1500;
BA_REL_ "GenSigTimeoutTime" BU_SG_REL_ CGW_CCU SG_ 902 PSM_DrvStEsyAcsUSMSta 1500;
BA_ "NetworkRequest" SG_ 902 PSM_DrvStEsyAcsUSMSta 0;
BA_ "NetworkRequestHoldingTime" SG_ 902 PSM_DrvStEsyAcsUSMSta 5000;
BA_ "Version" SG_ 902 PSM_DrvStEsyAcsUSMSta "17.11.00";
BA_ "Description" SG_ 902 PSM_SeatPosPlyBck_Sta "The signal indicates the state of Driver's seat position playing back.";
BA_ "GenSigSendType" SG_ 902 PSM_SeatPosPlyBck_Sta 4;
BA_ "UserSigValidity" SG_ 902 PSM_SeatPosPlyBck_Sta 0;
BA_ "Version" SG_ 902 PSM_SeatPosPlyBck_Sta "20.03.01";
BA_ "Description" SG_ 902 PSM_SeatPos_Sta "The signal indicates the state of  Driver seat Meomry State";
BA_ "GenSigSendType" SG_ 902 PSM_SeatPos_Sta 4;
BA_ "UserSigValidity" SG_ 902 PSM_SeatPos_Sta 0;
BA_ "Version" SG_ 902 PSM_SeatPos_Sta "20.03.01";
BA_ "Description" SG_ 902 PSM_SeatPosSldLmt_Sta "PSM Slide end Position and limit Initialize State information";
BA_ "GenSigSendType" SG_ 902 PSM_SeatPosSldLmt_Sta 4;
BA_ "UserSigValidity" SG_ 902 PSM_SeatPosSldLmt_Sta 0;
BA_REL_ "GenSigTimeoutTime" BU_SG_REL_ CGW_CCU SG_ 902 PSM_SeatPosSldLmt_Sta 1500;
BA_ "NetworkRequest" SG_ 902 PSM_SeatPosSldLmt_Sta 0;
BA_ "NetworkRequestHoldingTime" SG_ 902 PSM_SeatPosSldLmt_Sta 5000;
BA_ "Version" SG_ 902 PSM_SeatPosSldLmt_Sta "20.03.01";
BA_ "Description" SG_ 902 PSM_SeatPosRclnLmt_Sta "PSM Recline end Position and limit Initialize State information";
BA_ "GenSigSendType" SG_ 902 PSM_SeatPosRclnLmt_Sta 4;
BA_ "UserSigValidity" SG_ 902 PSM_SeatPosRclnLmt_Sta 0;
BA_REL_ "GenSigTimeoutTime" BU_SG_REL_ CGW_CCU SG_ 902 PSM_SeatPosRclnLmt_Sta 1500;
BA_ "NetworkRequest" SG_ 902 PSM_SeatPosRclnLmt_Sta 0;
BA_ "NetworkRequestHoldingTime" SG_ 902 PSM_SeatPosRclnLmt_Sta 5000;
BA_ "Version" SG_ 902 PSM_SeatPosRclnLmt_Sta "20.03.01";
BA_ "Description" SG_ 902 SmrtIMS_StatureRspVal "User height information response value for Health Care IMS";
BA_ "GenSigSendType" SG_ 902 SmrtIMS_StatureRspVal 4;
BA_ "UserSigValidity" SG_ 902 SmrtIMS_StatureRspVal 0;
BA_REL_ "GenSigTimeoutTime" BU_SG_REL_ CGW_CCU SG_ 902 SmrtIMS_StatureRspVal 1500;
BA_ "NetworkRequest" SG_ 902 SmrtIMS_StatureRspVal 0;
BA_ "NetworkRequestHoldingTime" SG_ 902 SmrtIMS_StatureRspVal 5000;
BA_ "Version" SG_ 902 SmrtIMS_StatureRspVal "17.11.00";
BA_ "Description" SG_ 902 SmrtIMS_SeatedHghtRspVal "User sit height information response value for Health Care IMS";
BA_ "GenSigSendType" SG_ 902 SmrtIMS_SeatedHghtRspVal 4;
BA_ "UserSigValidity" SG_ 902 SmrtIMS_SeatedHghtRspVal 0;
BA_REL_ "GenSigTimeoutTime" BU_SG_REL_ CGW_CCU SG_ 902 SmrtIMS_SeatedHghtRspVal 1500;
BA_ "NetworkRequest" SG_ 902 SmrtIMS_SeatedHghtRspVal 0;
BA_ "NetworkRequestHoldingTime" SG_ 902 SmrtIMS_SeatedHghtRspVal 5000;
BA_ "Version" SG_ 902 SmrtIMS_SeatedHghtRspVal "17.11.00";
BA_ "Description" SG_ 902 SmrtIMS_WghtRspVal "User weight information repsponse value for Health Care IMS";
BA_ "GenSigSendType" SG_ 902 SmrtIMS_WghtRspVal 4;
BA_ "UserSigValidity" SG_ 902 SmrtIMS_WghtRspVal 0;
BA_REL_ "GenSigTimeoutTime" BU_SG_REL_ CGW_CCU SG_ 902 SmrtIMS_WghtRspVal 1500;
BA_ "NetworkRequest" SG_ 902 SmrtIMS_WghtRspVal 0;
BA_ "NetworkRequestHoldingTime" SG_ 902 SmrtIMS_WghtRspVal 5000;
BA_ "Version" SG_ 902 SmrtIMS_WghtRspVal "17.11.00";
BA_ "Description" SG_ 902 SmartIMS_DisReq "For displaying the state of seat moving";
BA_ "GenSigSendType" SG_ 902 SmartIMS_DisReq 4;
BA_ "UserSigValidity" SG_ 902 SmartIMS_DisReq 0;
BA_REL_ "GenSigTimeoutTime" BU_SG_REL_ CGW_CCU SG_ 902 SmartIMS_DisReq 1500;
BA_ "NetworkRequest" SG_ 902 SmartIMS_DisReq 0;
BA_ "NetworkRequestHoldingTime" SG_ 902 SmartIMS_DisReq 5000;
BA_ "Version" SG_ 902 SmartIMS_DisReq "17.11.00";
BA_ "Description" SG_ 902 SmrtIMS_ExitSta "-(Old)C_SmartIMSExit";
BA_ "GenSigSendType" SG_ 902 SmrtIMS_ExitSta 4;
BA_ "UserSigValidity" SG_ 902 SmrtIMS_ExitSta 0;
BA_REL_ "GenSigTimeoutTime" BU_SG_REL_ CGW_CCU SG_ 902 SmrtIMS_ExitSta 1500;
BA_ "NetworkRequest" SG_ 902 SmrtIMS_ExitSta 0;
BA_ "NetworkRequestHoldingTime" SG_ 902 SmrtIMS_ExitSta 5000;
BA_ "Version" SG_ 902 SmrtIMS_ExitSta "17.11.00";
BA_ "Description" SG_ 902 PSM_DrvStRlxTiltUpDis "This signal is used to display the seat movement to AVN";
BA_ "GenSigSendType" SG_ 902 PSM_DrvStRlxTiltUpDis 4;
BA_ "UserSigValidity" SG_ 902 PSM_DrvStRlxTiltUpDis 1;
BA_REL_ "GenSigTimeoutTime" BU_SG_REL_ CGW_CCU SG_ 902 PSM_DrvStRlxTiltUpDis 1500;
BA_ "NetworkRequest" SG_ 902 PSM_DrvStRlxTiltUpDis 0;
BA_ "NetworkRequestHoldingTime" SG_ 902 PSM_DrvStRlxTiltUpDis 5000;
BA_ "Version" SG_ 902 PSM_DrvStRlxTiltUpDis "20.01.02";
BA_ "Description" SG_ 902 PSM_DrvStRlxTiltDnDis "This signal is used to display the seat movement to AVN";
BA_ "GenSigSendType" SG_ 902 PSM_DrvStRlxTiltDnDis 4;
BA_ "UserSigValidity" SG_ 902 PSM_DrvStRlxTiltDnDis 1;
BA_REL_ "GenSigTimeoutTime" BU_SG_REL_ CGW_CCU SG_ 902 PSM_DrvStRlxTiltDnDis 1500;
BA_ "NetworkRequest" SG_ 902 PSM_DrvStRlxTiltDnDis 0;
BA_ "NetworkRequestHoldingTime" SG_ 902 PSM_DrvStRlxTiltDnDis 5000;
BA_ "Version" SG_ 902 PSM_DrvStRlxTiltDnDis "20.01.02";
BA_ "Description" SG_ 902 PSM_DrvStLegUpDis "This signal is used to display the seat movement to AVN";
BA_ "GenSigSendType" SG_ 902 PSM_DrvStLegUpDis 4;
BA_ "UserSigValidity" SG_ 902 PSM_DrvStLegUpDis 1;
BA_REL_ "GenSigTimeoutTime" BU_SG_REL_ CGW_CCU SG_ 902 PSM_DrvStLegUpDis 1500;
BA_ "NetworkRequest" SG_ 902 PSM_DrvStLegUpDis 0;
BA_ "NetworkRequestHoldingTime" SG_ 902 PSM_DrvStLegUpDis 5000;
BA_ "Version" SG_ 902 PSM_DrvStLegUpDis "20.01.02";
BA_ "Description" SG_ 902 PSM_DrvStLegDnDis "This signal is used to display the seat movement to AVN";
BA_ "GenSigSendType" SG_ 902 PSM_DrvStLegDnDis 4;
BA_ "UserSigValidity" SG_ 902 PSM_DrvStLegDnDis 1;
BA_REL_ "GenSigTimeoutTime" BU_SG_REL_ CGW_CCU SG_ 902 PSM_DrvStLegDnDis 1500;
BA_ "NetworkRequest" SG_ 902 PSM_DrvStLegDnDis 0;
BA_ "NetworkRequestHoldingTime" SG_ 902 PSM_DrvStLegDnDis 5000;
BA_ "Version" SG_ 902 PSM_DrvStLegDnDis "20.01.02";
BA_ "Description" SG_ 902 Drv_2ndStAutoRlxEnable "¿îÀü¼® ½ÃÆ® À§Ä¡¿¡ µû¸¥ ÈÄ¼® ¿ÀÅä ¸±·º¼Ç ÀÛµ¿ °¡´É ¿©ºÎ";
BA_ "GenSigSendType" SG_ 902 Drv_2ndStAutoRlxEnable 4;
BA_ "TimeoutValue" SG_ 902 Drv_2ndStAutoRlxEnable "0x0";
BA_ "UserSigValidity" SG_ 902 Drv_2ndStAutoRlxEnable 0;
BA_REL_ "GenSigTimeoutTime" BU_SG_REL_ RLPSU SG_ 902 Drv_2ndStAutoRlxEnable 1500;
BA_REL_ "GenSigTimeoutTime" BU_SG_REL_ RRPSU SG_ 902 Drv_2ndStAutoRlxEnable 1500;
BA_ "NetworkRequest" SG_ 902 Drv_2ndStAutoRlxEnable 0;
BA_ "NetworkRequestHoldingTime" SG_ 902 Drv_2ndStAutoRlxEnable 5000;
BA_ "Version" SG_ 902 Drv_2ndStAutoRlxEnable "21.06.10";
BA_ "Description" SG_ 902 Drv_AutoRlxSta "¿îÀü¼® ¿ÀÅä ¸±·º¼Ç µ¿ÀÛ Á¤º¸";
BA_ "GenSigSendType" SG_ 902 Drv_AutoRlxSta 4;
BA_ "TimeoutValue" SG_ 902 Drv_AutoRlxSta "0x0";
BA_ "UserSigValidity" SG_ 902 Drv_AutoRlxSta 0;
BA_REL_ "GenSigTimeoutTime" BU_SG_REL_ RLPSU SG_ 902 Drv_AutoRlxSta 1500;
BA_REL_ "GenSigTimeoutTime" BU_SG_REL_ RRPSU SG_ 902 Drv_AutoRlxSta 1500;
BA_REL_ "GenSigTimeoutTime" BU_SG_REL_ CGW_CCU SG_ 902 Drv_AutoRlxSta 1500;
BA_ "NetworkRequest" SG_ 902 Drv_AutoRlxSta 0;
BA_ "NetworkRequestHoldingTime" SG_ 902 Drv_AutoRlxSta 5000;
BA_ "Version" SG_ 902 Drv_AutoRlxSta "21.06.10";
BA_ "Description" SG_ 902 Drv_AutoReturnSta "Driver Seat Auto Return Status Information";
BA_ "GenSigSendType" SG_ 902 Drv_AutoReturnSta 4;
BA_ "TimeoutValue" SG_ 902 Drv_AutoReturnSta "0x0";
BA_ "UserSigValidity" SG_ 902 Drv_AutoReturnSta 0;
BA_REL_ "GenSigTimeoutTime" BU_SG_REL_ CGW_CCU SG_ 902 Drv_AutoReturnSta 1500;
BA_ "NetworkRequest" SG_ 902 Drv_AutoReturnSta 0;
BA_ "NetworkRequestHoldingTime" SG_ 902 Drv_AutoReturnSta 5000;
BA_ "Version" SG_ 902 Drv_AutoReturnSta "21.11.04";
BA_ "Description" SG_ 902 PSM_IMSOptTyp "-(Old)C_IMSOption";
BA_ "GenSigSendType" SG_ 902 PSM_IMSOptTyp 4;
BA_ "UserSigValidity" SG_ 902 PSM_IMSOptTyp 0;
BA_REL_ "GenSigTimeoutTime" BU_SG_REL_ CGW_CCU SG_ 902 PSM_IMSOptTyp 1500;
BA_ "NetworkRequest" SG_ 902 PSM_IMSOptTyp 0;
BA_ "NetworkRequestHoldingTime" SG_ 902 PSM_IMSOptTyp 5000;
BA_ "Version" SG_ 902 PSM_IMSOptTyp "17.11.00";
BA_ "GenMsgSendType" BO_ 903 0;
BA_ "Description" SG_ 903 PSM_DrvStSldFwdDis "This signal is used to display the seat movement to AVN";
BA_ "GenSigSendType" SG_ 903 PSM_DrvStSldFwdDis 4;
BA_ "UserSigValidity" SG_ 903 PSM_DrvStSldFwdDis 1;
BA_REL_ "GenSigTimeoutTime" BU_SG_REL_ CGW_CCU SG_ 903 PSM_DrvStSldFwdDis 1500;
BA_ "NetworkRequest" SG_ 903 PSM_DrvStSldFwdDis 0;
BA_ "NetworkRequestHoldingTime" SG_ 903 PSM_DrvStSldFwdDis 5000;
BA_ "Version" SG_ 903 PSM_DrvStSldFwdDis "17.11.00";
BA_ "Description" SG_ 903 PSM_DrvStTiltDnDis "This signal is used to display the seat movement to AVN";
BA_ "GenSigSendType" SG_ 903 PSM_DrvStTiltDnDis 4;
BA_ "UserSigValidity" SG_ 903 PSM_DrvStTiltDnDis 1;
BA_REL_ "GenSigTimeoutTime" BU_SG_REL_ CGW_CCU SG_ 903 PSM_DrvStTiltDnDis 1500;
BA_ "NetworkRequest" SG_ 903 PSM_DrvStTiltDnDis 0;
BA_ "NetworkRequestHoldingTime" SG_ 903 PSM_DrvStTiltDnDis 5000;
BA_ "Version" SG_ 903 PSM_DrvStTiltDnDis "17.11.00";
BA_ "Description" SG_ 903 PSM_DrvStHghtUpDis "This signal is used to display the seat movement to AVN";
BA_ "GenSigSendType" SG_ 903 PSM_DrvStHghtUpDis 4;
BA_ "UserSigValidity" SG_ 903 PSM_DrvStHghtUpDis 1;
BA_REL_ "GenSigTimeoutTime" BU_SG_REL_ CGW_CCU SG_ 903 PSM_DrvStHghtUpDis 1500;
BA_ "NetworkRequest" SG_ 903 PSM_DrvStHghtUpDis 0;
BA_ "NetworkRequestHoldingTime" SG_ 903 PSM_DrvStHghtUpDis 5000;
BA_ "Version" SG_ 903 PSM_DrvStHghtUpDis "17.11.00";
BA_ "Description" SG_ 903 PSM_DrvStHghtDnDis "This signal is used to display the seat movement to AVN";
BA_ "GenSigSendType" SG_ 903 PSM_DrvStHghtDnDis 4;
BA_ "UserSigValidity" SG_ 903 PSM_DrvStHghtDnDis 1;
BA_REL_ "GenSigTimeoutTime" BU_SG_REL_ CGW_CCU SG_ 903 PSM_DrvStHghtDnDis 1500;
BA_ "NetworkRequest" SG_ 903 PSM_DrvStHghtDnDis 0;
BA_ "NetworkRequestHoldingTime" SG_ 903 PSM_DrvStHghtDnDis 5000;
BA_ "Version" SG_ 903 PSM_DrvStHghtDnDis "17.11.00";
BA_ "Description" SG_ 903 PSM_DrvStCushExtBckwdDis "This signal is used to display the seat movement to AVN";
BA_ "GenSigSendType" SG_ 903 PSM_DrvStCushExtBckwdDis 4;
BA_ "UserSigValidity" SG_ 903 PSM_DrvStCushExtBckwdDis 1;
BA_REL_ "GenSigTimeoutTime" BU_SG_REL_ CGW_CCU SG_ 903 PSM_DrvStCushExtBckwdDis 1500;
BA_ "NetworkRequest" SG_ 903 PSM_DrvStCushExtBckwdDis 0;
BA_ "NetworkRequestHoldingTime" SG_ 903 PSM_DrvStCushExtBckwdDis 5000;
BA_ "Version" SG_ 903 PSM_DrvStCushExtBckwdDis "17.11.00";
BA_ "Description" SG_ 903 PSM_DrvStCushExtFwdDis "This signal is used to display the seat movement to AVN";
BA_ "GenSigSendType" SG_ 903 PSM_DrvStCushExtFwdDis 4;
BA_ "UserSigValidity" SG_ 903 PSM_DrvStCushExtFwdDis 1;
BA_REL_ "GenSigTimeoutTime" BU_SG_REL_ CGW_CCU SG_ 903 PSM_DrvStCushExtFwdDis 1500;
BA_ "NetworkRequest" SG_ 903 PSM_DrvStCushExtFwdDis 0;
BA_ "NetworkRequestHoldingTime" SG_ 903 PSM_DrvStCushExtFwdDis 5000;
BA_ "Version" SG_ 903 PSM_DrvStCushExtFwdDis "17.11.00";
BA_ "Description" SG_ 903 PSM_DrvStSldBckwdDis "This signal is used to display the seat movement to AVN";
BA_ "GenSigSendType" SG_ 903 PSM_DrvStSldBckwdDis 4;
BA_ "UserSigValidity" SG_ 903 PSM_DrvStSldBckwdDis 1;
BA_REL_ "GenSigTimeoutTime" BU_SG_REL_ CGW_CCU SG_ 903 PSM_DrvStSldBckwdDis 1500;
BA_ "NetworkRequest" SG_ 903 PSM_DrvStSldBckwdDis 0;
BA_ "NetworkRequestHoldingTime" SG_ 903 PSM_DrvStSldBckwdDis 5000;
BA_ "Version" SG_ 903 PSM_DrvStSldBckwdDis "17.11.00";
BA_ "Description" SG_ 903 PSM_DrvStHdRstUpDis "This signal is used to display the seat movement to AVN";
BA_ "GenSigSendType" SG_ 903 PSM_DrvStHdRstUpDis 4;
BA_ "UserSigValidity" SG_ 903 PSM_DrvStHdRstUpDis 1;
BA_REL_ "GenSigTimeoutTime" BU_SG_REL_ CGW_CCU SG_ 903 PSM_DrvStHdRstUpDis 1500;
BA_ "NetworkRequest" SG_ 903 PSM_DrvStHdRstUpDis 0;
BA_ "NetworkRequestHoldingTime" SG_ 903 PSM_DrvStHdRstUpDis 5000;
BA_ "Version" SG_ 903 PSM_DrvStHdRstUpDis "20.07.05";
BA_ "Description" SG_ 903 PSM_DrvStHdRstDnDis "This signal is used to display the seat movement to AVN";
BA_ "GenSigSendType" SG_ 903 PSM_DrvStHdRstDnDis 4;
BA_ "UserSigValidity" SG_ 903 PSM_DrvStHdRstDnDis 1;
BA_REL_ "GenSigTimeoutTime" BU_SG_REL_ CGW_CCU SG_ 903 PSM_DrvStHdRstDnDis 1500;
BA_ "NetworkRequest" SG_ 903 PSM_DrvStHdRstDnDis 0;
BA_ "NetworkRequestHoldingTime" SG_ 903 PSM_DrvStHdRstDnDis 5000;
BA_ "Version" SG_ 903 PSM_DrvStHdRstDnDis "17.11.00";
BA_ "Description" SG_ 903 PSM_DrvStHdRstFwdDis "This signal is used to display the seat movement to AVN";
BA_ "GenSigSendType" SG_ 903 PSM_DrvStHdRstFwdDis 4;
BA_ "UserSigValidity" SG_ 903 PSM_DrvStHdRstFwdDis 1;
BA_REL_ "GenSigTimeoutTime" BU_SG_REL_ CGW_CCU SG_ 903 PSM_DrvStHdRstFwdDis 1500;
BA_ "NetworkRequest" SG_ 903 PSM_DrvStHdRstFwdDis 0;
BA_ "NetworkRequestHoldingTime" SG_ 903 PSM_DrvStHdRstFwdDis 5000;
BA_ "Version" SG_ 903 PSM_DrvStHdRstFwdDis "17.11.00";
BA_ "Description" SG_ 903 PSM_DrvStHdRstBckwdDis "This signal is used to display the seat movement to AVN";
BA_ "GenSigSendType" SG_ 903 PSM_DrvStHdRstBckwdDis 4;
BA_ "UserSigValidity" SG_ 903 PSM_DrvStHdRstBckwdDis 1;
BA_REL_ "GenSigTimeoutTime" BU_SG_REL_ CGW_CCU SG_ 903 PSM_DrvStHdRstBckwdDis 1500;
BA_ "NetworkRequest" SG_ 903 PSM_DrvStHdRstBckwdDis 0;
BA_ "NetworkRequestHoldingTime" SG_ 903 PSM_DrvStHdRstBckwdDis 5000;
BA_ "Version" SG_ 903 PSM_DrvStHdRstBckwdDis "17.11.00";
BA_ "Description" SG_ 903 PSM_DrvStLmbrDefDis "This signal is used to display the seat movement to AVN";
BA_ "GenSigSendType" SG_ 903 PSM_DrvStLmbrDefDis 4;
BA_ "UserSigValidity" SG_ 903 PSM_DrvStLmbrDefDis 1;
BA_REL_ "GenSigTimeoutTime" BU_SG_REL_ CGW_CCU SG_ 903 PSM_DrvStLmbrDefDis 1500;
BA_ "NetworkRequest" SG_ 903 PSM_DrvStLmbrDefDis 0;
BA_ "NetworkRequestHoldingTime" SG_ 903 PSM_DrvStLmbrDefDis 5000;
BA_ "Version" SG_ 903 PSM_DrvStLmbrDefDis "17.11.00";
BA_ "Description" SG_ 903 PSM_DrvStLmbrLoDis "This signal is used to display the seat movement to AVN";
BA_ "GenSigSendType" SG_ 903 PSM_DrvStLmbrLoDis 4;
BA_ "UserSigValidity" SG_ 903 PSM_DrvStLmbrLoDis 1;
BA_REL_ "GenSigTimeoutTime" BU_SG_REL_ CGW_CCU SG_ 903 PSM_DrvStLmbrLoDis 1500;
BA_ "NetworkRequest" SG_ 903 PSM_DrvStLmbrLoDis 0;
BA_ "NetworkRequestHoldingTime" SG_ 903 PSM_DrvStLmbrLoDis 5000;
BA_ "Version" SG_ 903 PSM_DrvStLmbrLoDis "17.11.00";
BA_ "Description" SG_ 903 PSM_DrvStLmbrMdlDis "This signal is used to display the seat movement to AVN";
BA_ "GenSigSendType" SG_ 903 PSM_DrvStLmbrMdlDis 4;
BA_ "UserSigValidity" SG_ 903 PSM_DrvStLmbrMdlDis 1;
BA_REL_ "GenSigTimeoutTime" BU_SG_REL_ CGW_CCU SG_ 903 PSM_DrvStLmbrMdlDis 1500;
BA_ "NetworkRequest" SG_ 903 PSM_DrvStLmbrMdlDis 0;
BA_ "NetworkRequestHoldingTime" SG_ 903 PSM_DrvStLmbrMdlDis 5000;
BA_ "Version" SG_ 903 PSM_DrvStLmbrMdlDis "17.11.00";
BA_ "Description" SG_ 903 PSM_DrvStLmbrUpDis "This signal is used to display the seat movement to AVN";
BA_ "GenSigSendType" SG_ 903 PSM_DrvStLmbrUpDis 4;
BA_ "UserSigValidity" SG_ 903 PSM_DrvStLmbrUpDis 1;
BA_REL_ "GenSigTimeoutTime" BU_SG_REL_ CGW_CCU SG_ 903 PSM_DrvStLmbrUpDis 1500;
BA_ "NetworkRequest" SG_ 903 PSM_DrvStLmbrUpDis 0;
BA_ "NetworkRequestHoldingTime" SG_ 903 PSM_DrvStLmbrUpDis 5000;
BA_ "Version" SG_ 903 PSM_DrvStLmbrUpDis "17.11.00";
BA_ "Description" SG_ 903 PSM_DrvStReclneFwdDis "This signal is used to display the seat movement to AVN";
BA_ "GenSigSendType" SG_ 903 PSM_DrvStReclneFwdDis 4;
BA_ "UserSigValidity" SG_ 903 PSM_DrvStReclneFwdDis 1;
BA_REL_ "GenSigTimeoutTime" BU_SG_REL_ CGW_CCU SG_ 903 PSM_DrvStReclneFwdDis 1500;
BA_ "NetworkRequest" SG_ 903 PSM_DrvStReclneFwdDis 0;
BA_ "NetworkRequestHoldingTime" SG_ 903 PSM_DrvStReclneFwdDis 5000;
BA_ "Version" SG_ 903 PSM_DrvStReclneFwdDis "17.11.00";
BA_ "Description" SG_ 903 PSM_DrvStBlstrDefDis "This signal is used to display the seat movement to AVN";
BA_ "GenSigSendType" SG_ 903 PSM_DrvStBlstrDefDis 4;
BA_ "UserSigValidity" SG_ 903 PSM_DrvStBlstrDefDis 1;
BA_REL_ "GenSigTimeoutTime" BU_SG_REL_ CGW_CCU SG_ 903 PSM_DrvStBlstrDefDis 1500;
BA_ "NetworkRequest" SG_ 903 PSM_DrvStBlstrDefDis 0;
BA_ "NetworkRequestHoldingTime" SG_ 903 PSM_DrvStBlstrDefDis 5000;
BA_ "Version" SG_ 903 PSM_DrvStBlstrDefDis "17.11.00";
BA_ "Description" SG_ 903 PSM_DrvStBlstrInfDis "This signal is used to display the seat movement to AVN";
BA_ "GenSigSendType" SG_ 903 PSM_DrvStBlstrInfDis 4;
BA_ "UserSigValidity" SG_ 903 PSM_DrvStBlstrInfDis 1;
BA_REL_ "GenSigTimeoutTime" BU_SG_REL_ CGW_CCU SG_ 903 PSM_DrvStBlstrInfDis 1500;
BA_ "NetworkRequest" SG_ 903 PSM_DrvStBlstrInfDis 0;
BA_ "NetworkRequestHoldingTime" SG_ 903 PSM_DrvStBlstrInfDis 5000;
BA_ "Version" SG_ 903 PSM_DrvStBlstrInfDis "17.11.00";
BA_ "Description" SG_ 903 PSM_DrvStReclneBckwdDis "This signal is used to display the seat movement to AVN";
BA_ "GenSigSendType" SG_ 903 PSM_DrvStReclneBckwdDis 4;
BA_ "UserSigValidity" SG_ 903 PSM_DrvStReclneBckwdDis 1;
BA_REL_ "GenSigTimeoutTime" BU_SG_REL_ CGW_CCU SG_ 903 PSM_DrvStReclneBckwdDis 1500;
BA_ "NetworkRequest" SG_ 903 PSM_DrvStReclneBckwdDis 0;
BA_ "NetworkRequestHoldingTime" SG_ 903 PSM_DrvStReclneBckwdDis 5000;
BA_ "Version" SG_ 903 PSM_DrvStReclneBckwdDis "17.11.00";
BA_ "Description" SG_ 903 PSM_DrvStTiltUpDis "This signal is used to display the seat movement to AVN";
BA_ "GenSigSendType" SG_ 903 PSM_DrvStTiltUpDis 4;
BA_ "UserSigValidity" SG_ 903 PSM_DrvStTiltUpDis 1;
BA_REL_ "GenSigTimeoutTime" BU_SG_REL_ CGW_CCU SG_ 903 PSM_DrvStTiltUpDis 1500;
BA_ "NetworkRequest" SG_ 903 PSM_DrvStTiltUpDis 0;
BA_ "NetworkRequestHoldingTime" SG_ 903 PSM_DrvStTiltUpDis 5000;
BA_ "Version" SG_ 903 PSM_DrvStTiltUpDis "17.11.00";
BA_ "GenMsgSendType" BO_ 904 0;
BA_ "Description" SG_ 904 PSM_DrvReclinePosition "DRIVER SEAT RECLINE POSITION (UNIT: ¢ª)";
BA_ "GenSigSendType" SG_ 904 PSM_DrvReclinePosition 4;
BA_ "UserSigValidity" SG_ 904 PSM_DrvReclinePosition 0;
BA_REL_ "GenSigTimeoutTime" BU_SG_REL_ CGW_CCU SG_ 904 PSM_DrvReclinePosition 1500;
BA_ "NetworkRequest" SG_ 904 PSM_DrvReclinePosition 0;
BA_ "NetworkRequestHoldingTime" SG_ 904 PSM_DrvReclinePosition 5000;
BA_ "Version" SG_ 904 PSM_DrvReclinePosition "19.08.06";
BA_ "Description" SG_ 904 PSM_EsyAcsGetOffSta "-(Old)C_EasyAccessGetOff";
BA_ "GenSigSendType" SG_ 904 PSM_EsyAcsGetOffSta 4;
BA_ "UserSigValidity" SG_ 904 PSM_EsyAcsGetOffSta 0;
BA_REL_ "GenSigTimeoutTime" BU_SG_REL_ DLBCU SG_ 904 PSM_EsyAcsGetOffSta 1500;
BA_REL_ "GenSigTimeoutTime" BU_SG_REL_ DSAU SG_ 904 PSM_EsyAcsGetOffSta 1500;
BA_ "NetworkRequest" SG_ 904 PSM_EsyAcsGetOffSta 0;
BA_ "NetworkRequestHoldingTime" SG_ 904 PSM_EsyAcsGetOffSta 5000;
BA_ "Version" SG_ 904 PSM_EsyAcsGetOffSta "17.11.00";
BA_ "Description" SG_ 904 PSM_EsyAcsStpSta "-(Old)C_EasyAccessStop";
BA_ "GenSigSendType" SG_ 904 PSM_EsyAcsStpSta 4;
BA_ "UserSigValidity" SG_ 904 PSM_EsyAcsStpSta 0;
BA_REL_ "GenSigTimeoutTime" BU_SG_REL_ DLBCU SG_ 904 PSM_EsyAcsStpSta 1500;
BA_REL_ "GenSigTimeoutTime" BU_SG_REL_ DSAU SG_ 904 PSM_EsyAcsStpSta 1500;
BA_ "NetworkRequest" SG_ 904 PSM_EsyAcsStpSta 0;
BA_ "NetworkRequestHoldingTime" SG_ 904 PSM_EsyAcsStpSta 5000;
BA_ "Version" SG_ 904 PSM_EsyAcsStpSta "17.11.00";
BA_ "Description" SG_ 904 PSM_SWVerMajor1 "Indicate the PSM software version as follows:

- The software version is displayed in three digits.

- The Major and Minor digits are separated by '.'

- Signal values are transmitted to ASCII codes.



¡Ø Example

PSM_SWVerMajor1 : 0x41 (HEX) -> ASCII CODE : 'A' 

PSM_SWVerMinor1 : 0x30 (HEX) -> ASCII CODE : '0'

PSM_SWVerMinor2 : 0x33 (HEX) -> ASCII CODE : '3'

=> PSM S/W Ver is displayed 'A.03'";
BA_ "GenSigSendType" SG_ 904 PSM_SWVerMajor1 4;
BA_ "UserSigValidity" SG_ 904 PSM_SWVerMajor1 0;
BA_REL_ "GenSigTimeoutTime" BU_SG_REL_ CGW_CCU SG_ 904 PSM_SWVerMajor1 1500;
BA_ "Version" SG_ 904 PSM_SWVerMajor1 "20.12.04";
BA_ "Description" SG_ 904 PSM_SWVerMinor1 "Indicate the PSM software version as follows:

- The software version is displayed in three digits.

- The Major and Minor digits are separated by '.'

- Signal values are transmitted to ASCII codes.



¡Ø Example

PSM_SWVerMajor1 : 0x41 (HEX) -> ASCII CODE : 'A' 

PSM_SWVerMinor1 : 0x30 (HEX) -> ASCII CODE : '0'

PSM_SWVerMinor2 : 0x33 (HEX) -> ASCII CODE : '3'

=> PSM S/W Ver is displayed 'A.03'";
BA_ "GenSigSendType" SG_ 904 PSM_SWVerMinor1 4;
BA_ "UserSigValidity" SG_ 904 PSM_SWVerMinor1 0;
BA_REL_ "GenSigTimeoutTime" BU_SG_REL_ CGW_CCU SG_ 904 PSM_SWVerMinor1 1500;
BA_ "Version" SG_ 904 PSM_SWVerMinor1 "18.10.06";
BA_ "Description" SG_ 904 PSM_SWVerMinor2 "Indicate the PSM software version as follows:

- The software version is displayed in three digits.

- The Major and Minor digits are separated by '.'

- Signal values are transmitted to ASCII codes.



¡Ø Example

PSM_SWVerMajor1 : 0x41 (HEX) -> ASCII CODE : 'A' 

PSM_SWVerMinor1 : 0x30 (HEX) -> ASCII CODE : '0'

PSM_SWVerMinor2 : 0x33 (HEX) -> ASCII CODE : '3'

=> PSM S/W Ver is displayed 'A.03'";
BA_ "GenSigSendType" SG_ 904 PSM_SWVerMinor2 4;
BA_ "UserSigValidity" SG_ 904 PSM_SWVerMinor2 0;
BA_REL_ "GenSigTimeoutTime" BU_SG_REL_ CGW_CCU SG_ 904 PSM_SWVerMinor2 1500;
BA_ "Version" SG_ 904 PSM_SWVerMinor2 "18.10.06";
BA_ "Description" SG_ 904 PSM_DrvHeightPosition "DRIVER SEAT HEIGHT POSITION (UNIT: mm)";
BA_ "GenSigSendType" SG_ 904 PSM_DrvHeightPosition 4;
BA_ "UserSigValidity" SG_ 904 PSM_DrvHeightPosition 0;
BA_REL_ "GenSigTimeoutTime" BU_SG_REL_ CGW_CCU SG_ 904 PSM_DrvHeightPosition 1500;
BA_ "NetworkRequest" SG_ 904 PSM_DrvHeightPosition 0;
BA_ "NetworkRequestHoldingTime" SG_ 904 PSM_DrvHeightPosition 5000;
BA_ "Version" SG_ 904 PSM_DrvHeightPosition "20.03.03";
BA_ "Description" SG_ 904 PSM_DrvSlidePosition "DRIVER SEAT SLIDE POSITION (UNIT: mm)";
BA_ "GenSigSendType" SG_ 904 PSM_DrvSlidePosition 4;
BA_ "UserSigValidity" SG_ 904 PSM_DrvSlidePosition 0;
BA_REL_ "GenSigTimeoutTime" BU_SG_REL_ CGW_CCU SG_ 904 PSM_DrvSlidePosition 1500;
BA_ "NetworkRequest" SG_ 904 PSM_DrvSlidePosition 0;
BA_ "NetworkRequestHoldingTime" SG_ 904 PSM_DrvSlidePosition 5000;
BA_ "Version" SG_ 904 PSM_DrvSlidePosition "19.08.06";
BA_ "Description" SG_ 904 PSM_EsyAcsGetOnSta "-(Old)C_EasyAccessGetOn";
BA_ "GenSigSendType" SG_ 904 PSM_EsyAcsGetOnSta 4;
BA_ "UserSigValidity" SG_ 904 PSM_EsyAcsGetOnSta 0;
BA_REL_ "GenSigTimeoutTime" BU_SG_REL_ DLBCU SG_ 904 PSM_EsyAcsGetOnSta 1500;
BA_REL_ "GenSigTimeoutTime" BU_SG_REL_ DSAU SG_ 904 PSM_EsyAcsGetOnSta 1500;
BA_ "NetworkRequest" SG_ 904 PSM_EsyAcsGetOnSta 0;
BA_ "NetworkRequestHoldingTime" SG_ 904 PSM_EsyAcsGetOnSta 5000;
BA_ "Version" SG_ 904 PSM_EsyAcsGetOnSta "17.11.00";
BA_ "GenMsgSendType" BO_ 934 0;
BA_ "Description" SG_ 934 PTGM_Crc1Val "The data area for CRC calculation is based on the data length (DLC) of the message DB.

The CRC shall be calculated over the entire data block (excluding the CRC bytes) including the user data, alive counter and Data ID 

 

- CRC Polynomial (0x1D) , Initial Value : 0x00, XOR value : 0xFF, Data ID Mode : Both, Data ID : Message ID + 0xF800 

- The initial value is for CRC calculation and the message should be sent with the calculated result value. 

The mathematical expression to 8 bit CRC polynomial is given here. G(x) = x8 + x4 + x3 + x2 + 1";
BA_ "GenSigSendType" SG_ 934 PTGM_Crc1Val 4;
BA_ "GenSigStartValue" SG_ 934 PTGM_Crc1Val 255;
BA_ "UserSigValidity" SG_ 934 PTGM_Crc1Val 0;
BA_ "Version" SG_ 934 PTGM_Crc1Val "18.11.08";
BA_ "Description" SG_ 934 PTGM_AlvCnt1Val "For the first transmission request for a data element the counter shall be initialized with 0 and shall be incremented by 1

for every subsequent send request. When the counter reaches the maximum value(0xE), then it shall restart with 0 for the next send request";
BA_ "GenSigSendType" SG_ 934 PTGM_AlvCnt1Val 4;
BA_ "UserSigValidity" SG_ 934 PTGM_AlvCnt1Val 0;
BA_ "Version" SG_ 934 PTGM_AlvCnt1Val "18.11.08";
BA_ "Description" SG_ 934 PTGM_HazardSta "-(Old)C_PTHazard";
BA_ "GenSigSendType" SG_ 934 PTGM_HazardSta 4;
BA_ "GenSigStartValue" SG_ 934 PTGM_HazardSta 2;
BA_ "UserSigValidity" SG_ 934 PTGM_HazardSta 0;
BA_ "NetworkRequest" SG_ 934 PTGM_HazardSta 0;
BA_ "NetworkRequestHoldingTime" SG_ 934 PTGM_HazardSta 5000;
BA_ "Version" SG_ 934 PTGM_HazardSta "21.07.05";
BA_ "Description" SG_ 934 PTGM_ModSta "PTGM Moudule Status";
BA_ "GenSigSendType" SG_ 934 PTGM_ModSta 4;
BA_ "UserSigValidity" SG_ 934 PTGM_ModSta 0;
BA_ "NetworkRequest" SG_ 934 PTGM_ModSta 0;
BA_ "NetworkRequestHoldingTime" SG_ 934 PTGM_ModSta 5000;
BA_ "Version" SG_ 934 PTGM_ModSta "21.07.05";
BA_ "Description" SG_ 934 PTGM_MovSta "PTGM Status (stop or moving)";
BA_ "GenSigSendType" SG_ 934 PTGM_MovSta 4;
BA_ "UserSigValidity" SG_ 934 PTGM_MovSta 0;
BA_ "NetworkRequest" SG_ 934 PTGM_MovSta 0;
BA_ "NetworkRequestHoldingTime" SG_ 934 PTGM_MovSta 5000;
BA_ "Version" SG_ 934 PTGM_MovSta "21.07.05";
BA_ "GenSigSendType" SG_ 934 PTGM_OptTyp 4;
BA_ "UserSigValidity" SG_ 934 PTGM_OptTyp 0;
BA_ "NetworkRequest" SG_ 934 PTGM_OptTyp 0;
BA_ "NetworkRequestHoldingTime" SG_ 934 PTGM_OptTyp 5000;
BA_ "Version" SG_ 934 PTGM_OptTyp "21.07.05";
BA_ "GenSigSendType" SG_ 934 PTGM_ReleaseRlySta 4;
BA_ "UserSigValidity" SG_ 934 PTGM_ReleaseRlySta 0;
BA_REL_ "GenSigTimeoutTime" BU_SG_REL_ APSU SG_ 934 PTGM_ReleaseRlySta 1500;
BA_REL_ "GenSigTimeoutTime" BU_SG_REL_ PFSU SG_ 934 PTGM_ReleaseRlySta 1500;
BA_ "NetworkRequest" SG_ 934 PTGM_ReleaseRlySta 0;
BA_ "NetworkRequestHoldingTime" SG_ 934 PTGM_ReleaseRlySta 5000;
BA_ "Version" SG_ 934 PTGM_ReleaseRlySta "21.07.05";
BA_ "Description" SG_ 934 PTGM_TrnkLkSwSta "-(Old)C_Trunk_Lock_Sw";
BA_ "GenSigSendType" SG_ 934 PTGM_TrnkLkSwSta 4;
BA_ "UserSigValidity" SG_ 934 PTGM_TrnkLkSwSta 0;
BA_ "NetworkRequest" SG_ 934 PTGM_TrnkLkSwSta 0;
BA_ "NetworkRequestHoldingTime" SG_ 934 PTGM_TrnkLkSwSta 5000;
BA_ "Version" SG_ 934 PTGM_TrnkLkSwSta "21.07.05";
BA_ "Description" SG_ 934 PTGM_UsmSetSta "PTGM USM Setting Signal";
BA_ "GenSigSendType" SG_ 934 PTGM_UsmSetSta 4;
BA_ "UserSigValidity" SG_ 934 PTGM_UsmSetSta 3;
BA_ "NetworkRequest" SG_ 934 PTGM_UsmSetSta 0;
BA_ "NetworkRequestHoldingTime" SG_ 934 PTGM_UsmSetSta 5000;
BA_ "Version" SG_ 934 PTGM_UsmSetSta "17.11.00";
BA_ "Description" SG_ 934 PTGM_HeightRValue "PTG Opening Height USM Setting Signal";
BA_ "GenSigSendType" SG_ 934 PTGM_HeightRValue 4;
BA_ "UserSigValidity" SG_ 934 PTGM_HeightRValue 0;
BA_ "NetworkRequest" SG_ 934 PTGM_HeightRValue 0;
BA_ "Version" SG_ 934 PTGM_HeightRValue "21.07.05";
BA_ "Description" SG_ 934 PTGM_OpnClsState "This signal indicates PTGM Open/Close Status";
BA_ "GenSigSendType" SG_ 934 PTGM_OpnClsState 4;
BA_ "UserSigValidity" SG_ 934 PTGM_OpnClsState 0;
BA_ "Version" SG_ 934 PTGM_OpnClsState "21.07.05";
BA_ "Description" SG_ 934 PTGM_CmdWarn "This signal indicates PTGM Warning Status";
BA_ "GenSigSendType" SG_ 934 PTGM_CmdWarn 4;
BA_ "UserSigValidity" SG_ 934 PTGM_CmdWarn 3;
BA_ "Version" SG_ 934 PTGM_CmdWarn "21.07.05";
BA_ "Description" SG_ 934 PTGM_AntiPinchSnsr "This signal indicates Anti-Pinch Sensor Applied Status";
BA_ "GenSigSendType" SG_ 934 PTGM_AntiPinchSnsr 4;
BA_ "UserSigValidity" SG_ 934 PTGM_AntiPinchSnsr 0;
BA_ "Version" SG_ 934 PTGM_AntiPinchSnsr "18.02.03";
BA_ "Description" SG_ 934 PTGM_FobSrch_Req "FOB Search Request";
BA_ "GenSigSendType" SG_ 934 PTGM_FobSrch_Req 4;
BA_ "UserSigValidity" SG_ 934 PTGM_FobSrch_Req 0;
BA_ "NetworkRequest" SG_ 934 PTGM_FobSrch_Req 0;
BA_ "NetworkRequestHoldingTime" SG_ 934 PTGM_FobSrch_Req 5000;
BA_ "Version" SG_ 934 PTGM_FobSrch_Req "19.01.11";
BA_ "Description" SG_ 934 PTGM_TlgtAwayCloseRValue "Tailgate Away Close USM On/Off Setting Signal";
BA_ "GenSigSendType" SG_ 934 PTGM_TlgtAwayCloseRValue 4;
BA_ "UserSigValidity" SG_ 934 PTGM_TlgtAwayCloseRValue 0;
BA_ "NetworkRequest" SG_ 934 PTGM_TlgtAwayCloseRValue 0;
BA_ "NetworkRequestHoldingTime" SG_ 934 PTGM_TlgtAwayCloseRValue 5000;
BA_ "Version" SG_ 934 PTGM_TlgtAwayCloseRValue "19.01.10";
BA_ "Description" SG_ 934 PTGM_TrnkTlgtOption "PTGM(Power Tail Gate Module) Option Signal";
BA_ "GenSigSendType" SG_ 934 PTGM_TrnkTlgtOption 4;
BA_ "UserSigValidity" SG_ 934 PTGM_TrnkTlgtOption 0;
BA_ "NetworkRequest" SG_ 934 PTGM_TrnkTlgtOption 0;
BA_ "NetworkRequestHoldingTime" SG_ 934 PTGM_TrnkTlgtOption 5000;
BA_ "Version" SG_ 934 PTGM_TrnkTlgtOption "19.05.00";
BA_ "Description" SG_ 934 PTGM_LatchType "This signal indicates the Tailgate/Trunk Latch Type. (Integrated / Separated)";
BA_ "GenSigSendType" SG_ 934 PTGM_LatchType 4;
BA_ "UserSigValidity" SG_ 934 PTGM_LatchType 0;
BA_ "Version" SG_ 934 PTGM_LatchType "19.07.01";
BA_ "Description" SG_ 934 PTGM_SpeedRValue "PTG Speed USM Setting Signal";
BA_ "GenSigSendType" SG_ 934 PTGM_SpeedRValue 4;
BA_ "UserSigValidity" SG_ 934 PTGM_SpeedRValue 0;
BA_ "NetworkRequest" SG_ 934 PTGM_SpeedRValue 0;
BA_ "Version" SG_ 934 PTGM_SpeedRValue "18.02.03";
BA_ "GenMsgCycleTime" BO_ 924 0;
BA_ "Description" SG_ 924 RLPSU_FailState_PopUp "2¿­ ÁÂÃø ½ÃÆ® µ¿ÀÛ ¿Ï·á ¹× ºÒ°¡ »óÈ² Á¤º¸ Ç¥½Ã¸¦ À§ÇÑ ¼Û½Å ½ÅÈ£";
BA_ "GenSigSendType" SG_ 924 RLPSU_FailState_PopUp 4;
BA_ "UserSigValidity" SG_ 924 RLPSU_FailState_PopUp 0;
BA_REL_ "GenSigTimeoutTime" BU_SG_REL_ CGW_CCU SG_ 924 RLPSU_FailState_PopUp 0;
BA_ "Version" SG_ 924 RLPSU_FailState_PopUp "21.07.06";
BA_ "Description" SG_ 924 RLPSU_Folding_State_Popup_EC "Rear LH seat Folding State information";
BA_ "GenSigSendType" SG_ 924 RLPSU_Folding_State_Popup_EC 4;
BA_ "UserSigValidity" SG_ 924 RLPSU_Folding_State_Popup_EC 0;
BA_REL_ "GenSigTimeoutTime" BU_SG_REL_ CGW_CCU SG_ 924 RLPSU_Folding_State_Popup_EC 0;
BA_ "Version" SG_ 924 RLPSU_Folding_State_Popup_EC "21.07.06";
BA_ "Description" SG_ 924 RLPSU_Relax_State_Popup_EC "Rear LH seat Relax State information";
BA_ "GenSigSendType" SG_ 924 RLPSU_Relax_State_Popup_EC 4;
BA_ "UserSigValidity" SG_ 924 RLPSU_Relax_State_Popup_EC 0;
BA_REL_ "GenSigTimeoutTime" BU_SG_REL_ CGW_CCU SG_ 924 RLPSU_Relax_State_Popup_EC 0;
BA_ "Version" SG_ 924 RLPSU_Relax_State_Popup_EC "21.07.06";
BA_ "Description" SG_ 924 RLPSU_Reclining_State_Popup "RLPSU (2¿­ ÁÂÃø ÆÄ¿ö ¸®Å¬¶óÀÌ´×) µ¿ÀÛ ºÒ°¡ »óÅÂÀÇ OSD Ç¥½Ã";
BA_ "GenSigSendType" SG_ 924 RLPSU_Reclining_State_Popup 4;
BA_ "UserSigValidity" SG_ 924 RLPSU_Reclining_State_Popup 0;
BA_ "Version" SG_ 924 RLPSU_Reclining_State_Popup "21.07.06";
BA_ "Description" SG_ 924 RL_AstStStdPosMovReq "ÈÄ¼® LH ½ÃÆ® µ¿ÀÛ¿¡ µû¸¥ µ¿½Â¼® ÀÌµ¿ ¿äÃ» ½ÅÈ£";
BA_ "GenSigSendType" SG_ 924 RL_AstStStdPosMovReq 4;
BA_ "UserSigValidity" SG_ 924 RL_AstStStdPosMovReq 0;
BA_REL_ "GenSigTimeoutTime" BU_SG_REL_ APSU SG_ 924 RL_AstStStdPosMovReq 0;
BA_ "NetworkRequest" SG_ 924 RL_AstStStdPosMovReq 0;
BA_ "NetworkRequestHoldingTime" SG_ 924 RL_AstStStdPosMovReq 5000;
BA_ "Version" SG_ 924 RL_AstStStdPosMovReq "21.06.10";
BA_ "GenMsgCycleTime" BO_ 922 0;
BA_ "Description" SG_ 922 RRPSU_FailState_PopUp "2¿­ ¿ìÃø½ÃÆ® µ¿ÀÛ¿Ï·á ¹× ºÒ°¡ »óÈ² Á¤º¸ Ç¥½Ã¸¦ À§ÇÑ ¼Û½Å ½ÅÈ£";
BA_ "GenSigSendType" SG_ 922 RRPSU_FailState_PopUp 4;
BA_ "UserSigValidity" SG_ 922 RRPSU_FailState_PopUp 0;
BA_REL_ "GenSigTimeoutTime" BU_SG_REL_ CGW_CCU SG_ 922 RRPSU_FailState_PopUp 0;
BA_ "Version" SG_ 922 RRPSU_FailState_PopUp "20.05.03";
BA_ "Description" SG_ 922 RRPSU_Folding_State_Popup_EC "Rear RH seat Folding State information";
BA_ "GenSigSendType" SG_ 922 RRPSU_Folding_State_Popup_EC 4;
BA_ "UserSigValidity" SG_ 922 RRPSU_Folding_State_Popup_EC 0;
BA_REL_ "GenSigTimeoutTime" BU_SG_REL_ CGW_CCU SG_ 922 RRPSU_Folding_State_Popup_EC 0;
BA_ "Version" SG_ 922 RRPSU_Folding_State_Popup_EC "19.06.02";
BA_ "Description" SG_ 922 RRPSU_Relax_State_Popup_EC "Rear RH seat Relax State information";
BA_ "GenSigSendType" SG_ 922 RRPSU_Relax_State_Popup_EC 4;
BA_ "UserSigValidity" SG_ 922 RRPSU_Relax_State_Popup_EC 0;
BA_REL_ "GenSigTimeoutTime" BU_SG_REL_ CGW_CCU SG_ 922 RRPSU_Relax_State_Popup_EC 0;
BA_ "Version" SG_ 922 RRPSU_Relax_State_Popup_EC "19.06.02";
BA_ "Description" SG_ 922 RRPSU_Reclining_State_Popup "RRPSU (2¿­ ¿ìÃø ÆÄ¿ö ¸®Å¬¶óÀÌ´×) µ¿ÀÛ ºÒ°¡ »óÅÂÀÇ OSD Ç¥½Ã";
BA_ "GenSigSendType" SG_ 922 RRPSU_Reclining_State_Popup 4;
BA_ "UserSigValidity" SG_ 922 RRPSU_Reclining_State_Popup 0;
BA_ "Version" SG_ 922 RRPSU_Reclining_State_Popup "19.08.05";
BA_ "Description" SG_ 922 RR_AstStStdPosMovReq "ÈÄ¼® RH ½ÃÆ® µ¿ÀÛ¿¡ µû¸¥ µ¿½Â¼® ÀÌµ¿ ¿äÃ» ½ÅÈ£";
BA_ "GenSigSendType" SG_ 922 RR_AstStStdPosMovReq 4;
BA_ "UserSigValidity" SG_ 922 RR_AstStStdPosMovReq 0;
BA_REL_ "GenSigTimeoutTime" BU_SG_REL_ APSU SG_ 922 RR_AstStStdPosMovReq 0;
BA_ "NetworkRequest" SG_ 922 RR_AstStStdPosMovReq 0;
BA_ "NetworkRequestHoldingTime" SG_ 922 RR_AstStStdPosMovReq 5000;
BA_ "Version" SG_ 922 RR_AstStStdPosMovReq "21.06.10";
BA_ "GenMsgSendType" BO_ 905 0;
BA_ "Description" SG_ 905 SBCM_RR_Crc1Val "The data area for CRC calculation is based on the data length (DLC) of the message DB.

The CRC shall be calculated over the entire data block (excluding the CRC bytes) including the user data, alive counter and Data ID 

 

- CRC Polynomial (0x1D) , Initial Value : 0x00, XOR value : 0xFF, Data ID Mode : Both, Data ID : Message ID + 0xF800 

- The initial value is for CRC calculation and the message should be sent with the calculated result value. 

The mathematical expression to 8 bit CRC polynomial is given here. G(x) = x8 + x4 + x3 + x2 + 1";
BA_ "GenSigSendType" SG_ 905 SBCM_RR_Crc1Val 4;
BA_ "GenSigStartValue" SG_ 905 SBCM_RR_Crc1Val 255;
BA_ "UserSigValidity" SG_ 905 SBCM_RR_Crc1Val 0;
BA_ "Version" SG_ 905 SBCM_RR_Crc1Val "19.07.06";
BA_ "Description" SG_ 905 RR_CrashUnlockCmd "RearRightCrashUnlockCommand";
BA_ "GenSigSendType" SG_ 905 RR_CrashUnlockCmd 4;
BA_ "UserSigValidity" SG_ 905 RR_CrashUnlockCmd 0;
BA_REL_ "GenSigTimeoutTime" BU_SG_REL_ BLTN_CAM SG_ 905 RR_CrashUnlockCmd 1500;
BA_ "NetworkRequest" SG_ 905 RR_CrashUnlockCmd 0;
BA_ "Version" SG_ 905 RR_CrashUnlockCmd "20.09.00";
BA_ "Description" SG_ 905 SBCM_RR_AlvCnt1Val "For the first transmission request for a data element the counter shall be initialized with 0 and shall be incremented by 1

for every subsequent send request. When the counter reaches the maximum value(0xE), then it shall restart with 0 for the next send request";
BA_ "GenSigSendType" SG_ 905 SBCM_RR_AlvCnt1Val 4;
BA_ "UserSigValidity" SG_ 905 SBCM_RR_AlvCnt1Val 0;
BA_ "Version" SG_ 905 SBCM_RR_AlvCnt1Val "19.07.06";
BA_ "Description" SG_ 905 Warn_RrRtDrSwSta_SBCM "Warning Rear Right Door Switch Status";
BA_ "GenSigSendType" SG_ 905 Warn_RrRtDrSwSta_SBCM 4;
BA_ "UserSigValidity" SG_ 905 Warn_RrRtDrSwSta_SBCM 0;
BA_REL_ "GenSigTimeoutTime" BU_SG_REL_ WPC SG_ 905 Warn_RrRtDrSwSta_SBCM 1500;
BA_REL_ "GenSigTimeoutTime" BU_SG_REL_ RWPC SG_ 905 Warn_RrRtDrSwSta_SBCM 1500;
BA_REL_ "GenSigTimeoutTime" BU_SG_REL_ APSU SG_ 905 Warn_RrRtDrSwSta_SBCM 1500;
BA_REL_ "GenSigTimeoutTime" BU_SG_REL_ RRPSU SG_ 905 Warn_RrRtDrSwSta_SBCM 1500;
BA_REL_ "GenSigTimeoutTime" BU_SG_REL_ ATS SG_ 905 Warn_RrRtDrSwSta_SBCM 1500;
BA_REL_ "GenSigTimeoutTime" BU_SG_REL_ BLTN_CAM SG_ 905 Warn_RrRtDrSwSta_SBCM 1500;
BA_ "NetworkRequest" SG_ 905 Warn_RrRtDrSwSta_SBCM 0;
BA_ "Version" SG_ 905 Warn_RrRtDrSwSta_SBCM "21.07.07";
BA_ "Description" SG_ 905 DoorLock_RrRtDrUnLkSta_SBCM "Rear Right Door Unlock Status";
BA_ "GenSigSendType" SG_ 905 DoorLock_RrRtDrUnLkSta_SBCM 4;
BA_ "UserSigValidity" SG_ 905 DoorLock_RrRtDrUnLkSta_SBCM 0;
BA_REL_ "GenSigTimeoutTime" BU_SG_REL_ ATS SG_ 905 DoorLock_RrRtDrUnLkSta_SBCM 1500;
BA_ "NetworkRequest" SG_ 905 DoorLock_RrRtDrUnLkSta_SBCM 0;
BA_ "Version" SG_ 905 DoorLock_RrRtDrUnLkSta_SBCM "19.07.06";
BA_ "Description" SG_ 905 RR_SEAActivated "RearRightSEAActivated";
BA_ "GenSigSendType" SG_ 905 RR_SEAActivated 4;
BA_ "UserSigValidity" SG_ 905 RR_SEAActivated 0;
BA_ "NetworkRequest" SG_ 905 RR_SEAActivated 0;
BA_ "Version" SG_ 905 RR_SEAActivated "19.07.06";
BA_ "Description" SG_ 905 RR_SEAWarn "RearRighrSEAWarning";
BA_ "GenSigSendType" SG_ 905 RR_SEAWarn 4;
BA_ "UserSigValidity" SG_ 905 RR_SEAWarn 0;
BA_ "NetworkRequest" SG_ 905 RR_SEAWarn 0;
BA_ "Version" SG_ 905 RR_SEAWarn "19.07.06";
BA_ "GenSigSendType" SG_ 905 RR_SEWWarn 4;
BA_ "UserSigValidity" SG_ 905 RR_SEWWarn 0;
BA_ "NetworkRequest" SG_ 905 RR_SEWWarn 0;
BA_ "Version" SG_ 905 RR_SEWWarn "20.09.00";
BA_ "GenSigSendType" SG_ 905 RR_ReleaseWarn 4;
BA_ "UserSigValidity" SG_ 905 RR_ReleaseWarn 0;
BA_ "NetworkRequest" SG_ 905 RR_ReleaseWarn 0;
BA_ "NetworkRequestHoldingTime" SG_ 905 RR_ReleaseWarn 5000;
BA_ "Version" SG_ 905 RR_ReleaseWarn "20.09.00";
BA_ "GenSigSendType" SG_ 905 RR_SWFailAlarm 4;
BA_ "UserSigValidity" SG_ 905 RR_SWFailAlarm 0;
BA_ "NetworkRequest" SG_ 905 RR_SWFailAlarm 0;
BA_ "NetworkRequestHoldingTime" SG_ 905 RR_SWFailAlarm 5000;
BA_ "Version" SG_ 905 RR_SWFailAlarm "20.09.00";
BA_ "GenSigSendType" SG_ 905 RR_ChildLock_ActnFlSta 4;
BA_ "UserSigValidity" SG_ 905 RR_ChildLock_ActnFlSta 0;
BA_ "NetworkRequest" SG_ 905 RR_ChildLock_ActnFlSta 0;
BA_ "NetworkRequestHoldingTime" SG_ 905 RR_ChildLock_ActnFlSta 5000;
BA_ "Version" SG_ 905 RR_ChildLock_ActnFlSta "19.11.05";
BA_ "GenSigSendType" SG_ 905 RR_MRActivationAlarm 4;
BA_ "UserSigValidity" SG_ 905 RR_MRActivationAlarm 0;
BA_ "NetworkRequest" SG_ 905 RR_MRActivationAlarm 0;
BA_ "NetworkRequestHoldingTime" SG_ 905 RR_MRActivationAlarm 5000;
BA_ "Version" SG_ 905 RR_MRActivationAlarm "19.11.05";
BA_ "GenSigSendType" SG_ 905 RR_ChildLock_Status 4;
BA_ "UserSigValidity" SG_ 905 RR_ChildLock_Status 0;
BA_ "NetworkRequest" SG_ 905 RR_ChildLock_Status 0;
BA_ "NetworkRequestHoldingTime" SG_ 905 RR_ChildLock_Status 5000;
BA_ "Version" SG_ 905 RR_ChildLock_Status "21.07.07";
BA_ "GenSigSendType" SG_ 905 USM_RRGhostDoorSta 4;
BA_ "UserSigValidity" SG_ 905 USM_RRGhostDoorSta 0;
BA_ "NetworkRequest" SG_ 905 USM_RRGhostDoorSta 0;
BA_ "NetworkRequestHoldingTime" SG_ 905 USM_RRGhostDoorSta 5000;
BA_ "Version" SG_ 905 USM_RRGhostDoorSta "21.03.11";
BA_ "GenSigSendType" SG_ 905 DoorLock_PDSLkSwSta_RR 4;
BA_ "UserSigValidity" SG_ 905 DoorLock_PDSLkSwSta_RR 0;
BA_ "NetworkRequest" SG_ 905 DoorLock_PDSLkSwSta_RR 0;
BA_ "Version" SG_ 905 DoorLock_PDSLkSwSta_RR "19.12.00";
BA_ "GenSigSendType" SG_ 905 PDS_TypeOption_RR 4;
BA_ "UserSigValidity" SG_ 905 PDS_TypeOption_RR 0;
BA_ "NetworkRequest" SG_ 905 PDS_TypeOption_RR 0;
BA_ "Version" SG_ 905 PDS_TypeOption_RR "19.12.00";
BA_ "GenSigSendType" SG_ 905 RRDoorPushAlarm 4;
BA_ "UserSigValidity" SG_ 905 RRDoorPushAlarm 0;
BA_ "NetworkRequest" SG_ 905 RRDoorPushAlarm 0;
BA_ "NetworkRequestHoldingTime" SG_ 905 RRDoorPushAlarm 5000;
BA_ "Version" SG_ 905 RRDoorPushAlarm "20.09.00";
BA_ "GenMsgSendType" BO_ 929 0;
BA_ "Description" SG_ 929 SCM_Opt "SCM option";
BA_ "GenSigSendType" SG_ 929 SCM_Opt 4;
BA_ "UserSigValidity" SG_ 929 SCM_Opt 0;
BA_REL_ "GenSigTimeoutTime" BU_SG_REL_ DPSU SG_ 929 SCM_Opt 1500;
BA_REL_ "GenSigTimeoutTime" BU_SG_REL_ CGW_CCU SG_ 929 SCM_Opt 1500;
BA_ "NetworkRequest" SG_ 929 SCM_Opt 0;
BA_ "NetworkRequestHoldingTime" SG_ 929 SCM_Opt 5000;
BA_ "Version" SG_ 929 SCM_Opt "21.02.00";
BA_ "Description" SG_ 929 Tilt_VirtualLimExist "Tilt virtual limit existence";
BA_ "GenSigSendType" SG_ 929 Tilt_VirtualLimExist 4;
BA_ "UserSigValidity" SG_ 929 Tilt_VirtualLimExist 0;
BA_REL_ "GenSigTimeoutTime" BU_SG_REL_ CGW_CCU SG_ 929 Tilt_VirtualLimExist 1500;
BA_ "NetworkRequest" SG_ 929 Tilt_VirtualLimExist 0;
BA_ "NetworkRequestHoldingTime" SG_ 929 Tilt_VirtualLimExist 5000;
BA_ "Version" SG_ 929 Tilt_VirtualLimExist "21.02.00";
BA_ "Description" SG_ 929 Tele_Snsr_Err "Telescopic operating error by Sensor";
BA_ "GenSigSendType" SG_ 929 Tele_Snsr_Err 4;
BA_ "TimeoutValue" SG_ 929 Tele_Snsr_Err "0x0";
BA_ "UserSigValidity" SG_ 929 Tele_Snsr_Err 0;
BA_REL_ "GenSigTimeoutTime" BU_SG_REL_ CGW_CCU SG_ 929 Tele_Snsr_Err 1500;
BA_ "NetworkRequest" SG_ 929 Tele_Snsr_Err 0;
BA_ "NetworkRequestHoldingTime" SG_ 929 Tele_Snsr_Err 5000;
BA_ "Version" SG_ 929 Tele_Snsr_Err "21.02.00";
BA_ "Description" SG_ 929 Tele_VirtualLim "Reached to Telescopic Virtual Limit";
BA_ "GenSigSendType" SG_ 929 Tele_VirtualLim 4;
BA_ "TimeoutValue" SG_ 929 Tele_VirtualLim "0x0";
BA_ "UserSigValidity" SG_ 929 Tele_VirtualLim 0;
BA_REL_ "GenSigTimeoutTime" BU_SG_REL_ CGW_CCU SG_ 929 Tele_VirtualLim 1500;
BA_ "NetworkRequest" SG_ 929 Tele_VirtualLim 0;
BA_ "NetworkRequestHoldingTime" SG_ 929 Tele_VirtualLim 5000;
BA_ "Version" SG_ 929 Tele_VirtualLim "21.02.00";
BA_ "Description" SG_ 929 Tele_VirtualLimExist "Telescopic virtual limit existence";
BA_ "GenSigSendType" SG_ 929 Tele_VirtualLimExist 4;
BA_ "UserSigValidity" SG_ 929 Tele_VirtualLimExist 0;
BA_REL_ "GenSigTimeoutTime" BU_SG_REL_ CGW_CCU SG_ 929 Tele_VirtualLimExist 1500;
BA_ "NetworkRequest" SG_ 929 Tele_VirtualLimExist 0;
BA_ "NetworkRequestHoldingTime" SG_ 929 Tele_VirtualLimExist 5000;
BA_ "Version" SG_ 929 Tele_VirtualLimExist "21.02.00";
BA_ "Description" SG_ 929 TiltTele_Profile1MemoryExist "Profile1 memory existence";
BA_ "GenSigSendType" SG_ 929 TiltTele_Profile1MemoryExist 4;
BA_ "UserSigValidity" SG_ 929 TiltTele_Profile1MemoryExist 0;
BA_REL_ "GenSigTimeoutTime" BU_SG_REL_ CGW_CCU SG_ 929 TiltTele_Profile1MemoryExist 1500;
BA_ "NetworkRequest" SG_ 929 TiltTele_Profile1MemoryExist 0;
BA_ "NetworkRequestHoldingTime" SG_ 929 TiltTele_Profile1MemoryExist 5000;
BA_ "Version" SG_ 929 TiltTele_Profile1MemoryExist "21.02.00";
BA_ "Description" SG_ 929 Tilt_MnlSwSta "Tilt manual switch state";
BA_ "GenSigSendType" SG_ 929 Tilt_MnlSwSta 4;
BA_ "TimeoutValue" SG_ 929 Tilt_MnlSwSta "0x0";
BA_ "UserSigValidity" SG_ 929 Tilt_MnlSwSta 0;
BA_REL_ "GenSigTimeoutTime" BU_SG_REL_ CGW_CCU SG_ 929 Tilt_MnlSwSta 1500;
BA_ "NetworkRequest" SG_ 929 Tilt_MnlSwSta 0;
BA_ "NetworkRequestHoldingTime" SG_ 929 Tilt_MnlSwSta 5000;
BA_ "Version" SG_ 929 Tilt_MnlSwSta "21.02.00";
BA_ "Description" SG_ 929 TiltTele_Profile2MemoryExist "Profile2 memory existence";
BA_ "GenSigSendType" SG_ 929 TiltTele_Profile2MemoryExist 4;
BA_ "UserSigValidity" SG_ 929 TiltTele_Profile2MemoryExist 0;
BA_REL_ "GenSigTimeoutTime" BU_SG_REL_ CGW_CCU SG_ 929 TiltTele_Profile2MemoryExist 1500;
BA_ "NetworkRequest" SG_ 929 TiltTele_Profile2MemoryExist 0;
BA_ "NetworkRequestHoldingTime" SG_ 929 TiltTele_Profile2MemoryExist 5000;
BA_ "Version" SG_ 929 TiltTele_Profile2MemoryExist "21.02.00";
BA_ "Description" SG_ 929 TiltTele_GuestMemoryExist "Guest memory existence";
BA_ "GenSigSendType" SG_ 929 TiltTele_GuestMemoryExist 4;
BA_ "UserSigValidity" SG_ 929 TiltTele_GuestMemoryExist 0;
BA_REL_ "GenSigTimeoutTime" BU_SG_REL_ CGW_CCU SG_ 929 TiltTele_GuestMemoryExist 1500;
BA_ "NetworkRequest" SG_ 929 TiltTele_GuestMemoryExist 0;
BA_ "NetworkRequestHoldingTime" SG_ 929 TiltTele_GuestMemoryExist 5000;
BA_ "Version" SG_ 929 TiltTele_GuestMemoryExist "21.02.00";
BA_ "Description" SG_ 929 TiltTele_IMS1MemoryExist "IMS1 memory existence";
BA_ "GenSigSendType" SG_ 929 TiltTele_IMS1MemoryExist 4;
BA_ "UserSigValidity" SG_ 929 TiltTele_IMS1MemoryExist 0;
BA_REL_ "GenSigTimeoutTime" BU_SG_REL_ CGW_CCU SG_ 929 TiltTele_IMS1MemoryExist 1500;
BA_ "NetworkRequest" SG_ 929 TiltTele_IMS1MemoryExist 0;
BA_ "NetworkRequestHoldingTime" SG_ 929 TiltTele_IMS1MemoryExist 5000;
BA_ "Version" SG_ 929 TiltTele_IMS1MemoryExist "21.02.00";
BA_ "Description" SG_ 929 TiltTele_IMS2MemoryExist "IMS2 memory existence";
BA_ "GenSigSendType" SG_ 929 TiltTele_IMS2MemoryExist 4;
BA_ "UserSigValidity" SG_ 929 TiltTele_IMS2MemoryExist 0;
BA_REL_ "GenSigTimeoutTime" BU_SG_REL_ CGW_CCU SG_ 929 TiltTele_IMS2MemoryExist 1500;
BA_ "NetworkRequest" SG_ 929 TiltTele_IMS2MemoryExist 0;
BA_ "NetworkRequestHoldingTime" SG_ 929 TiltTele_IMS2MemoryExist 5000;
BA_ "Version" SG_ 929 TiltTele_IMS2MemoryExist "21.02.00";
BA_ "Description" SG_ 929 TiltTele_IMS3MemoryExist "IMS3 memory existence";
BA_ "GenSigSendType" SG_ 929 TiltTele_IMS3MemoryExist 4;
BA_ "UserSigValidity" SG_ 929 TiltTele_IMS3MemoryExist 0;
BA_REL_ "GenSigTimeoutTime" BU_SG_REL_ CGW_CCU SG_ 929 TiltTele_IMS3MemoryExist 1500;
BA_ "NetworkRequest" SG_ 929 TiltTele_IMS3MemoryExist 0;
BA_ "NetworkRequestHoldingTime" SG_ 929 TiltTele_IMS3MemoryExist 5000;
BA_ "Version" SG_ 929 TiltTele_IMS3MemoryExist "21.02.00";
BA_ "Description" SG_ 929 TiltTele_ReturnMemoryExist "Auto Return memory existence";
BA_ "GenSigSendType" SG_ 929 TiltTele_ReturnMemoryExist 4;
BA_ "UserSigValidity" SG_ 929 TiltTele_ReturnMemoryExist 0;
BA_REL_ "GenSigTimeoutTime" BU_SG_REL_ CGW_CCU SG_ 929 TiltTele_ReturnMemoryExist 1500;
BA_ "NetworkRequest" SG_ 929 TiltTele_ReturnMemoryExist 0;
BA_ "NetworkRequestHoldingTime" SG_ 929 TiltTele_ReturnMemoryExist 5000;
BA_ "Version" SG_ 929 TiltTele_ReturnMemoryExist "21.02.00";
BA_ "Description" SG_ 929 Tilt_OpSta "Tilt operating state (Motor output command, not real motor output)";
BA_ "GenSigSendType" SG_ 929 Tilt_OpSta 4;
BA_ "TimeoutValue" SG_ 929 Tilt_OpSta "0x0";
BA_ "UserSigValidity" SG_ 929 Tilt_OpSta 0;
BA_REL_ "GenSigTimeoutTime" BU_SG_REL_ CGW_CCU SG_ 929 Tilt_OpSta 1500;
BA_ "NetworkRequest" SG_ 929 Tilt_OpSta 0;
BA_ "NetworkRequestHoldingTime" SG_ 929 Tilt_OpSta 5000;
BA_ "Version" SG_ 929 Tilt_OpSta "21.05.01";
BA_ "Description" SG_ 929 Tele_OpSta "Telescopic operating state (Motor output command, not real motor output)";
BA_ "GenSigSendType" SG_ 929 Tele_OpSta 4;
BA_ "TimeoutValue" SG_ 929 Tele_OpSta "0x0";
BA_ "UserSigValidity" SG_ 929 Tele_OpSta 0;
BA_REL_ "GenSigTimeoutTime" BU_SG_REL_ CGW_CCU SG_ 929 Tele_OpSta 1500;
BA_ "NetworkRequest" SG_ 929 Tele_OpSta 0;
BA_ "NetworkRequestHoldingTime" SG_ 929 Tele_OpSta 5000;
BA_ "Version" SG_ 929 Tele_OpSta "21.05.01";
BA_ "Description" SG_ 929 Tele_MnlSwSta "Telescopic manual switch state";
BA_ "GenSigSendType" SG_ 929 Tele_MnlSwSta 4;
BA_ "TimeoutValue" SG_ 929 Tele_MnlSwSta "0x0";
BA_ "UserSigValidity" SG_ 929 Tele_MnlSwSta 0;
BA_REL_ "GenSigTimeoutTime" BU_SG_REL_ CGW_CCU SG_ 929 Tele_MnlSwSta 1500;
BA_ "NetworkRequest" SG_ 929 Tele_MnlSwSta 0;
BA_ "NetworkRequestHoldingTime" SG_ 929 Tele_MnlSwSta 5000;
BA_ "Version" SG_ 929 Tele_MnlSwSta "21.02.02";
BA_ "Description" SG_ 929 Tilt_SnsrErr "Tilt operating error by Sensor";
BA_ "GenSigSendType" SG_ 929 Tilt_SnsrErr 4;
BA_ "TimeoutValue" SG_ 929 Tilt_SnsrErr "0x0";
BA_ "UserSigValidity" SG_ 929 Tilt_SnsrErr 0;
BA_REL_ "GenSigTimeoutTime" BU_SG_REL_ CGW_CCU SG_ 929 Tilt_SnsrErr 1500;
BA_ "NetworkRequest" SG_ 929 Tilt_SnsrErr 0;
BA_ "NetworkRequestHoldingTime" SG_ 929 Tilt_SnsrErr 5000;
BA_ "Version" SG_ 929 Tilt_SnsrErr "21.02.00";
BA_ "Description" SG_ 929 Tilt_VirtualLim "Reached to Tilt virtual limit";
BA_ "GenSigSendType" SG_ 929 Tilt_VirtualLim 4;
BA_ "TimeoutValue" SG_ 929 Tilt_VirtualLim "0x0";
BA_ "UserSigValidity" SG_ 929 Tilt_VirtualLim 0;
BA_REL_ "GenSigTimeoutTime" BU_SG_REL_ CGW_CCU SG_ 929 Tilt_VirtualLim 1500;
BA_ "NetworkRequest" SG_ 929 Tilt_VirtualLim 0;
BA_ "NetworkRequestHoldingTime" SG_ 929 Tilt_VirtualLim 5000;
BA_ "Version" SG_ 929 Tilt_VirtualLim "21.02.00";
VAL_ 2239851009 RSPA_AvnDis 0 "init" 1 "No display" 2 "RSPA È­¸é Ãâ·Â" 3 "invalid" ;
VAL_ 2239851009 RSPA_AvnModDis 0 "init" 1 "ÁÖÂ÷¸ðµå" 2 "ÃâÂ÷¸ðµå" 3 "invalid" ;
VAL_ 2239851009 RSPA_AvnModNumDis 0 "init" 1 "2¸ðµå" 2 "4¸ðµå" 3 "6¸ðµå" 4 "8¸ðµå" 5 "reserved" 6 "reserved" 7 "invalid" ;
VAL_ 2239851009 RSPA_AvnSubViewDis 0 "init" 1 "No display" 2 "´ëÃ¼ÀÌ¹ÌÁö Ãâ·Â" 3 "invalid" ;
VAL_ 2239851009 RSPA_AvnModPLDis 0 "init" 1 "Á¦¾îºÒ°¡´É" 2 "Á¦¾î°¡´É" 3 "invalid" ;
VAL_ 2239851009 RSPA_AvnModPDRLDis 0 "init" 1 "Á¦¾îºÒ°¡´É" 2 "Á¦¾î°¡´É" 3 "invalid" ;
VAL_ 2239851009 RSPA_AvnModPDRRDis 0 "init" 1 "Á¦¾îºÒ°¡´É" 2 "Á¦¾î°¡´É" 3 "invalid" ;
VAL_ 2239851009 RSPA_AvnModPRDis 0 "init" 1 "Á¦¾îºÒ°¡´É" 2 "Á¦¾î°¡´É" 3 "invalid" ;
VAL_ 2239851009 RSPA_CamDis 0 "No Display (RSPA ¿¬µ¿ ÇØÁ¦)" 1 "AVM (ºä ¸Þ´º¹Ù ¹ÌÇ¥½Ã) ¿ÍÀÌµåºä ºí·¢+Å¾ºä / RVM: View OFF" 2 "AVM (ºä ¸Þ´º¹Ù ¹ÌÇ¥½Ã) ¿ÍÀÌµåºä Àü¹æ+Å¾ºä / RVM: Parking Assist View (Guide L. X)" 3 "AVM (ºä ¸Þ´º¹Ù ¹ÌÇ¥½Ã) ¿ÍÀÌµåºä ÈÄ¹æ+Å¾ºä / RVM: Parking Assist View (Guide L. O)" 4 "reserved" 5 "reserved" 6 "reserved" 7 "Invalid" ;
VAL_ 2239851009 RSPA_AvnHmiDis 0 "none" 1 "Select operating mode" 2 "SMART Parking" 3 "REMOTE Parking" 4 "Parking completed" 5 "SMART Pull-out" 6 "Pull-out completed" 7 "RSPA cancelled - Read Manual" 8 "RSPA cancelled - Operate vehicle manually" 9 "Not working condition - Exceed Limit Speed" 10 "Searching for Parking space - Reduce speed under 20km" 11 "Check RSPA - Visit Tech Center" 12 "Reserved" 13 "display Front camera - moving forward" 14 "display Rear camera - moving backward" 15 "Reserved" 16 "RSPA paused - Check tailgate closed" 17 "RSPA paused - Remote control range exceeded" 18 "RSPA pasued - Hold down dedicated button on key fob" 19 "Parking completed - manually" 20 "Pull-out completed - manually" 21 "Reserved" 22 "RSPA paused - Check all doors closed" 23 "RSPA paused - Check trunk closed" 24 "RSPA paused - RCCW" 25 "RSPA paused - Fasten seat belt on drivers side" 26 "Operation guide - Release brake" 27 "RSPA paused - Monitor surrounding area" 28 "RSPA cancelled - Trailer mode" 29 "RSPA cancelled - PDW Off" 30 "RSPA cancelled - over 20km" 31 "RSPA cancelled - not stop" 32 "RSPA cancelled - reverse movement" 33 "RSPA cancelled - narrow space" 34 "Not working condition - trailer mode" 35 "RSPA cancelled - Monitor surrounding area" 36 "RSPA cancelled - Check road condition" 37 "RSPA cancelled - Exceed operating distance" 38 "RSPA cancelled - Exceed operation time" 39 "RSPA cancelled - Detect cancel input" 40 "RSPA cancelled - Detect remote start button input" 41 "RSPA cancelled - Detect B" 42 "RSPA cancelled - Detect unfasten S" 43 "RSPA cancelled - Detect T" 44 "RSPA cancelled - Detect EPB operation" 45 "RSPA cancelled - Detect Pedal operation" 46 "RSPA cancelled - Hood open" 47 "RSPA cancelled - Detect S" 48 "RSPA cancelled - USS blockage" 49 "RSPA cancelled - Check SVM Camera" 50 "Reserved" 51 "Reserved" 52 "Reserved" 53 "Reserved" 54 "Reserved" 55 "Reserved" 56 "Reserved" 57 "Reserved" 58 "Reserved" 59 "Reserved" 60 "Reserved" 61 "Reserved" 62 "Reserved" 63 "Reserved" 64 "Reserved" 65 "Reserved" 66 "Reserved" 67 "Reserved" 68 "Reserved" 69 "Reserved" 70 "Reserved" 71 "Reserved" 72 "Reserved" 73 "Reserved" 74 "Reserved" 75 "Reserved" 76 "Reserved" 77 "Reserved" 78 "Reserved" 79 "Reserved" 80 "Reserved" 81 "Reserved" 82 "Reserved" 83 "Reserved" 84 "Reserved" 85 "Reserved" 86 "Reserved" 87 "Reserved" 88 "Reserved" 89 "Reserved" 90 "Reserved" 91 "Reserved" 92 "Reserved" 93 "Reserved" 94 "Reserved" 95 "Reserved" 96 "Reserved" 97 "Reserved" 98 "Reserved" 99 "Reserved" 100 "Reserved" 101 "Reserved" 102 "Reserved" 103 "Reserved" 104 "Reserved" 105 "Reserved" 106 "Reserved" 107 "Reserved" 108 "Reserved" 109 "Reserved" 110 "Reserved" 111 "Reserved" 112 "Reserved" 113 "Reserved" 114 "Reserved" 115 "Reserved" 116 "Reserved" 117 "Reserved" 118 "Reserved" 119 "Reserved" 120 "Reserved" 121 "Reserved" 122 "Reserved" 123 "Reserved" 124 "Reserved" 125 "Reserved" 126 "Reserved" 127 "Reserved" 128 "Searching for Parking space - Drive forwards" 129 "Searching Completed - Stop vehicle to park or Move forward" 130 "Select parking mode" 131 "Checking space - Stop the vehicle to check space" 132 "Checking completed - Select pull-out mode" 133 "Remote Moving F" 134 "under Remote Control" 135 "Remote Moving F" 136 "Operation guide - Reinput Parking Button" 137 "Operation guide - Reinput SMART Key Button" 138 "Not working condition - Read Manual" 139 "Not working condition - Steep road slope up" 140 "Not working condition - Steep road slope down" 141 "RSPA cancelled - Steep road slope up" 142 "RSPA cancelled - Steep road slope down" 143 "Not working condition - USS blockage" 144 "RSPA Guide Pop - up" 145 "RSPA cancelled ? DCT overtemp" 146 "Not working condition ? DCT overtemp" 147 "Checking Completed - Remote exit control" 148 "0x94~0xFE:Reserved" 254 "0x94~0xFE:Reserved" 255 "Invalid" ;
VAL_ 2239851010 RSPA_Var 0 "init" 1 "RSPA (ENTRY)" 2 "RSPA" 3 "RSPA II" 4 "Reserved" 5 "Reserved" 6 "Reserved" 7 "Reserved" 8 "Reserved" 9 "Reserved" 10 "Reserved" 11 "Reserved" 12 "Reserved" 13 "Reserved" 14 "Reserved" 15 "Invalid" ;
VAL_ 2239851010 RSPA_Sta 0 "RSPA not recognized" 1 "Init" 2 "New Start" 3 "Ready OK" 4 "Assist Req" 5 "Assist OK" 6 "Assist Fail" 7 "Abort" 8 "Ready Fail" ;
VAL_ 2239851010 RSPA_Actv 0 "RSPA Off" 1 "RSPA On" 2 "Reserved" 3 "Reserved" ;
VAL_ 2239851010 RSPA_EvasiveStrBtnDis 0 "Initial" 1 "Do not display evasive steering on/off button" 2 "Display evasive steering on/off button" 3 "Invalid" ;
VAL_ 2239851011 RSPA_TrgtGearSta 0 "Idle" 1 "P" 2 "R" 3 "N" 4 "D" ;
VAL_ 2239851011 RSPA_IdOutWarnReq 0 "No Request" 1 "Change Request" 2 "Not Used" 3 "Error Indicator" ;
VAL_ 2239851011 RSPA_IndBlnkReq 0 "No request" 1 "Type1" 2 "Type2" 3 "Type3" 4 "Type4" 5 "Type5" 6 "Reserved" 7 "Reserved" ;
VAL_ 2239851011 RSPA_SysOff 0 "default" 1 "system off" ;
VAL_ 2239851011 RSPA_DccCmd 0 "No request" 1 "Soft Brake" 2 "Hard 1 Brake" 3 "Hard 2 Brake" ;
VAL_ 2239851011 RSPA_StopReq 0 "No request" 1 "Stop control is required" 2 "Not Used" 3 "Error Indicator" ;
VAL_ 2239851011 RSPA_SelDevInfo 0 "default" 1 "SmartPhone" 2 "Fob" 3 "Reserved" ;
VAL_ 2239851011 RSPA_SelFuncInfo 0 "default" 1 "Parking" 2 "Remote Forward/Backward" 3 "Reserved" ;
VAL_ 2239851011 RSPA_EpbReq 0 "No request" 1 "release request" 2 "normal apply" ;
VAL_ 2239851011 RSPA_AddtnlAccelActv 0 "Inactive" 1 "Active" 2 "Not Used" 3 "Error Indicator" ;
VAL_ 2239851011 RSPA_Opt 0 "RSPA not applied" 1 "RSPA applied" 2 "Not Used" 3 "Error Indicator" ;
VAL_ 2239851011 RSPA_RmtPrlExitDis 0 "Initial" 1 "Do not display remote parallel exit" 2 "Display remote parallel exit" 3 "Invalid" ;
VAL_ 2239851011 RSPA_ExtLampReq 0 "Inactive (No Request)" 1 "Hazard Lamp Active On" 2 "Hazard Lamp Active Off" 3 "Left Turn Signal On" 4 "Right Turn Signal On" 5 "reserved" 6 "reserved" 7 "reserved" ;
VAL_ 2239851011 RSPA_UppLtTypDis 0 "init" 1 "Not found" 2 "Reverse perpendicular" 3 "Reverse parallel" 4 "Reverse diagonal" 5 "Forward diagonal" 6 "Reserved" 7 "Invalid" ;
VAL_ 2239851011 RSPA_LwrLtTypDis 0 "init" 1 "Not found" 2 "Reverse perpendicular" 3 "Reverse parallel" 4 "Reverse diagonal" 5 "Forward diagonal" 6 "Reserved" 7 "Invalid" ;
VAL_ 2239851011 RSPA_UppRtTypDis 0 "init" 1 "Not found" 2 "Reverse perpendicular" 3 "Reverse parallel" 4 "Reverse diagonal" 5 "Forward diagonal" 6 "Reserved" 7 "Invalid" ;
VAL_ 2239851011 RSPA_LwrRtTypDis 0 "init" 1 "Not found" 2 "Reverse perpendicular" 3 "Reverse parallel" 4 "Reverse diagonal" 5 "Forward diagonal" 6 "Reserved" 7 "Invalid" ;
VAL_ 2239851011 RSPA_CrankingReq 0 "Init" 1 "to RSPA Remote Cranking" 2 "to Normal Cranking" 3 "to IG OFF" ;
VAL_ 911 ATS_RearLock_Set 0 "Unlock" 1 "LockON" 2 "Reserved" 3 "Invalid" ;
VAL_ 911 ATS_RrCurtainBtn 0 "Default" 1 "Open ON" 2 "Close ON" 3 "Invaild" ;
VAL_ 911 ATS_RrDrCurtainBtn 0 "Default" 1 "Open ON" 2 "Close ON" 3 "Invalid" ;
VAL_ 911 ATS_RLDrCurtainBtn 0 "Default" 1 "Open ON" 2 "Close ON" 3 "Invaild" ;
VAL_ 911 ATS_RRSunBlind 0 "Default" 1 "Open ON" 2 "Close ON" 3 "Stop ON" 4 "Reserved" 5 "Reserved" 6 "Reserved" 7 "Reserved" 8 "Reserved" 9 "Reserved" 10 "Reserved" 11 "Reserved" 12 "Reserved" 13 "Reserved" 14 "Reserved" 15 "Invalid" ;
VAL_ 911 ATS_FCS_LockTrayIniPwSet 0 "Default (Initial Value)" 1 "Initial Pw Set" 2 "reserved" 3 "Invaild" ;
VAL_ 911 ATS_FCS_LockTrayKeyPadNo 0 "0" 1 "1" 2 "2" 3 "3" 4 "4" 5 "5" 6 "6" 7 "7" 8 "8" 9 "9" 10 "reserved" 11 "reserved" 12 "reserved" 13 "reserved" 14 "reserved" 15 "Invalid" ;
VAL_ 911 ATS_FCS_LockTrayNoDel 0 "Default (Initial Value)" 1 "Number Delete" 2 "reserved" 3 "Invaild" ;
VAL_ 911 ATS_FCS_LockTrayNoClr 0 "Default (Initial Value)" 1 "Number Clear" 2 "reserved" 3 "Invaild" ;
VAL_ 911 ATS_FCS_LockTrayPwChange 0 "Default (Initial Value)" 1 "Password Change" 2 "reserved" 3 "Invaild" ;
VAL_ 911 ATS_FCS_LockTrayPwReset 0 "Default (Initial Value)" 1 "Password Reset" 2 "reserved" 3 "Invaild" ;
VAL_ 911 ATS_FCS_LockTrayCancel 0 "Default (Initial Value)" 1 "Cancel" 2 "reserved" 3 "Invaild" ;
VAL_ 915 Trunk_IBU_OpnDiagSetSta 0 "OFF" 1 "ON" 2 "Not Used" 3 "Error Indicator" ;
VAL_ 915 Trunk_TrnkTlgtReleaseRly 0 "Off" 1 "On" 2 "Invalid" 3 "Error Indicator" ;
VAL_ 915 Trunk_TrnkTlgtOpenOutput_PTGM 0 "Off" 1 "On" 2 "Invalid" 3 "Error Indicator" ;
VAL_ 915 Trunk_TrnkTlgtOpenOutput_ICU 0 "Off" 1 "On" 2 "Invalid" 3 "Error Indicator" ;
VAL_ 915 Trunk_TrnkPassiveOpenOutput 0 "Off" 1 "On" 2 "Invalid" 3 "Error Indicator" ;
VAL_ 915 TiltTele_CurProfileState 0 "Dafault" 1 "Guest" 2 "Profile 1" 3 "Profile 2" 4 "Not Used" 5 "Not Used" 6 "Not Used" 7 "Error Indicator" ;
VAL_ 915 TiltTele_USMEsyAcsSetState 0 "Default" 1 "Steering Off" 2 "Steering On" 3 "Error Indicator" ;
VAL_ 915 TiltTele_PreEsyAcsProfile 0 "Default" 1 "Profile 1" 2 "Profile 2" 3 "Guest" 4 "Not Used" 5 "Not Used" 6 "Not Used" 7 "Error Indicator" ;
VAL_ 915 Tilt_MnlInitCmd 0 "Off" 1 "Up" 2 "Down" 3 "Error Indicator" ;
VAL_ 915 Tilt_MnlOpCmd 0 "Off" 1 "Up" 2 "Down" 3 "Error Indicator" ;
VAL_ 915 Tele_MnlInitCmd 0 "Off" 1 "Fwd" 2 "Bwd" 3 "Error Indicator" ;
VAL_ 915 Tilt_AutoOpCmd 0 "Off" 1 "GetOn" 2 "GetOff" 3 "IMS 1" 4 "IMS 2" 5 "IMS 3" 6 "SmartIMS" 7 "PersonalizationService" 8 "PreEasyAccessProfileGetOff" 9 "PreEasyAccessProfileLast" 10 "OneTouchRelax" 11 "OneTouchReturn" 12 "Not Used" 13 "Not Used" 14 "Not Used" 15 "Error Indicator" ;
VAL_ 915 TiltTele_PlyBckState 0 "Stop" 1 "Play 1" 2 "Play 2" 3 "Play 3" 4 "SmartIMS" 5 "Profile 1" 6 "Profile 2" 7 "Guest" 8 "Not Used" 9 "Not Used" 10 "Not Used" 11 "Not Used" 12 "Not Used" 13 "Not Used" 14 "Not Used" 15 "Error Indicator" ;
VAL_ 915 Tele_MnlOpCmd 0 "Off" 1 "Fwd" 2 "Bwd" 3 "Error Indicator" ;
VAL_ 915 Tele_AutoOpCmd 0 "Off" 1 "IMS1" 2 "IMS2" 3 "IMS3" 4 "SmartIMS" 5 "PersonalizationService" 6 "PreEasyAccessProfileGetOff" 7 "PreEasyAccessProfileLast" 8 "OneTouchRelax" 9 "OneTouchReturn" 10 "Not Used" 11 "Not Used" 12 "Not Used" 13 "Not Used" 14 "Not Used" 15 "Error Indicator" ;
VAL_ 2382594817 DATC_MaxAcDis 0 "Off" 1 "On" 2 "Not used" 3 "Error Indicator" ;
VAL_ 2382594817 DATC_SyncDis 0 "SYNC Off" 1 "SYNC On" 2 "Not used" 3 "Error Indicator" ;
VAL_ 2382594817 DATC_OpSta 0 "DATC Off (Power Down)" 1 "DATC Normal" 2 "DATC System Off (Blower Off)" 3 "DATC Self Diagnosis" 4 "Not used" 5 "Not used" 6 "Not used" 7 "Error Indicator" ;
VAL_ 2382594817 DATC_FrDfgSta 0 "Off" 1 "On" 2 "Not used" 3 "Error Indicator" ;
VAL_ 2382594817 DATC_SmrtVntDis 0 "Off" 1 "Smart Ventilation" 2 "Smart CO2" 3 "Error Indicator" ;
VAL_ 2382594817 DATC_AutoDfgBlnkDis 0 "AutoDefogBlink Non Request" 1 "AutoDefogBlink Request" 2 "Not used" 3 "Error Indicator" ;
VAL_ 2382594817 DATC_AutoDfgSysOffDis 0 "'ADS OFF' display Off" 1 "'ADS OFF' display On" 2 "Not Used(Non-ADS)" 3 "Error Indicator" ;
VAL_ 2382594817 DATC_ArClnIND 0 "Default" 1 "OFF" 2 "ON" 3 "Error Indicator" ;
VAL_ 2382594817 DATC_RrDfgInd 0 "Default" 1 "OFF" 2 "ON" 3 "Error Indicator" ;
VAL_ 2382594817 DATC_FrModDEFInd 0 "Default" 1 "OFF" 2 "ON" 3 "Error Indicator" ;
VAL_ 2382594817 DATC_FrModVentInd 0 "Default" 1 "OFF" 2 "ON" 3 "Error Indicator" ;
VAL_ 2382594817 DATC_FrModFloorInd 0 "Default" 1 "OFF" 2 "ON" 3 "Error Indicaotr" ;
VAL_ 2424580609 DATC_MltAutoBlrTxt 0 "Default" 1 "Blank" 2 "LOW" 3 "MEDIUM" 4 "HIGH" 5 "Reserved" 6 "Reserved" 7 "ErrorIndicaor" ;
VAL_ 2424580609 DATC_MltAutoBlrTxt_Ps 0 "Default" 1 "Blank" 2 "LOW" 3 "MEDIUM" 4 "HIGH" 5 "Reserved" 6 "Reserved" 7 "ErrorIndicaor" ;
VAL_ 2424580609 DATC_MltAutoBlrTxt_Rr 0 "Default" 1 "Blank" 2 "LOW" 3 "MEDIUM" 4 "HIGH" 5 "Reserved" 6 "Reserved" 7 "ErrorIndicaor" ;
VAL_ 2424580609 DATC_RLStTmblrSwReq 0 "Default" 1 "Up" 2 "Down" 3 "Error Indicator" ;
VAL_ 2424580609 DATC_RRStTmblrSwReq 0 "Default" 1 "Up" 2 "Down" 3 "Error Indicator" ;
VAL_ 2424580609 DATC_DisPnlState 0 "Front Display State" 1 "Rear Display State" 2 "Not used" 3 "Error Indicator" ;
VAL_ 912 HU_BLTN_CAM_UI_Mode 0 "HU UI mode" 1 "Built-In Cam Mode(GUI or HU File Access)" 2 "Reserved" 3 "Reserved" 4 "Reserved" 5 "Reserved" 6 "Reserved" 7 "Reserved" 8 "Reserved" 9 "Reserved" 10 "Reserved" 11 "Reserved" 12 "Reserved" 13 "Reserved" 14 "Reserved" 15 "Invalid" ;
VAL_ 912 HU_BLTN_CAM_Display 0 "AVN Mode" 1 "DVRS Mode" 2 "Popup Mode" 3 "Reserved" 4 "Reserved" 5 "Built-in Cam update mode" 6 "Reserved" 7 "Invalid" ;
VAL_ 913 PSD_USMSetSta 0 "Default" 1 "Power Mode" 2 "Manual Mode" 3 "Invalid" ;
VAL_ 913 Lamp_HzrdSta 0 "Off" 1 "On" 2 "Inactive" 3 "RESERVED" ;
VAL_ 913 PSD_OptTyp 0 "Off" 1 "On(PSD is applied)" 2 "RESERVED" 3 "Error Indicator" ;
VAL_ 913 PSD_LHSEAActivated 0 "Inactivated" 1 "Activated" ;
VAL_ 913 PSD_RHSEAActivated 0 "Inactivated" 1 "Activated" ;
VAL_ 913 PSD_LHPSDLatchState 0 "Latch Primary position" 1 "Latch Before Primary position" 2 "Latch Secondary position" 3 "Latch Secondary mid position" 4 "Latch Unlatched position" 5 "Latch Unknown position" 6 "Latch Error position" 7 "RESERVED" ;
VAL_ 913 PSD_RHPSDLatchState 0 "Latch Primary position" 1 "Latch Before primary position" 2 "Latch Secondary position" 3 "Latch Secondary mid positon" 4 "Latch Unlatched position" 5 "Latch Unknown position" 6 "Latch Error position" 7 "RESERVED" ;
VAL_ 913 C_PSDOptLHRH 0 "Not applied" 1 "Both side" 2 "RH" 3 "LH" ;
VAL_ 913 PSD_AllDrOpnSetRValue 0 "Default" 1 "Off" 2 "PSD Open" 3 "PSD PTG Open" 4 "RESERVED" 5 "RESERVED" 6 "RESERVED" 7 "Invalid" ;
VAL_ 913 PSD_USMAllDrOpenSet 0 "Default" 1 "Off" 2 "All Door Open" 3 "Invalid" ;
VAL_ 913 PSD_ModSta 0 "Power Mode" 1 "Manual Mode" 2 "RESERVED" 3 "Error Indicator" ;
VAL_ 902 PSM_DrvStEsyAcsUSMSta 0 "Default Value" 1 "Off (Disable)" 2 "50mmOn (Enable)" 3 "75mmOn (Enable)" 4 "Reserved" 5 "Reserved" 6 "Reserved" 7 "Invalid" ;
VAL_ 902 PSM_SeatPosPlyBck_Sta 0 "Default" 1 "Moving" 2 "Moving Finish" 3 "Moving not Finish" 4 "Not Used" 5 "Not Used" 6 "STOP" 7 "Not Used" ;
VAL_ 902 PSM_SeatPos_Sta 0 "Default" 1 "Memory1" 2 "Memory2" 3 "Memory3" 4 "Not Used" 5 "Not Used" 6 "Not Used" 7 "Any Postion" ;
VAL_ 902 PSM_SeatPosSldLmt_Sta 0 "Default" 1 "Slide Fwd Limit" 2 "Slide Bwd Limit" 3 "Not Initialized" ;
VAL_ 902 PSM_SeatPosRclnLmt_Sta 0 "Default" 1 "Recline Fwd Limit" 2 "Recline Bwd Limit" 3 "Not Initialized" ;
VAL_ 902 SmrtIMS_StatureRspVal 0 "Default" 1 "Less than 147.5cm" 2 "147.5~152.4cm" 3 "152.5~157.4cm" 4 "157.5~162.4cm" 5 "162.5~167.4cm" 6 "167.5~172.4cm" 7 "172.5~177.4cm" 8 "177.5~182.4cm" 9 "182.5~187.4cm" 10 "187.5~192.4cm" 11 "192.5~197.4cm" 12 "More than 197.5cm" 13 "Reserved" 14 "Reserved" 15 "Invalid" ;
VAL_ 902 SmrtIMS_SeatedHghtRspVal 0 "Default" 1 "Tall" 2 "Middle" 3 "Short" 4 "Reserved" 5 "Reserved" 6 "Reserved" 7 "Reserved" 8 "Reserved" 9 "Reserved" 10 "Reserved" 11 "Reserved" 12 "Reserved" 13 "Reserved" 14 "Reserved" 15 "Invalid" ;
VAL_ 902 SmrtIMS_WghtRspVal 0 "Default" 1 "Under 49.4kg" 2 "49.5~59.4kg" 3 "59.5~69.4kg" 4 "69.5~79.4kg" 5 "79.5~89.4kg" 6 "89.5~99.4kg" 7 "99.5~109.4kg" 8 "109.5~119.4kg" 9 "More than119.5kg" 10 "Reserved" 11 "Reserved" 12 "Reserved" 13 "Reserved" 14 "Reserved" 15 "Invalid" ;
VAL_ 902 SmartIMS_DisReq 0 "Stop" 1 "Moving(recommend position)" 2 "Moving(manual switch, IMS)" 3 "Current Position Analysis" 4 "Move to setting page" 5 "Reserved" 6 "Reserved" 7 "Invalid" ;
VAL_ 902 SmrtIMS_ExitSta 0 "normal" 1 "not IGN" 2 "not P or over 3km/h" 3 "cranking" 4 "seat moving" 5 "PSM is not initialized" 6 "low voltage" 7 "reserved" ;
VAL_ 902 PSM_DrvStRlxTiltUpDis 0 "Default" 1 "Off" 2 "On" 3 "Invalid" ;
VAL_ 902 PSM_DrvStRlxTiltDnDis 0 "Default" 1 "Off" 2 "On" 3 "Invalid" ;
VAL_ 902 PSM_DrvStLegUpDis 0 "Default" 1 "Off" 2 "On" 3 "Invalid" ;
VAL_ 902 PSM_DrvStLegDnDis 0 "Default" 1 "Off" 2 "On" 3 "Invalid" ;
VAL_ 902 Drv_2ndStAutoRlxEnable 0 "Default" 1 "Enable" 2 "Disable" 3 "Invalid" ;
VAL_ 902 Drv_AutoRlxSta 0 "Default" 1 "Auto Relaxion moving" 2 "Reserved" 3 "Invalid" ;
VAL_ 902 Drv_AutoReturnSta 0 "Default" 1 "Auto Return moving" 2 "RESERVED" 3 "Invalid" ;
VAL_ 902 PSM_IMSOptTyp 0 "Default" 1 "IMS Option" 2 "IMS&Smart IMS Option" 3 "Error Indicator" ;
VAL_ 903 PSM_DrvStSldFwdDis 0 "default" 1 "off" 2 "on" 3 "invalid" ;
VAL_ 903 PSM_DrvStTiltDnDis 0 "default" 1 "off" 2 "on" 3 "invalid" ;
VAL_ 903 PSM_DrvStHghtUpDis 0 "default" 1 "off" 2 "on" 3 "invalid" ;
VAL_ 903 PSM_DrvStHghtDnDis 0 "default" 1 "off" 2 "on" 3 "invalid" ;
VAL_ 903 PSM_DrvStCushExtBckwdDis 0 "default" 1 "off" 2 "on" 3 "invalid" ;
VAL_ 903 PSM_DrvStCushExtFwdDis 0 "default" 1 "off" 2 "on" 3 "invalid" ;
VAL_ 903 PSM_DrvStSldBckwdDis 0 "default" 1 "off" 2 "on" 3 "invalid" ;
VAL_ 903 PSM_DrvStHdRstUpDis 0 "default" 1 "off" 2 "on" 3 "invalid" ;
VAL_ 903 PSM_DrvStHdRstDnDis 0 "default" 1 "off" 2 "on" 3 "invalid" ;
VAL_ 903 PSM_DrvStHdRstFwdDis 0 "default" 1 "off" 2 "on" 3 "invalid" ;
VAL_ 903 PSM_DrvStHdRstBckwdDis 0 "default" 1 "off" 2 "on" 3 "invalid" ;
VAL_ 903 PSM_DrvStLmbrDefDis 0 "default" 1 "off" 2 "on" 3 "invalid" ;
VAL_ 903 PSM_DrvStLmbrLoDis 0 "default" 1 "off" 2 "on" 3 "invalid" ;
VAL_ 903 PSM_DrvStLmbrMdlDis 0 "default" 1 "off" 2 "on" 3 "invalid" ;
VAL_ 903 PSM_DrvStLmbrUpDis 0 "default" 1 "off" 2 "on" 3 "invalid" ;
VAL_ 903 PSM_DrvStReclneFwdDis 0 "default" 1 "off" 2 "on" 3 "invalid" ;
VAL_ 903 PSM_DrvStBlstrDefDis 0 "default" 1 "off" 2 "on" 3 "invalid" ;
VAL_ 903 PSM_DrvStBlstrInfDis 0 "default" 1 "off" 2 "on" 3 "invalid" ;
VAL_ 903 PSM_DrvStReclneBckwdDis 0 "default" 1 "off" 2 "on" 3 "invalid" ;
VAL_ 903 PSM_DrvStTiltUpDis 0 "default" 1 "off" 2 "on" 3 "invalid" ;
VAL_ 904 PSM_DrvReclinePosition 0 "0x0x00~0xFE:POSITION" 254 "0x0x00~0xFE:POSITION" 255 "invalid" ;
VAL_ 904 PSM_EsyAcsGetOffSta 0 "off" 1 "on" 2 "Not Used" 3 "Error Indicator" ;
VAL_ 904 PSM_EsyAcsStpSta 0 "off" 1 "on" 2 "Not Used" 3 "Error Indicator" ;
VAL_ 904 PSM_SWVerMajor1 0 "0x0x0~0x7F:ASCII Code Value (HEX)" 127 "0x0x0~0x7F:ASCII Code Value (HEX)" ;
VAL_ 904 PSM_SWVerMinor1 0 "0x0x0~0x7F:ASCII Code Value (HEX)" 127 "0x0x0~0x7F:ASCII Code Value (HEX)" ;
VAL_ 904 PSM_SWVerMinor2 0 "0x0x0~0x7F:ASCII Code Value (HEX)" 127 "0x0x0~0x7F:ASCII Code Value (HEX)" ;
VAL_ 904 PSM_DrvHeightPosition 0 "0x0x00~0xFE:POSITION" 254 "0x0x00~0xFE:POSITION" 255 "invalid" ;
VAL_ 904 PSM_DrvSlidePosition 0 "0x0x00~0xFE:POSITION" 254 "0x0x00~0xFE:POSITION" 255 "invalid" ;
VAL_ 904 PSM_EsyAcsGetOnSta 0 "off" 1 "on" 2 "Not Used" 3 "Error Indicator" ;
VAL_ 934 PTGM_HazardSta 0 "Off" 1 "On" 2 "Inactive" 3 "RESERVED" ;
VAL_ 934 PTGM_ModSta 0 "Power Mode" 1 "Manual Mode" 2 "RESERVED" 3 "Error Indicator" ;
VAL_ 934 PTGM_MovSta 0 "Stop" 1 "Moving" 2 "RESERVED" 3 "Error Indicator" ;
VAL_ 934 PTGM_OptTyp 0 "Off" 1 "On(PTG is applied)" 2 "RESERVED" 3 "Error Indicator" ;
VAL_ 934 PTGM_ReleaseRlySta 0 "Off" 1 "On" 2 "RESERVED" 3 "Error Indicator" ;
VAL_ 934 PTGM_TrnkLkSwSta 0 "Off" 1 "Close & Lock" 2 "RESERVED" 3 "Error Indicator" ;
VAL_ 934 PTGM_UsmSetSta 0 "Default" 1 "Power Mode" 2 "Manual Mode" 3 "Invalid" ;
VAL_ 934 PTGM_HeightRValue 0 "Default" 1 "Level1" 2 "Level2" 3 "Level3" 4 "Level4" 5 "RESERVED" 6 "User Setting" 7 "Invalid" ;
VAL_ 934 PTGM_OpnClsState 0 "Default" 1 "Closed" 2 "1 lvl open" 3 "2 lvl open" 4 "3 lvl open" 5 "4 lvl open" 6 "Full open" 7 "RESERVED" 8 "Closing operation" 9 "Opening operation" 10 "Position Error" 11 "RESERVED" 12 "RESERVED" 13 "RESERVED" 14 "RESERVED" 15 "Invalid" ;
VAL_ 934 PTGM_CmdWarn 0 "Default" 1 "Gear Not P or Vehicle speed" 2 "Obstacle detected" 3 "System temporary error" 4 "Power mode OFF" 5 "RESERVED" 6 "RESERVED" 7 "Invalid" ;
VAL_ 934 PTGM_AntiPinchSnsr 0 "Default" 1 "Applied" 2 "Not applied" 3 "Invalid" ;
VAL_ 934 PTGM_FobSrch_Req 0 "Off" 1 "Initial Srch Req" 2 "Srch Req After Detect" 3 "Invalid" ;
VAL_ 934 PTGM_TlgtAwayCloseRValue 0 "Default" 1 "Off" 2 "On" 3 "Invalid" ;
VAL_ 934 PTGM_TrnkTlgtOption 0 "Default" 1 "Power Trunk" 2 "Power Tailgate" 3 "Invalid" ;
VAL_ 934 PTGM_LatchType 0 "Default" 1 "Integrated Latch" 2 "Separated Latch" 3 "Invalid" ;
VAL_ 934 PTGM_SpeedRValue 0 "Default" 1 "Fast" 2 "Slow" 3 "Invalid" ;
VAL_ 924 RLPSU_FailState_PopUp 0 "Default" 1 "Relax Mode Position" 2 "Return Mode Position" 3 "Monitor Mode Position" 4 "Reading Mode Position" 5 "RESERVED" 6 "RESERVED" 7 "RESERVED" 8 "RESERVED" 9 "Mode-Fail (1st Seat Condition)" 10 "Mode-Fail (Side Sliding Limit SW Condition)" 11 "Mode-Fail (Vehicle Condition)" 12 "Mode-Fail (3rd Seat Condition)" 13 "Mode-Fail (Anti-Pinch)" 14 "Mode-Fail (Seat System Error)" 15 "Invalid" ;
VAL_ 924 RLPSU_Folding_State_Popup_EC 0 "Default" 1 "Folded(Finished)" 2 "Unfolded(Finished)" 3 "Mode-Fail(Anti-Pinch)" 4 "Mode-Fail(TGS&Break Condition)" 5 "Mode-Fail(System Error)" 6 "RESERVED" 7 "Invalid" ;
VAL_ 924 RLPSU_Relax_State_Popup_EC 0 "Default" 1 "Relaxed(Finished)" 2 "Unrelaxed(Finished)" 3 "Relax (Relaxing)" 4 "Return (Returning)" 5 "RESERVED" 6 "RESERVED" 7 "Invalid" ;
VAL_ 924 RLPSU_Reclining_State_Popup 0 "Default" 1 "Front Ended Position(Finished)" 2 "Rear Ended Position(Finished)" 3 "Mode-Fail(Anti-Pinch)" 4 "Mode-Fail(TGS & Break Condition)" 5 "Mode-Fail(System Error)" 6 "RESERVED" 7 "Invalid" ;
VAL_ 924 RL_AstStStdPosMovReq 0 "Default" 1 "ON" 2 "Reserved" 3 "Invalid" ;
VAL_ 922 RRPSU_FailState_PopUp 0 "Default" 1 "Relax Mode Position" 2 "Retrun Mode Position" 3 "Monitor Mode Position" 4 "Reading Mode Position" 5 "Unused" 6 "Unused" 7 "Unused" 8 "Unused" 9 "Mode-Fail (1st Seat Condition)" 10 "Mode-Fail (Side Sliding Limit SW Unlocked)" 11 "Mode-Fail (Vehicle Condition)" 12 "Mode-Fail (3rd Seat Condition)" 13 "Mode-Fail (Anti-Pinch)" 14 "Mode-Fail (Seat System Error)" 15 "Invalid" ;
VAL_ 922 RRPSU_Folding_State_Popup_EC 0 "Default" 1 "Relaxed(Finished)" 2 "Unfolded(Finished)" 3 "Mode-Fail(Anti-Pinch)" 4 "Mode-Fail(TGS&Break Condition)" 5 "Mode-Fail(System Error)" 6 "Unused" 7 "Invalid" ;
VAL_ 922 RRPSU_Relax_State_Popup_EC 0 "Default" 1 "Relaxed(Finished)" 2 "UnRelaxed(Finished)" 3 "Relax (Relaxing)" 4 "Return(Returning)" 5 "Unused" 6 "Unused" 7 "Invalid" ;
VAL_ 922 RRPSU_Reclining_State_Popup 0 "Default" 1 "Front Ended Position(Finished)" 2 "Rear Eeded Position(Finished)" 3 "Mode-Fail(Anti-Pinch)" 4 "Mode-Fail(TGS & Brake Condition)" 5 "Mode-Fail(System Error)" 6 "Unused" 7 "Invalid" ;
VAL_ 922 RR_AstStStdPosMovReq 0 "Default" 1 "ON" 2 "Reserved" 3 "Invalid" ;
VAL_ 905 RR_CrashUnlockCmd 0 "Off" 1 "Unlock (Crash)" ;
VAL_ 905 Warn_RrRtDrSwSta_SBCM 0 "Close" 1 "Open" 2 "RESERVED" 3 "Error Indicator" ;
VAL_ 905 DoorLock_RrRtDrUnLkSta_SBCM 0 "Lock" 1 "Unlock" 2 "Not Used" 3 "Error Indicator" ;
VAL_ 905 RR_SEAActivated 0 "InActivated" 1 "Activated" 2 "Not Used" 3 "Error Indicator" ;
VAL_ 905 RR_SEAWarn 0 "SEA Right Warning OFF" 1 "SEA Right Warning ON" 2 "Reserved" 3 "Invalid" ;
VAL_ 905 RR_SEWWarn 0 "SEW Right Warning OFF" 1 "SEW Right Warning ON" 2 "Reserved" 3 "Invalid" ;
VAL_ 905 RR_ReleaseWarn 0 "Release Warning OFF" 1 "Release Warning ON" 2 "Reserved" 3 "Invalid" ;
VAL_ 905 RR_SWFailAlarm 0 "Off" 1 "On" 2 "Not Used" 3 "Error Indicator" ;
VAL_ 905 RR_ChildLock_ActnFlSta 0 "OK" 1 "Failed" 2 "Not Used" 3 "Error Indicator" ;
VAL_ 905 RR_MRActivationAlarm 0 "Off" 1 "On" 2 "Not Used" 3 "Error Indicator" ;
VAL_ 905 RR_ChildLock_Status 0 "ChildLock On" 1 "ChildLock Off" 2 "RESERVED" 3 "RESERVED" ;
VAL_ 905 USM_RRGhostDoorSta 0 "Default" 1 "Off" 2 "On" 3 "Invalid" ;
VAL_ 905 DoorLock_PDSLkSwSta_RR 0 "Lock" 1 "Unlock" 2 "Not Used" 3 "Error Indicator" ;
VAL_ 905 PDS_TypeOption_RR 0 "Off" 1 "On" 2 "Not Used" 3 "Error Indicator" ;
VAL_ 905 RRDoorPushAlarm 0 "Off" 1 "On" 2 "Not Used" 3 "Error Indicator" ;
VAL_ 929 SCM_Opt 0 "Default" 1 "SCM" 2 "Not Used" 3 "Error Indicator" ;
VAL_ 929 Tilt_VirtualLimExist 0 "Off" 1 "On" 2 "Not Used" 3 "Error Indicator" ;
VAL_ 929 Tele_Snsr_Err 0 "Off" 1 "On" 2 "Not Used" 3 "Error Indicator" ;
VAL_ 929 Tele_VirtualLim 0 "Off" 1 "Fwd" 2 "Bwd" 3 "Error Indicator" ;
VAL_ 929 Tele_VirtualLimExist 0 "Off" 1 "On" 2 "Not Used" 3 "Error Indicator" ;
VAL_ 929 TiltTele_Profile1MemoryExist 0 "Off" 1 "On" 2 "Not Used" 3 "Error Indicator" ;
VAL_ 929 Tilt_MnlSwSta 0 "Off" 1 "Up" 2 "Down" 3 "Error Indicator" ;
VAL_ 929 TiltTele_Profile2MemoryExist 0 "Off" 1 "On" 2 "Not Used" 3 "Error Indicator" ;
VAL_ 929 TiltTele_GuestMemoryExist 0 "Off" 1 "On" 2 "Not Used" 3 "Error Indicator" ;
VAL_ 929 TiltTele_IMS1MemoryExist 0 "Off" 1 "On" 2 "Not Used" 3 "Error Indicator" ;
VAL_ 929 TiltTele_IMS2MemoryExist 0 "Off" 1 "On" 2 "Not Used" 3 "Error Indicator" ;
VAL_ 929 TiltTele_IMS3MemoryExist 0 "Off" 1 "On" 2 "Not Used" 3 "Error Indicator" ;
VAL_ 929 TiltTele_ReturnMemoryExist 0 "Off" 1 "On" 2 "Not Used" 3 "Error Indicator" ;
VAL_ 929 Tilt_OpSta 0 "Off" 1 "On" 2 "Moving Restrict" 3 "Error Indicator" ;
VAL_ 929 Tele_OpSta 0 "Off" 1 "On" 2 "Moving Restrict" 3 "Error Indicator" ;
VAL_ 929 Tele_MnlSwSta 0 "Off" 1 "Fwd" 2 "Bwd" 3 "Error Indicator" ;
VAL_ 929 Tilt_SnsrErr 0 "Off" 1 "On" 2 "Not Used" 3 "Error Indicator" ;
VAL_ 929 Tilt_VirtualLim 0 "Off" 1 "Up" 2 "Down" 3 "Error Indicator" ;
